VERSION ""

NS_ :

BS_:

BU_: Device Host

BO_ 2582846206 IoStatusFaultCountFD: 64 Device
 SG_ FaultCountStatus_01 : 0|16@1+ (1,0) [0|64255] ""  Host
 SG_ FaultCountStatus_02 : 16|16@1+ (1,0) [0|64255] ""  Host
 SG_ FaultCountStatus_03 : 32|16@1+ (1,0) [0|64255] ""  Host
 SG_ FaultCountStatus_04 : 48|16@1+ (1,0) [0|64255] ""  Host
 SG_ FaultCountStatus_05 : 64|16@1+ (1,0) [0|64255] ""  Host
 SG_ FaultCountStatus_06 : 80|16@1+ (1,0) [0|64255] ""  Host
 SG_ FaultCountStatus_07 : 96|16@1+ (1,0) [0|64255] ""  Host
 SG_ FaultCountStatus_08 : 112|16@1+ (1,0) [0|64255] ""  Host
 SG_ FaultCountStatus_09 : 128|16@1+ (1,0) [0|64255] ""  Host
 SG_ FaultCountStatus_10 : 144|16@1+ (1,0) [0|64255] ""  Host
 SG_ FaultCountStatus_11 : 160|16@1+ (1,0) [0|64255] ""  Host
 SG_ FaultCountStatus_12 : 176|16@1+ (1,0) [0|64255] ""  Host
 SG_ FaultCountStatus_13 : 192|16@1+ (1,0) [0|64255] ""  Host
 SG_ FaultCountStatus_14 : 208|16@1+ (1,0) [0|64255] ""  Host
 SG_ FaultCountStatus_15 : 224|16@1+ (1,0) [0|64255] ""  Host
 SG_ FaultCountStatus_16 : 240|16@1+ (1,0) [0|64255] ""  Host
 SG_ FaultCountStatus_17 : 256|16@1+ (1,0) [0|64255] ""  Host
 SG_ FaultCountStatus_18 : 272|16@1+ (1,0) [0|64255] ""  Host
 SG_ FaultCountStatus_19 : 288|16@1+ (1,0) [0|64255] ""  Host
 SG_ FaultCountStatus_20 : 304|16@1+ (1,0) [0|64255] ""  Host
 SG_ FaultCountStatus_21 : 320|16@1+ (1,0) [0|64255] ""  Host
 SG_ FaultCountStatus_22 : 336|16@1+ (1,0) [0|64255] ""  Host
 SG_ FaultCountStatus_23 : 352|16@1+ (1,0) [0|64255] ""  Host
 SG_ FaultCountStatus_24 : 368|16@1+ (1,0) [0|64255] ""  Host
 SG_ FaultCountStatus_25 : 384|16@1+ (1,0) [0|64255] ""  Host
 SG_ FaultCountStatus_26 : 400|16@1+ (1,0) [0|64255] ""  Host
 SG_ FaultCountStatus_27 : 416|16@1+ (1,0) [0|64255] ""  Host
 SG_ FaultCountStatus_28 : 432|16@1+ (1,0) [0|64255] ""  Host
 SG_ FaultCountStatus_29 : 448|16@1+ (1,0) [0|64255] ""  Host
 SG_ FaultCountStatus_30 : 464|16@1+ (1,0) [0|64255] ""  Host
 SG_ FaultCountStatus_31 : 480|16@1+ (1,0) [0|64255] ""  Host
 SG_ FaultCountStatus_32 : 496|16@1+ (1,0) [0|64255] ""  Host

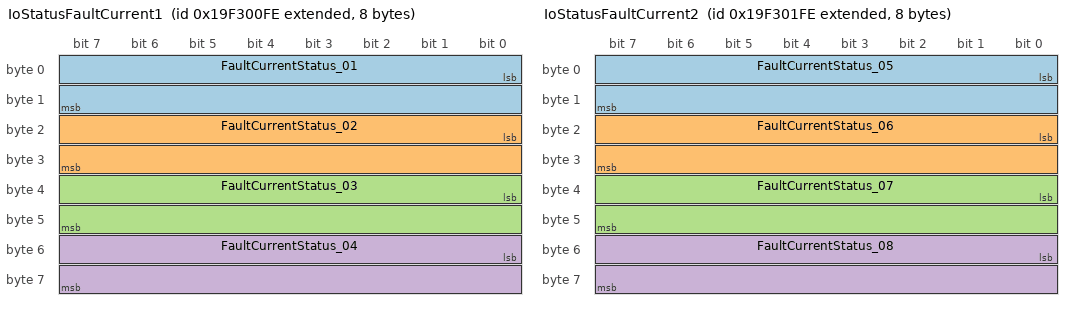
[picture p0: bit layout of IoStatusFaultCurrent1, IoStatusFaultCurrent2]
BO_ 2582839550 IoStatusFaultCurrent1: 8 Device
 SG_ FaultCurrentStatus_01 : 0|16@1+ (0.01,-320) [-320|320] "A"  Host
 SG_ FaultCurrentStatus_02 : 16|16@1+ (0.01,-320) [-320|320] "A"  Host
 SG_ FaultCurrentStatus_03 : 32|16@1+ (0.01,-320) [-320|320] "A"  Host
 SG_ FaultCurrentStatus_04 : 48|16@1+ (0.01,-320) [-320|320] "A"  Host

BO_ 2582839806 IoStatusFaultCurrent2: 8 Device
 SG_ FaultCurrentStatus_05 : 0|16@1+ (0.01,-320) [-320|320] "A"  Host
 SG_ FaultCurrentStatus_06 : 16|16@1+ (0.01,-320) [-320|320] "A"  Host
 SG_ FaultCurrentStatus_07 : 32|16@1+ (0.01,-320) [-320|320] "A"  Host
 SG_ FaultCurrentStatus_08 : 48|16@1+ (0.01,-320) [-320|320] "A"  Host

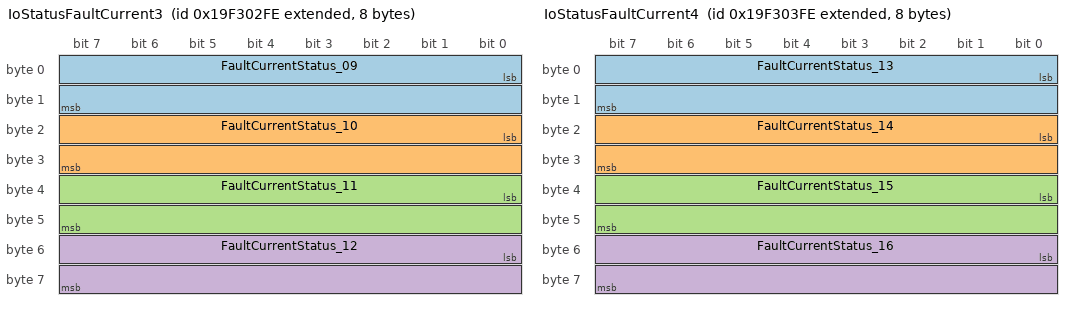
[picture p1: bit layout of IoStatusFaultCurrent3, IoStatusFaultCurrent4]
BO_ 2582840062 IoStatusFaultCurrent3: 8 Device
 SG_ FaultCurrentStatus_09 : 0|16@1+ (0.01,-320) [-320|320] "A"  Host
 SG_ FaultCurrentStatus_10 : 16|16@1+ (0.01,-320) [-320|320] "A"  Host
 SG_ FaultCurrentStatus_11 : 32|16@1+ (0.01,-320) [-320|320] "A"  Host
 SG_ FaultCurrentStatus_12 : 48|16@1+ (0.01,-320) [-320|320] "A"  Host

BO_ 2582840318 IoStatusFaultCurrent4: 8 Device
 SG_ FaultCurrentStatus_13 : 0|16@1+ (0.01,-320) [-320|320] "A"  Host
 SG_ FaultCurrentStatus_14 : 16|16@1+ (0.01,-320) [-320|320] "A"  Host
 SG_ FaultCurrentStatus_15 : 32|16@1+ (0.01,-320) [-320|320] "A"  Host
 SG_ FaultCurrentStatus_16 : 48|16@1+ (0.01,-320) [-320|320] "A"  Host

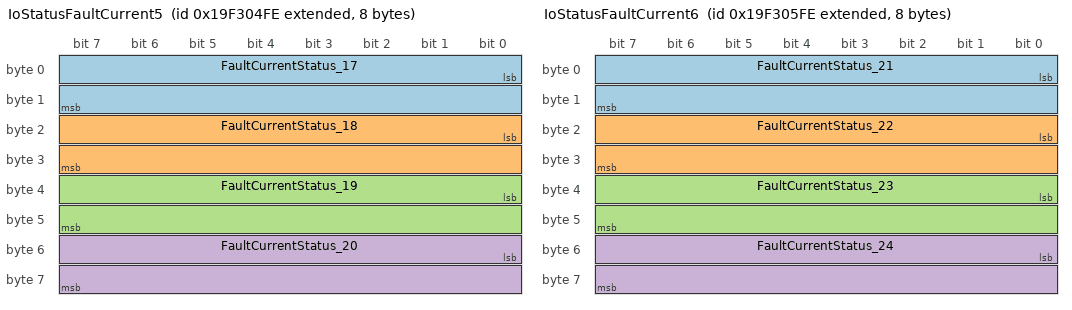
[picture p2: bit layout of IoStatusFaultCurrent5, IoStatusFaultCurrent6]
BO_ 2582840574 IoStatusFaultCurrent5: 8 Device
 SG_ FaultCurrentStatus_17 : 0|16@1+ (0.01,-320) [-320|320] "A"  Host
 SG_ FaultCurrentStatus_18 : 16|16@1+ (0.01,-320) [-320|320] "A"  Host
 SG_ FaultCurrentStatus_19 : 32|16@1+ (0.01,-320) [-320|320] "A"  Host
 SG_ FaultCurrentStatus_20 : 48|16@1+ (0.01,-320) [-320|320] "A"  Host

BO_ 2582840830 IoStatusFaultCurrent6: 8 Device
 SG_ FaultCurrentStatus_21 : 0|16@1+ (0.01,-320) [-320|320] "A"  Host
 SG_ FaultCurrentStatus_22 : 16|16@1+ (0.01,-320) [-320|320] "A"  Host
 SG_ FaultCurrentStatus_23 : 32|16@1+ (0.01,-320) [-320|320] "A"  Host
 SG_ FaultCurrentStatus_24 : 48|16@1+ (0.01,-320) [-320|320] "A"  Host

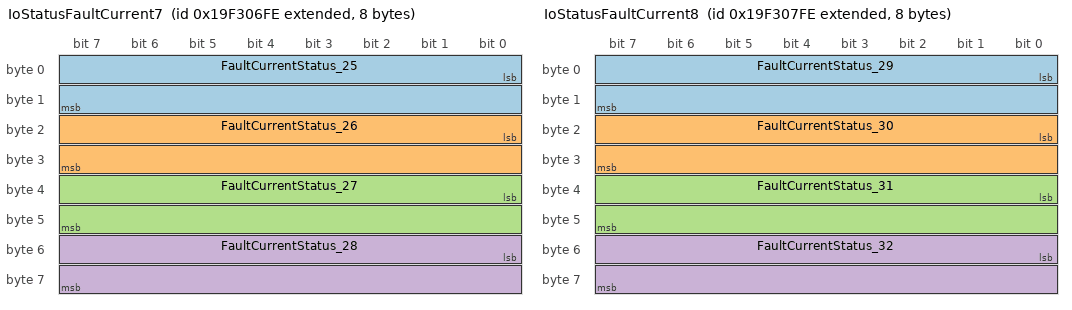
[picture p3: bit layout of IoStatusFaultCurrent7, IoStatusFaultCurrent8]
BO_ 2582841086 IoStatusFaultCurrent7: 8 Device
 SG_ FaultCurrentStatus_25 : 0|16@1+ (0.01,-320) [-320|320] "A"  Host
 SG_ FaultCurrentStatus_26 : 16|16@1+ (0.01,-320) [-320|320] "A"  Host
 SG_ FaultCurrentStatus_27 : 32|16@1+ (0.01,-320) [-320|320] "A"  Host
 SG_ FaultCurrentStatus_28 : 48|16@1+ (0.01,-320) [-320|320] "A"  Host

BO_ 2582841342 IoStatusFaultCurrent8: 8 Device
 SG_ FaultCurrentStatus_29 : 0|16@1+ (0.01,-320) [-320|320] "A"  Host
 SG_ FaultCurrentStatus_30 : 16|16@1+ (0.01,-320) [-320|320] "A"  Host
 SG_ FaultCurrentStatus_31 : 32|16@1+ (0.01,-320) [-320|320] "A"  Host
 SG_ FaultCurrentStatus_32 : 48|16@1+ (0.01,-320) [-320|320] "A"  Host

BO_ 2582846462 IoStatusFaultCurrentFD: 64 Device
 SG_ FaultCurrentStatus_01 : 0|16@1+ (0.01,-320) [-320|320] "A"  Host
 SG_ FaultCurrentStatus_02 : 16|16@1+ (0.01,-320) [-320|320] "A"  Host
 SG_ FaultCurrentStatus_03 : 32|16@1+ (0.01,-320) [-320|320] "A"  Host
 SG_ FaultCurrentStatus_04 : 48|16@1+ (0.01,-320) [-320|320] "A"  Host
 SG_ FaultCurrentStatus_05 : 64|16@1+ (0.01,-320) [-320|320] "A"  Host
 SG_ FaultCurrentStatus_06 : 80|16@1+ (0.01,-320) [-320|320] "A"  Host
 SG_ FaultCurrentStatus_07 : 96|16@1+ (0.01,-320) [-320|320] "A"  Host
 SG_ FaultCurrentStatus_08 : 112|16@1+ (0.01,-320) [-320|320] "A"  Host
 SG_ FaultCurrentStatus_09 : 128|16@1+ (0.01,-320) [-320|320] "A"  Host
 SG_ FaultCurrentStatus_10 : 144|16@1+ (0.01,-320) [-320|320] "A"  Host
 SG_ FaultCurrentStatus_11 : 160|16@1+ (0.01,-320) [-320|320] "A"  Host
 SG_ FaultCurrentStatus_12 : 176|16@1+ (0.01,-320) [-320|320] "A"  Host
 SG_ FaultCurrentStatus_13 : 192|16@1+ (0.01,-320) [-320|320] "A"  Host
 SG_ FaultCurrentStatus_14 : 208|16@1+ (0.01,-320) [-320|320] "A"  Host
 SG_ FaultCurrentStatus_15 : 224|16@1+ (0.01,-320) [-320|320] "A"  Host
 SG_ FaultCurrentStatus_16 : 240|16@1+ (0.01,-320) [-320|320] "A"  Host
 SG_ FaultCurrentStatus_17 : 256|16@1+ (0.01,-320) [-320|320] "A"  Host
 SG_ FaultCurrentStatus_18 : 272|16@1+ (0.01,-320) [-320|320] "A"  Host
 SG_ FaultCurrentStatus_19 : 288|16@1+ (0.01,-320) [-320|320] "A"  Host
 SG_ FaultCurrentStatus_20 : 304|16@1+ (0.01,-320) [-320|320] "A"  Host
 SG_ FaultCurrentStatus_21 : 320|16@1+ (0.01,-320) [-320|320] "A"  Host
 SG_ FaultCurrentStatus_22 : 336|16@1+ (0.01,-320) [-320|320] "A"  Host
 SG_ FaultCurrentStatus_23 : 352|16@1+ (0.01,-320) [-320|320] "A"  Host
 SG_ FaultCurrentStatus_24 : 368|16@1+ (0.01,-320) [-320|320] "A"  Host
 SG_ FaultCurrentStatus_25 : 384|16@1+ (0.01,-320) [-320|320] "A"  Host
 SG_ FaultCurrentStatus_26 : 400|16@1+ (0.01,-320) [-320|320] "A"  Host
 SG_ FaultCurrentStatus_27 : 416|16@1+ (0.01,-320) [-320|320] "A"  Host
 SG_ FaultCurrentStatus_28 : 432|16@1+ (0.01,-320) [-320|320] "A"  Host
 SG_ FaultCurrentStatus_29 : 448|16@1+ (0.01,-320) [-320|320] "A"  Host
 SG_ FaultCurrentStatus_30 : 464|16@1+ (0.01,-320) [-320|320] "A"  Host
 SG_ FaultCurrentStatus_31 : 480|16@1+ (0.01,-320) [-320|320] "A"  Host
 SG_ FaultCurrentStatus_32 : 496|16@1+ (0.01,-320) [-320|320] "A"  Host

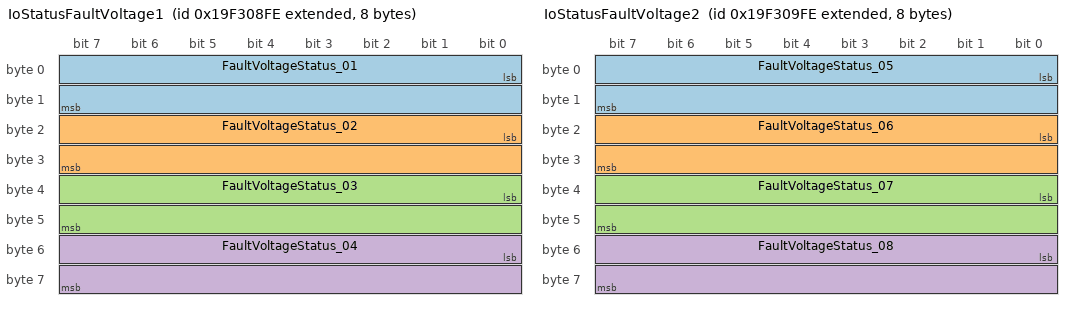
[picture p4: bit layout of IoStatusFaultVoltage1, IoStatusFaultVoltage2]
BO_ 2582841598 IoStatusFaultVoltage1: 8 Device
 SG_ FaultVoltageStatus_01 : 0|16@1+ (0.001,0) [0|64.255] "V"  Host
 SG_ FaultVoltageStatus_02 : 16|16@1+ (0.001,0) [0|64.255] "V"  Host
 SG_ FaultVoltageStatus_03 : 32|16@1+ (0.001,0) [0|64.255] "V"  Host
 SG_ FaultVoltageStatus_04 : 48|16@1+ (0.001,0) [0|64.255] "V"  Host

BO_ 2582841854 IoStatusFaultVoltage2: 8 Device
 SG_ FaultVoltageStatus_05 : 0|16@1+ (0.001,0) [0|64.255] "V"  Host
 SG_ FaultVoltageStatus_06 : 16|16@1+ (0.001,0) [0|64.255] "V"  Host
 SG_ FaultVoltageStatus_07 : 32|16@1+ (0.001,0) [0|64.255] "V"  Host
 SG_ FaultVoltageStatus_08 : 48|16@1+ (0.001,0) [0|64.255] "V"  Host

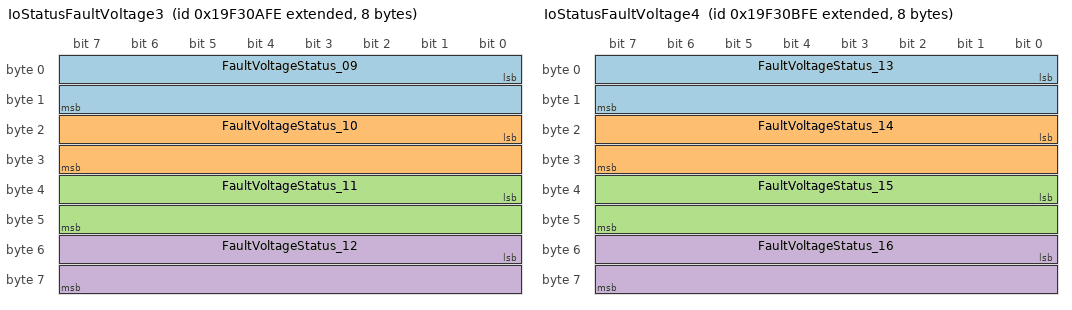
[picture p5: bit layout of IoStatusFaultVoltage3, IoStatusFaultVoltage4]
BO_ 2582842110 IoStatusFaultVoltage3: 8 Device
 SG_ FaultVoltageStatus_09 : 0|16@1+ (0.001,0) [0|64.255] "V"  Host
 SG_ FaultVoltageStatus_10 : 16|16@1+ (0.001,0) [0|64.255] "V"  Host
 SG_ FaultVoltageStatus_11 : 32|16@1+ (0.001,0) [0|64.255] "V"  Host
 SG_ FaultVoltageStatus_12 : 48|16@1+ (0.001,0) [0|64.255] "V"  Host

BO_ 2582842366 IoStatusFaultVoltage4: 8 Device
 SG_ FaultVoltageStatus_13 : 0|16@1+ (0.001,0) [0|64.255] "V"  Host
 SG_ FaultVoltageStatus_14 : 16|16@1+ (0.001,0) [0|64.255] "V"  Host
 SG_ FaultVoltageStatus_15 : 32|16@1+ (0.001,0) [0|64.255] "V"  Host
 SG_ FaultVoltageStatus_16 : 48|16@1+ (0.001,0) [0|64.255] "V"  Host

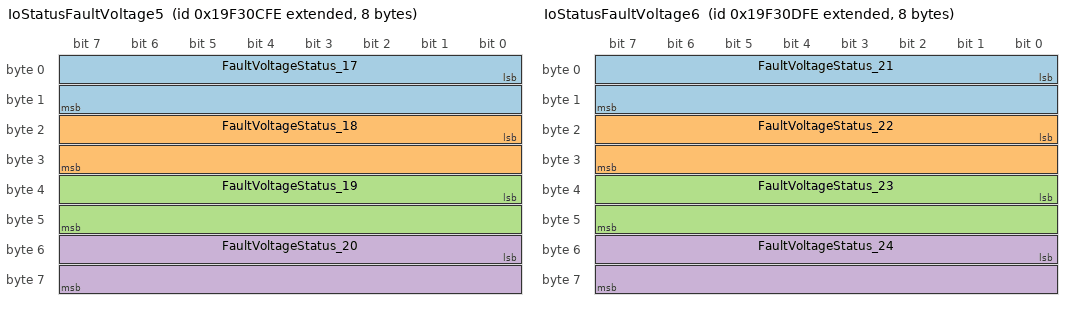
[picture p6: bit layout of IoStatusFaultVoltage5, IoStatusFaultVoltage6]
BO_ 2582842622 IoStatusFaultVoltage5: 8 Device
 SG_ FaultVoltageStatus_17 : 0|16@1+ (0.001,0) [0|64.255] "V"  Host
 SG_ FaultVoltageStatus_18 : 16|16@1+ (0.001,0) [0|64.255] "V"  Host
 SG_ FaultVoltageStatus_19 : 32|16@1+ (0.001,0) [0|64.255] "V"  Host
 SG_ FaultVoltageStatus_20 : 48|16@1+ (0.001,0) [0|64.255] "V"  Host

BO_ 2582842878 IoStatusFaultVoltage6: 8 Device
 SG_ FaultVoltageStatus_21 : 0|16@1+ (0.001,0) [0|64.255] "V"  Host
 SG_ FaultVoltageStatus_22 : 16|16@1+ (0.001,0) [0|64.255] "V"  Host
 SG_ FaultVoltageStatus_23 : 32|16@1+ (0.001,0) [0|64.255] "V"  Host
 SG_ FaultVoltageStatus_24 : 48|16@1+ (0.001,0) [0|64.255] "V"  Host

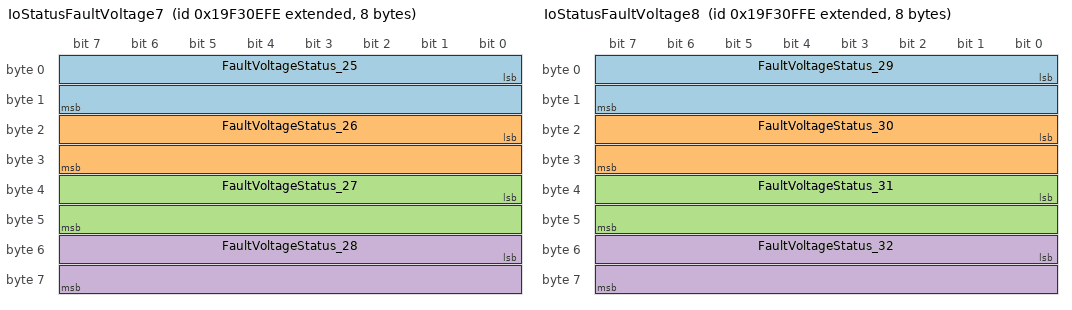
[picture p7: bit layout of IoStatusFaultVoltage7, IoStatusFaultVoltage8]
BO_ 2582843134 IoStatusFaultVoltage7: 8 Device
 SG_ FaultVoltageStatus_25 : 0|16@1+ (0.001,0) [0|64.255] "V"  Host
 SG_ FaultVoltageStatus_26 : 16|16@1+ (0.001,0) [0|64.255] "V"  Host
 SG_ FaultVoltageStatus_27 : 32|16@1+ (0.001,0) [0|64.255] "V"  Host
 SG_ FaultVoltageStatus_28 : 48|16@1+ (0.001,0) [0|64.255] "V"  Host

BO_ 2582843390 IoStatusFaultVoltage8: 8 Device
 SG_ FaultVoltageStatus_29 : 0|16@1+ (0.001,0) [0|64.255] "V"  Host
 SG_ FaultVoltageStatus_30 : 16|16@1+ (0.001,0) [0|64.255] "V"  Host
 SG_ FaultVoltageStatus_31 : 32|16@1+ (0.001,0) [0|64.255] "V"  Host
 SG_ FaultVoltageStatus_32 : 48|16@1+ (0.001,0) [0|64.255] "V"  Host

BO_ 2582846718 IoStatusFaultVoltageFD: 64 Device
 SG_ FaultVoltageStatus_01 : 0|16@1+ (0.001,0) [0|64.255] "V"  Host
 SG_ FaultVoltageStatus_02 : 16|16@1+ (0.001,0) [0|64.255] "V"  Host
 SG_ FaultVoltageStatus_03 : 32|16@1+ (0.001,0) [0|64.255] "V"  Host
 SG_ FaultVoltageStatus_04 : 48|16@1+ (0.001,0) [0|64.255] "V"  Host
 SG_ FaultVoltageStatus_05 : 64|16@1+ (0.001,0) [0|64.255] "V"  Host
 SG_ FaultVoltageStatus_06 : 80|16@1+ (0.001,0) [0|64.255] "V"  Host
 SG_ FaultVoltageStatus_07 : 96|16@1+ (0.001,0) [0|64.255] "V"  Host
 SG_ FaultVoltageStatus_08 : 112|16@1+ (0.001,0) [0|64.255] "V"  Host
 SG_ FaultVoltageStatus_09 : 128|16@1+ (0.001,0) [0|64.255] "V"  Host
 SG_ FaultVoltageStatus_10 : 144|16@1+ (0.001,0) [0|64.255] "V"  Host
 SG_ FaultVoltageStatus_11 : 160|16@1+ (0.001,0) [0|64.255] "V"  Host
 SG_ FaultVoltageStatus_12 : 176|16@1+ (0.001,0) [0|64.255] "V"  Host
 SG_ FaultVoltageStatus_13 : 192|16@1+ (0.001,0) [0|64.255] "V"  Host
 SG_ FaultVoltageStatus_14 : 208|16@1+ (0.001,0) [0|64.255] "V"  Host
 SG_ FaultVoltageStatus_15 : 224|16@1+ (0.001,0) [0|64.255] "V"  Host
 SG_ FaultVoltageStatus_16 : 240|16@1+ (0.001,0) [0|64.255] "V"  Host
 SG_ FaultVoltageStatus_17 : 256|16@1+ (0.001,0) [0|64.255] "V"  Host
 SG_ FaultVoltageStatus_18 : 272|16@1+ (0.001,0) [0|64.255] "V"  Host
 SG_ FaultVoltageStatus_19 : 288|16@1+ (0.001,0) [0|64.255] "V"  Host
 SG_ FaultVoltageStatus_20 : 304|16@1+ (0.001,0) [0|64.255] "V"  Host
 SG_ FaultVoltageStatus_21 : 320|16@1+ (0.001,0) [0|64.255] "V"  Host
 SG_ FaultVoltageStatus_22 : 336|16@1+ (0.001,0) [0|64.255] "V"  Host
 SG_ FaultVoltageStatus_23 : 352|16@1+ (0.001,0) [0|64.255] "V"  Host
 SG_ FaultVoltageStatus_24 : 368|16@1+ (0.001,0) [0|64.255] "V"  Host
 SG_ FaultVoltageStatus_25 : 384|16@1+ (0.001,0) [0|64.255] "V"  Host
 SG_ FaultVoltageStatus_26 : 400|16@1+ (0.001,0) [0|64.255] "V"  Host
 SG_ FaultVoltageStatus_27 : 416|16@1+ (0.001,0) [0|64.255] "V"  Host
 SG_ FaultVoltageStatus_28 : 432|16@1+ (0.001,0) [0|64.255] "V"  Host
 SG_ FaultVoltageStatus_29 : 448|16@1+ (0.001,0) [0|64.255] "V"  Host
 SG_ FaultVoltageStatus_30 : 464|16@1+ (0.001,0) [0|64.255] "V"  Host
 SG_ FaultVoltageStatus_31 : 480|16@1+ (0.001,0) [0|64.255] "V"  Host
 SG_ FaultVoltageStatus_32 : 496|16@1+ (0.001,0) [0|64.255] "V"  Host

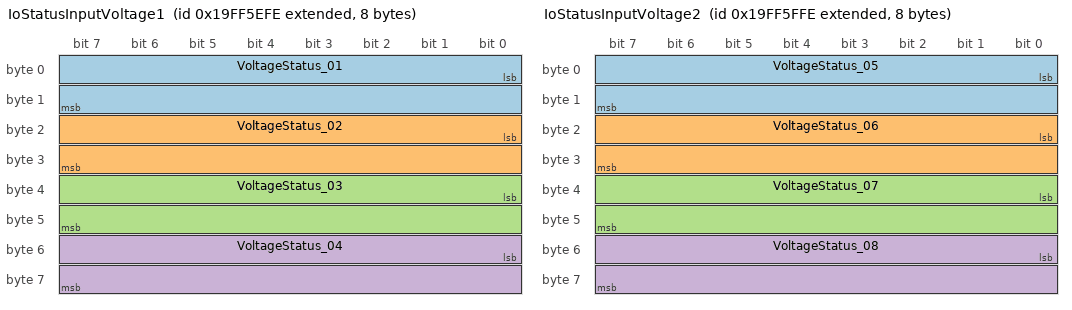
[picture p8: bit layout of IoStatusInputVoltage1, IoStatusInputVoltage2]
BO_ 2583650046 IoStatusInputVoltage1: 8 Device
 SG_ VoltageStatus_01 : 0|16@1+ (0.001,0) [0|64.255] "V"  Host
 SG_ VoltageStatus_02 : 16|16@1+ (0.001,0) [0|64.255] "V"  Host
 SG_ VoltageStatus_03 : 32|16@1+ (0.001,0) [0|64.255] "V"  Host
 SG_ VoltageStatus_04 : 48|16@1+ (0.001,0) [0|64.255] "V"  Host

BO_ 2583650302 IoStatusInputVoltage2: 8 Device
 SG_ VoltageStatus_05 : 0|16@1+ (0.001,0) [0|64.255] "V"  Host
 SG_ VoltageStatus_06 : 16|16@1+ (0.001,0) [0|64.255] "V"  Host
 SG_ VoltageStatus_07 : 32|16@1+ (0.001,0) [0|64.255] "V"  Host
 SG_ VoltageStatus_08 : 48|16@1+ (0.001,0) [0|64.255] "V"  Host

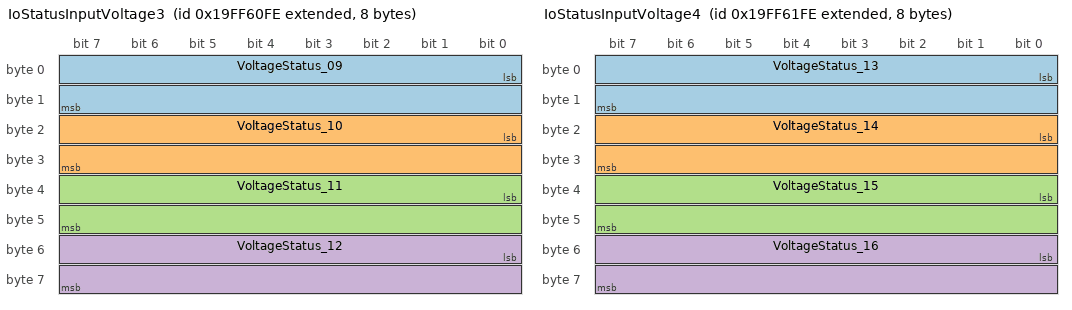
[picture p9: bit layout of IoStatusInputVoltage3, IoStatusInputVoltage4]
BO_ 2583650558 IoStatusInputVoltage3: 8 Device
 SG_ VoltageStatus_09 : 0|16@1+ (0.001,0) [0|64.255] "V"  Host
 SG_ VoltageStatus_10 : 16|16@1+ (0.001,0) [0|64.255] "V"  Host
 SG_ VoltageStatus_11 : 32|16@1+ (0.001,0) [0|64.255] "V"  Host
 SG_ VoltageStatus_12 : 48|16@1+ (0.001,0) [0|64.255] "V"  Host

BO_ 2583650814 IoStatusInputVoltage4: 8 Device
 SG_ VoltageStatus_13 : 0|16@1+ (0.001,0) [0|64.255] "V"  Host
 SG_ VoltageStatus_14 : 16|16@1+ (0.001,0) [0|64.255] "V"  Host
 SG_ VoltageStatus_15 : 32|16@1+ (0.001,0) [0|64.255] "V"  Host
 SG_ VoltageStatus_16 : 48|16@1+ (0.001,0) [0|64.255] "V"  Host

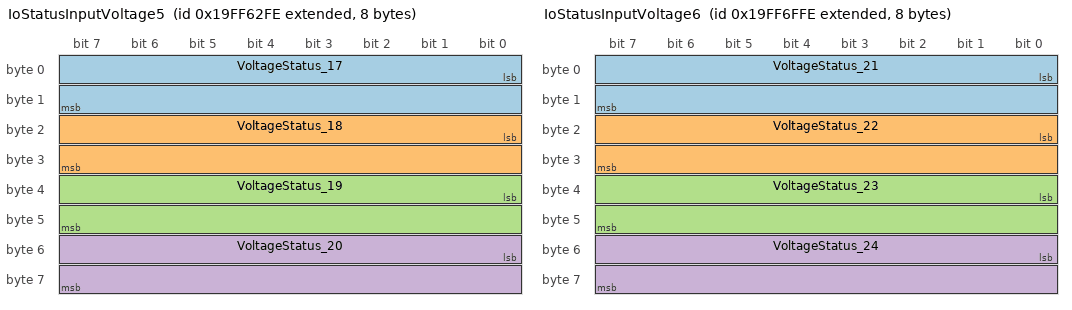
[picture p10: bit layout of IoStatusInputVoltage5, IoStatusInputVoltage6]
BO_ 2583651070 IoStatusInputVoltage5: 8 Device
 SG_ VoltageStatus_17 : 0|16@1+ (0.001,0) [0|64.255] "V"  Host
 SG_ VoltageStatus_18 : 16|16@1+ (0.001,0) [0|64.255] "V"  Host
 SG_ VoltageStatus_19 : 32|16@1+ (0.001,0) [0|64.255] "V"  Host
 SG_ VoltageStatus_20 : 48|16@1+ (0.001,0) [0|64.255] "V"  Host

BO_ 2583654398 IoStatusInputVoltage6: 8 Device
 SG_ VoltageStatus_21 : 0|16@1+ (0.001,0) [0|64.255] "V"  Host
 SG_ VoltageStatus_22 : 16|16@1+ (0.001,0) [0|64.255] "V"  Host
 SG_ VoltageStatus_23 : 32|16@1+ (0.001,0) [0|64.255] "V"  Host
 SG_ VoltageStatus_24 : 48|16@1+ (0.001,0) [0|64.255] "V"  Host

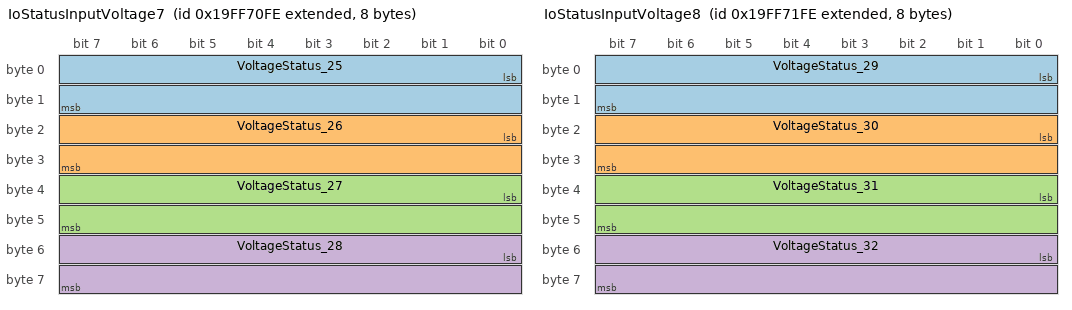
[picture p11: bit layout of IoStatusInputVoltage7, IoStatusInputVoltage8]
BO_ 2583654654 IoStatusInputVoltage7: 8 Device
 SG_ VoltageStatus_25 : 0|16@1+ (0.001,0) [0|64.255] "V"  Host
 SG_ VoltageStatus_26 : 16|16@1+ (0.001,0) [0|64.255] "V"  Host
 SG_ VoltageStatus_27 : 32|16@1+ (0.001,0) [0|64.255] "V"  Host
 SG_ VoltageStatus_28 : 48|16@1+ (0.001,0) [0|64.255] "V"  Host

BO_ 2583654910 IoStatusInputVoltage8: 8 Device
 SG_ VoltageStatus_29 : 0|16@1+ (0.001,0) [0|64.255] "V"  Host
 SG_ VoltageStatus_30 : 16|16@1+ (0.001,0) [0|64.255] "V"  Host
 SG_ VoltageStatus_31 : 32|16@1+ (0.001,0) [0|64.255] "V"  Host
 SG_ VoltageStatus_32 : 48|16@1+ (0.001,0) [0|64.255] "V"  Host

BO_ 2582845694 IoStatusInputVoltageFD: 64 Device
 SG_ VoltageStatus_01 : 0|16@1+ (0.001,0) [0|64.255] "V"  Host
 SG_ VoltageStatus_02 : 16|16@1+ (0.001,0) [0|64.255] "V"  Host
 SG_ VoltageStatus_03 : 32|16@1+ (0.001,0) [0|64.255] "V"  Host
 SG_ VoltageStatus_04 : 48|16@1+ (0.001,0) [0|64.255] "V"  Host
 SG_ VoltageStatus_05 : 64|16@1+ (0.001,0) [0|64.255] "V"  Host
 SG_ VoltageStatus_06 : 80|16@1+ (0.001,0) [0|64.255] "V"  Host
 SG_ VoltageStatus_07 : 96|16@1+ (0.001,0) [0|64.255] "V"  Host
 SG_ VoltageStatus_08 : 112|16@1+ (0.001,0) [0|64.255] "V"  Host
 SG_ VoltageStatus_09 : 128|16@1+ (0.001,0) [0|64.255] "V"  Host
 SG_ VoltageStatus_10 : 144|16@1+ (0.001,0) [0|64.255] "V"  Host
 SG_ VoltageStatus_11 : 160|16@1+ (0.001,0) [0|64.255] "V"  Host
 SG_ VoltageStatus_12 : 176|16@1+ (0.001,0) [0|64.255] "V"  Host
 SG_ VoltageStatus_13 : 192|16@1+ (0.001,0) [0|64.255] "V"  Host
 SG_ VoltageStatus_14 : 208|16@1+ (0.001,0) [0|64.255] "V"  Host
 SG_ VoltageStatus_15 : 224|16@1+ (0.001,0) [0|64.255] "V"  Host
 SG_ VoltageStatus_16 : 240|16@1+ (0.001,0) [0|64.255] "V"  Host
 SG_ VoltageStatus_17 : 256|16@1+ (0.001,0) [0|64.255] "V"  Host
 SG_ VoltageStatus_18 : 272|16@1+ (0.001,0) [0|64.255] "V"  Host
 SG_ VoltageStatus_19 : 288|16@1+ (0.001,0) [0|64.255] "V"  Host
 SG_ VoltageStatus_20 : 304|16@1+ (0.001,0) [0|64.255] "V"  Host
 SG_ VoltageStatus_21 : 320|16@1+ (0.001,0) [0|64.255] "V"  Host
 SG_ VoltageStatus_22 : 336|16@1+ (0.001,0) [0|64.255] "V"  Host
 SG_ VoltageStatus_23 : 352|16@1+ (0.001,0) [0|64.255] "V"  Host
 SG_ VoltageStatus_24 : 368|16@1+ (0.001,0) [0|64.255] "V"  Host
 SG_ VoltageStatus_25 : 384|16@1+ (0.001,0) [0|64.255] "V"  Host
 SG_ VoltageStatus_26 : 400|16@1+ (0.001,0) [0|64.255] "V"  Host
 SG_ VoltageStatus_27 : 416|16@1+ (0.001,0) [0|64.255] "V"  Host
 SG_ VoltageStatus_28 : 432|16@1+ (0.001,0) [0|64.255] "V"  Host
 SG_ VoltageStatus_29 : 448|16@1+ (0.001,0) [0|64.255] "V"  Host
 SG_ VoltageStatus_30 : 464|16@1+ (0.001,0) [0|64.255] "V"  Host
 SG_ VoltageStatus_31 : 480|16@1+ (0.001,0) [0|64.255] "V"  Host
 SG_ VoltageStatus_32 : 496|16@1+ (0.001,0) [0|64.255] "V"  Host

BO_ 2583646718 IoStatusPinMode1: 8 Device
 SG_ PinModeStatus_01 : 0|4@1+ (1,0) [0|0] ""  Host
 SG_ PinPullModeStatus_01 : 4|2@1+ (1,0) [0|0] ""  Host
 SG_ LoadDetectionStatus_01 : 6|2@1+ (1,0) [0|0] ""  Host
 SG_ PinModeStatus_02 : 8|4@1+ (1,0) [0|0] ""  Host
 SG_ PinPullModeStatus_02 : 12|2@1+ (1,0) [0|0] ""  Host
 SG_ LoadDetectionStatus_02 : 14|2@1+ (1,0) [0|0] ""  Host
 SG_ PinModeStatus_03 : 16|4@1+ (1,0) [0|0] ""  Host
 SG_ PinPullModeStatus_03 : 20|2@1+ (1,0) [0|0] ""  Host
 SG_ LoadDetectionStatus_03 : 22|2@1+ (1,0) [0|0] ""  Host
 SG_ PinModeStatus_04 : 24|4@1+ (1,0) [0|0] ""  Host
 SG_ PinPullModeStatus_04 : 28|2@1+ (1,0) [0|0] ""  Host
 SG_ LoadDetectionStatus_04 : 30|2@1+ (1,0) [0|0] ""  Host
 SG_ PinModeStatus_05 : 32|4@1+ (1,0) [0|0] ""  Host
 SG_ PinPullModeStatus_05 : 36|2@1+ (1,0) [0|0] ""  Host
 SG_ LoadDetectionStatus_05 : 38|2@1+ (1,0) [0|0] ""  Host
 SG_ PinModeStatus_06 : 40|4@1+ (1,0) [0|0] ""  Host
 SG_ PinPullModeStatus_06 : 44|2@1+ (1,0) [0|0] ""  Host
 SG_ LoadDetectionStatus_06 : 46|2@1+ (1,0) [0|0] ""  Host
 SG_ PinModeStatus_07 : 48|4@1+ (1,0) [0|0] ""  Host
 SG_ PinPullModeStatus_07 : 52|2@1+ (1,0) [0|0] ""  Host
 SG_ LoadDetectionStatus_07 : 54|2@1+ (1,0) [0|0] ""  Host
 SG_ PinModeStatus_08 : 56|4@1+ (1,0) [0|0] ""  Host
 SG_ PinPullModeStatus_08 : 60|2@1+ (1,0) [0|0] ""  Host
 SG_ LoadDetectionStatus_08 : 62|2@1+ (1,0) [0|0] ""  Host

BO_ 2583646974 IoStatusPinMode2: 8 Device
 SG_ PinModeStatus_09 : 0|4@1+ (1,0) [0|0] ""  Host
 SG_ PinPullModeStatus_09 : 4|2@1+ (1,0) [0|0] ""  Host
 SG_ LoadDetectionStatus_09 : 6|2@1+ (1,0) [0|0] ""  Host
 SG_ PinModeStatus_10 : 8|4@1+ (1,0) [0|0] ""  Host
 SG_ PinPullModeStatus_10 : 12|2@1+ (1,0) [0|0] ""  Host
 SG_ LoadDetectionStatus_10 : 14|2@1+ (1,0) [0|0] ""  Host
 SG_ PinModeStatus_11 : 16|4@1+ (1,0) [0|0] ""  Host
 SG_ PinPullModeStatus_11 : 20|2@1+ (1,0) [0|0] ""  Host
 SG_ LoadDetectionStatus_11 : 22|2@1+ (1,0) [0|0] ""  Host
 SG_ PinModeStatus_12 : 24|4@1+ (1,0) [0|0] ""  Host
 SG_ PinPullModeStatus_12 : 28|2@1+ (1,0) [0|0] ""  Host
 SG_ LoadDetectionStatus_12 : 30|2@1+ (1,0) [0|0] ""  Host
 SG_ PinModeStatus_13 : 32|4@1+ (1,0) [0|0] ""  Host
 SG_ PinPullModeStatus_13 : 36|2@1+ (1,0) [0|0] ""  Host
 SG_ LoadDetectionStatus_13 : 38|2@1+ (1,0) [0|0] ""  Host
 SG_ PinModeStatus_14 : 40|4@1+ (1,0) [0|0] ""  Host
 SG_ PinPullModeStatus_14 : 44|2@1+ (1,0) [0|0] ""  Host
 SG_ LoadDetectionStatus_14 : 46|2@1+ (1,0) [0|0] ""  Host
 SG_ PinModeStatus_15 : 48|4@1+ (1,0) [0|0] ""  Host
 SG_ PinPullModeStatus_15 : 52|2@1+ (1,0) [0|0] ""  Host
 SG_ LoadDetectionStatus_15 : 54|2@1+ (1,0) [0|0] ""  Host
 SG_ PinModeStatus_16 : 56|4@1+ (1,0) [0|0] ""  Host
 SG_ PinPullModeStatus_16 : 60|2@1+ (1,0) [0|0] ""  Host
 SG_ LoadDetectionStatus_16 : 62|2@1+ (1,0) [0|0] ""  Host

BO_ 2583647230 IoStatusPinMode3: 8 Device
 SG_ PinModeStatus_17 : 0|4@1+ (1,0) [0|0] ""  Host
 SG_ PinPullModeStatus_17 : 4|2@1+ (1,0) [0|0] ""  Host
 SG_ LoadDetectionStatus_17 : 6|2@1+ (1,0) [0|0] ""  Host
 SG_ PinModeStatus_18 : 8|4@1+ (1,0) [0|0] ""  Host
 SG_ PinPullModeStatus_18 : 12|2@1+ (1,0) [0|0] ""  Host
 SG_ LoadDetectionStatus_18 : 14|2@1+ (1,0) [0|0] ""  Host
 SG_ PinModeStatus_19 : 16|4@1+ (1,0) [0|0] ""  Host
 SG_ PinPullModeStatus_19 : 20|2@1+ (1,0) [0|0] ""  Host
 SG_ LoadDetectionStatus_19 : 22|2@1+ (1,0) [0|0] ""  Host
 SG_ PinModeStatus_20 : 24|4@1+ (1,0) [0|0] ""  Host
 SG_ PinPullModeStatus_20 : 28|2@1+ (1,0) [0|0] ""  Host
 SG_ LoadDetectionStatus_20 : 30|2@1+ (1,0) [0|0] ""  Host
 SG_ PinModeStatus_21 : 32|4@1+ (1,0) [0|0] ""  Host
 SG_ PinPullModeStatus_21 : 36|2@1+ (1,0) [0|0] ""  Host
 SG_ LoadDetectionStatus_21 : 38|2@1+ (1,0) [0|0] ""  Host
 SG_ PinModeStatus_22 : 40|4@1+ (1,0) [0|0] ""  Host
 SG_ PinPullModeStatus_22 : 44|2@1+ (1,0) [0|0] ""  Host
 SG_ LoadDetectionStatus_22 : 46|2@1+ (1,0) [0|0] ""  Host
 SG_ PinModeStatus_23 : 48|4@1+ (1,0) [0|0] ""  Host
 SG_ PinPullModeStatus_23 : 52|2@1+ (1,0) [0|0] ""  Host
 SG_ LoadDetectionStatus_23 : 54|2@1+ (1,0) [0|0] ""  Host
 SG_ PinModeStatus_24 : 56|4@1+ (1,0) [0|0] ""  Host
 SG_ PinPullModeStatus_24 : 60|2@1+ (1,0) [0|0] ""  Host
 SG_ LoadDetectionStatus_24 : 62|2@1+ (1,0) [0|0] ""  Host

BO_ 2583647486 IoStatusPinMode4: 8 Device
 SG_ PinModeStatus_25 : 0|4@1+ (1,0) [0|0] ""  Host
 SG_ PinPullModeStatus_25 : 4|2@1+ (1,0) [0|0] ""  Host
 SG_ LoadDetectionStatus_25 : 6|2@1+ (1,0) [0|0] ""  Host
 SG_ PinModeStatus_26 : 8|4@1+ (1,0) [0|0] ""  Host
 SG_ PinPullModeStatus_26 : 12|2@1+ (1,0) [0|0] ""  Host
 SG_ LoadDetectionStatus_26 : 14|2@1+ (1,0) [0|0] ""  Host
 SG_ PinModeStatus_27 : 16|4@1+ (1,0) [0|0] ""  Host
 SG_ PinPullModeStatus_27 : 20|2@1+ (1,0) [0|0] ""  Host
 SG_ LoadDetectionStatus_27 : 22|2@1+ (1,0) [0|0] ""  Host
 SG_ PinModeStatus_28 : 24|4@1+ (1,0) [0|0] ""  Host
 SG_ PinPullModeStatus_28 : 28|2@1+ (1,0) [0|0] ""  Host
 SG_ LoadDetectionStatus_28 : 30|2@1+ (1,0) [0|0] ""  Host
 SG_ PinModeStatus_29 : 32|4@1+ (1,0) [0|0] ""  Host
 SG_ PinPullModeStatus_29 : 36|2@1+ (1,0) [0|0] ""  Host
 SG_ LoadDetectionStatus_29 : 38|2@1+ (1,0) [0|0] ""  Host
 SG_ PinModeStatus_30 : 40|4@1+ (1,0) [0|0] ""  Host
 SG_ PinPullModeStatus_30 : 44|2@1+ (1,0) [0|0] ""  Host
 SG_ LoadDetectionStatus_30 : 46|2@1+ (1,0) [0|0] ""  Host
 SG_ PinModeStatus_31 : 48|4@1+ (1,0) [0|0] ""  Host
 SG_ PinPullModeStatus_31 : 52|2@1+ (1,0) [0|0] ""  Host
 SG_ LoadDetectionStatus_31 : 54|2@1+ (1,0) [0|0] ""  Host
 SG_ PinModeStatus_32 : 56|4@1+ (1,0) [0|0] ""  Host
 SG_ PinPullModeStatus_32 : 60|2@1+ (1,0) [0|0] ""  Host
 SG_ LoadDetectionStatus_32 : 62|2@1+ (1,0) [0|0] ""  Host

BO_ 2582846974 IoStatusPinModeFD: 32 Device
 SG_ PinModeStatus_01 : 0|4@1+ (1,0) [0|0] ""  Host
 SG_ PinPullModeStatus_01 : 4|2@1+ (1,0) [0|0] ""  Host
 SG_ LoadDetectionStatus_01 : 6|2@1+ (1,0) [0|0] ""  Host
 SG_ PinModeStatus_02 : 8|4@1+ (1,0) [0|0] ""  Host
 SG_ PinPullModeStatus_02 : 12|2@1+ (1,0) [0|0] ""  Host
 SG_ LoadDetectionStatus_02 : 14|2@1+ (1,0) [0|0] ""  Host
 SG_ PinModeStatus_03 : 16|4@1+ (1,0) [0|0] ""  Host
 SG_ PinPullModeStatus_03 : 20|2@1+ (1,0) [0|0] ""  Host
 SG_ LoadDetectionStatus_03 : 22|2@1+ (1,0) [0|0] ""  Host
 SG_ PinModeStatus_04 : 24|4@1+ (1,0) [0|0] ""  Host
 SG_ PinPullModeStatus_04 : 28|2@1+ (1,0) [0|0] ""  Host
 SG_ LoadDetectionStatus_04 : 30|2@1+ (1,0) [0|0] ""  Host
 SG_ PinModeStatus_05 : 32|4@1+ (1,0) [0|0] ""  Host
 SG_ PinPullModeStatus_05 : 36|2@1+ (1,0) [0|0] ""  Host
 SG_ LoadDetectionStatus_05 : 38|2@1+ (1,0) [0|0] ""  Host
 SG_ PinModeStatus_06 : 40|4@1+ (1,0) [0|0] ""  Host
 SG_ PinPullModeStatus_06 : 44|2@1+ (1,0) [0|0] ""  Host
 SG_ LoadDetectionStatus_06 : 46|2@1+ (1,0) [0|0] ""  Host
 SG_ PinModeStatus_07 : 48|4@1+ (1,0) [0|0] ""  Host
 SG_ PinPullModeStatus_07 : 52|2@1+ (1,0) [0|0] ""  Host
 SG_ LoadDetectionStatus_07 : 54|2@1+ (1,0) [0|0] ""  Host
 SG_ PinModeStatus_08 : 56|4@1+ (1,0) [0|0] ""  Host
 SG_ PinPullModeStatus_08 : 60|2@1+ (1,0) [0|0] ""  Host
 SG_ LoadDetectionStatus_08 : 62|2@1+ (1,0) [0|0] ""  Host
 SG_ PinModeStatus_09 : 64|4@1+ (1,0) [0|0] ""  Host
 SG_ PinPullModeStatus_09 : 68|2@1+ (1,0) [0|0] ""  Host
 SG_ LoadDetectionStatus_09 : 70|2@1+ (1,0) [0|0] ""  Host
 SG_ PinModeStatus_10 : 72|4@1+ (1,0) [0|0] ""  Host
 SG_ PinPullModeStatus_10 : 76|2@1+ (1,0) [0|0] ""  Host
 SG_ LoadDetectionStatus_10 : 78|2@1+ (1,0) [0|0] ""  Host
 SG_ PinModeStatus_11 : 80|4@1+ (1,0) [0|0] ""  Host
 SG_ PinPullModeStatus_11 : 84|2@1+ (1,0) [0|0] ""  Host
 SG_ LoadDetectionStatus_11 : 86|2@1+ (1,0) [0|0] ""  Host
 SG_ PinModeStatus_12 : 88|4@1+ (1,0) [0|0] ""  Host
 SG_ PinPullModeStatus_12 : 92|2@1+ (1,0) [0|0] ""  Host
 SG_ LoadDetectionStatus_12 : 94|2@1+ (1,0) [0|0] ""  Host
 SG_ PinModeStatus_13 : 96|4@1+ (1,0) [0|0] ""  Host
 SG_ PinPullModeStatus_13 : 100|2@1+ (1,0) [0|0] ""  Host
 SG_ LoadDetectionStatus_13 : 102|2@1+ (1,0) [0|0] ""  Host
 SG_ PinModeStatus_14 : 104|4@1+ (1,0) [0|0] ""  Host
 SG_ PinPullModeStatus_14 : 108|2@1+ (1,0) [0|0] ""  Host
 SG_ LoadDetectionStatus_14 : 110|2@1+ (1,0) [0|0] ""  Host
 SG_ PinModeStatus_15 : 112|4@1+ (1,0) [0|0] ""  Host
 SG_ PinPullModeStatus_15 : 116|2@1+ (1,0) [0|0] ""  Host
 SG_ LoadDetectionStatus_15 : 118|2@1+ (1,0) [0|0] ""  Host
 SG_ PinModeStatus_16 : 120|4@1+ (1,0) [0|0] ""  Host
 SG_ PinPullModeStatus_16 : 124|2@1+ (1,0) [0|0] ""  Host
 SG_ LoadDetectionStatus_16 : 126|2@1+ (1,0) [0|0] ""  Host
 SG_ PinModeStatus_17 : 128|4@1+ (1,0) [0|0] ""  Host
 SG_ PinPullModeStatus_17 : 132|2@1+ (1,0) [0|0] ""  Host
 SG_ LoadDetectionStatus_17 : 134|2@1+ (1,0) [0|0] ""  Host
 SG_ PinModeStatus_18 : 136|4@1+ (1,0) [0|0] ""  Host
 SG_ PinPullModeStatus_18 : 140|2@1+ (1,0) [0|0] ""  Host
 SG_ LoadDetectionStatus_18 : 142|2@1+ (1,0) [0|0] ""  Host
 SG_ PinModeStatus_19 : 144|4@1+ (1,0) [0|0] ""  Host
 SG_ PinPullModeStatus_19 : 148|2@1+ (1,0) [0|0] ""  Host
 SG_ LoadDetectionStatus_19 : 150|2@1+ (1,0) [0|0] ""  Host
 SG_ PinModeStatus_20 : 152|4@1+ (1,0) [0|0] ""  Host
 SG_ PinPullModeStatus_20 : 156|2@1+ (1,0) [0|0] ""  Host
 SG_ LoadDetectionStatus_20 : 158|2@1+ (1,0) [0|0] ""  Host
 SG_ PinModeStatus_21 : 160|4@1+ (1,0) [0|0] ""  Host
 SG_ PinPullModeStatus_21 : 164|2@1+ (1,0) [0|0] ""  Host
 SG_ LoadDetectionStatus_21 : 166|2@1+ (1,0) [0|0] ""  Host
 SG_ PinModeStatus_22 : 168|4@1+ (1,0) [0|0] ""  Host
 SG_ PinPullModeStatus_22 : 172|2@1+ (1,0) [0|0] ""  Host
 SG_ LoadDetectionStatus_22 : 174|2@1+ (1,0) [0|0] ""  Host
 SG_ PinModeStatus_23 : 176|4@1+ (1,0) [0|0] ""  Host
 SG_ PinPullModeStatus_23 : 180|2@1+ (1,0) [0|0] ""  Host
 SG_ LoadDetectionStatus_23 : 182|2@1+ (1,0) [0|0] ""  Host
 SG_ PinModeStatus_24 : 184|4@1+ (1,0) [0|0] ""  Host
 SG_ PinPullModeStatus_24 : 188|2@1+ (1,0) [0|0] ""  Host
 SG_ LoadDetectionStatus_24 : 190|2@1+ (1,0) [0|0] ""  Host
 SG_ PinModeStatus_25 : 192|4@1+ (1,0) [0|0] ""  Host
 SG_ PinPullModeStatus_25 : 196|2@1+ (1,0) [0|0] ""  Host
 SG_ LoadDetectionStatus_25 : 198|2@1+ (1,0) [0|0] ""  Host
 SG_ PinModeStatus_26 : 200|4@1+ (1,0) [0|0] ""  Host
 SG_ PinPullModeStatus_26 : 204|2@1+ (1,0) [0|0] ""  Host
 SG_ LoadDetectionStatus_26 : 206|2@1+ (1,0) [0|0] ""  Host
 SG_ PinModeStatus_27 : 208|4@1+ (1,0) [0|0] ""  Host
 SG_ PinPullModeStatus_27 : 212|2@1+ (1,0) [0|0] ""  Host
 SG_ LoadDetectionStatus_27 : 214|2@1+ (1,0) [0|0] ""  Host
 SG_ PinModeStatus_28 : 216|4@1+ (1,0) [0|0] ""  Host
 SG_ PinPullModeStatus_28 : 220|2@1+ (1,0) [0|0] ""  Host
 SG_ LoadDetectionStatus_28 : 222|2@1+ (1,0) [0|0] ""  Host
 SG_ PinModeStatus_29 : 224|4@1+ (1,0) [0|0] ""  Host
 SG_ PinPullModeStatus_29 : 228|2@1+ (1,0) [0|0] ""  Host
 SG_ LoadDetectionStatus_29 : 230|2@1+ (1,0) [0|0] ""  Host
 SG_ PinModeStatus_30 : 232|4@1+ (1,0) [0|0] ""  Host
 SG_ PinPullModeStatus_30 : 236|2@1+ (1,0) [0|0] ""  Host
 SG_ LoadDetectionStatus_30 : 238|2@1+ (1,0) [0|0] ""  Host
 SG_ PinModeStatus_31 : 240|4@1+ (1,0) [0|0] ""  Host
 SG_ PinPullModeStatus_31 : 244|2@1+ (1,0) [0|0] ""  Host
 SG_ LoadDetectionStatus_31 : 246|2@1+ (1,0) [0|0] ""  Host
 SG_ PinModeStatus_32 : 248|4@1+ (1,0) [0|0] ""  Host
 SG_ PinPullModeStatus_32 : 252|2@1+ (1,0) [0|0] ""  Host
 SG_ LoadDetectionStatus_32 : 254|2@1+ (1,0) [0|0] ""  Host

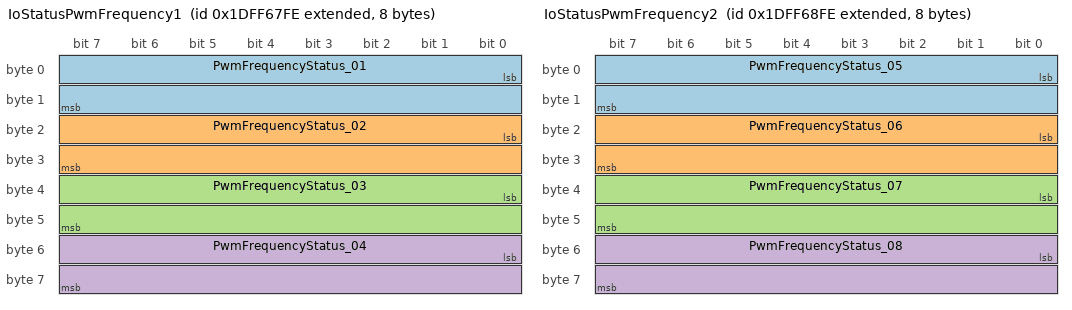
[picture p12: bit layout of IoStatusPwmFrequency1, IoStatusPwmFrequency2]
BO_ 2650761214 IoStatusPwmFrequency1: 8 Device
 SG_ PwmFrequencyStatus_01 : 0|16@1+ (0.1,0) [0|6425.5] "Hz"  Host
 SG_ PwmFrequencyStatus_02 : 16|16@1+ (0.1,0) [0|6425.5] "Hz"  Host
 SG_ PwmFrequencyStatus_03 : 32|16@1+ (0.1,0) [0|6425.5] "Hz"  Host
 SG_ PwmFrequencyStatus_04 : 48|16@1+ (0.1,0) [0|6425.5] "Hz"  Host

BO_ 2650761470 IoStatusPwmFrequency2: 8 Device
 SG_ PwmFrequencyStatus_05 : 0|16@1+ (0.1,0) [0|6425.5] "Hz"  Host
 SG_ PwmFrequencyStatus_06 : 16|16@1+ (0.1,0) [0|6425.5] "Hz"  Host
 SG_ PwmFrequencyStatus_07 : 32|16@1+ (0.1,0) [0|6425.5] "Hz"  Host
 SG_ PwmFrequencyStatus_08 : 48|16@1+ (0.1,0) [0|6425.5] "Hz"  Host

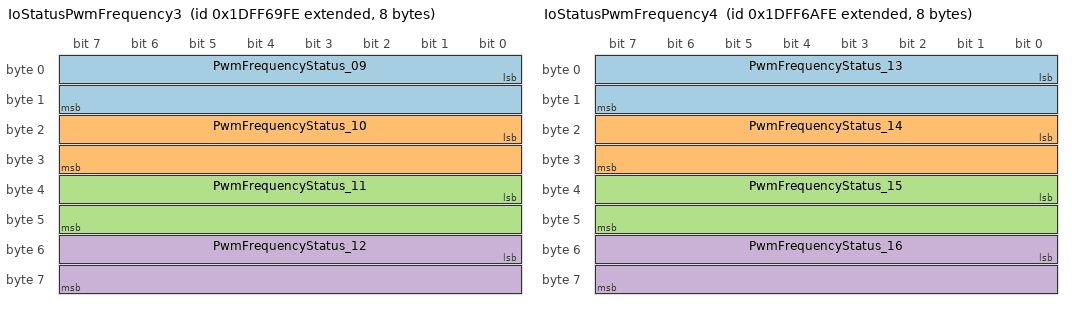
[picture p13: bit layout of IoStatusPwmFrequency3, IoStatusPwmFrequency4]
BO_ 2650761726 IoStatusPwmFrequency3: 8 Device
 SG_ PwmFrequencyStatus_09 : 0|16@1+ (0.1,0) [0|6425.5] "Hz"  Host
 SG_ PwmFrequencyStatus_10 : 16|16@1+ (0.1,0) [0|6425.5] "Hz"  Host
 SG_ PwmFrequencyStatus_11 : 32|16@1+ (0.1,0) [0|6425.5] "Hz"  Host
 SG_ PwmFrequencyStatus_12 : 48|16@1+ (0.1,0) [0|6425.5] "Hz"  Host

BO_ 2650761982 IoStatusPwmFrequency4: 8 Device
 SG_ PwmFrequencyStatus_13 : 0|16@1+ (0.1,0) [0|6425.5] "Hz"  Host
 SG_ PwmFrequencyStatus_14 : 16|16@1+ (0.1,0) [0|6425.5] "Hz"  Host
 SG_ PwmFrequencyStatus_15 : 32|16@1+ (0.1,0) [0|6425.5] "Hz"  Host
 SG_ PwmFrequencyStatus_16 : 48|16@1+ (0.1,0) [0|6425.5] "Hz"  Host

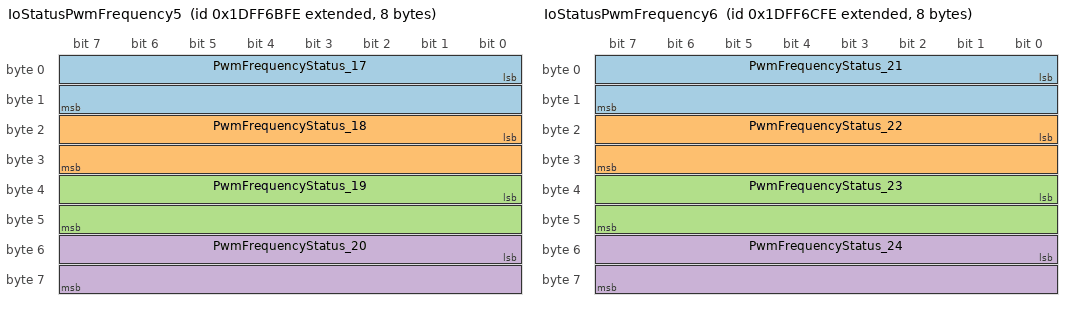
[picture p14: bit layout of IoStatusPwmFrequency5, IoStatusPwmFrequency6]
BO_ 2650762238 IoStatusPwmFrequency5: 8 Device
 SG_ PwmFrequencyStatus_17 : 0|16@1+ (0.1,0) [0|6425.5] "Hz"  Host
 SG_ PwmFrequencyStatus_18 : 16|16@1+ (0.1,0) [0|6425.5] "Hz"  Host
 SG_ PwmFrequencyStatus_19 : 32|16@1+ (0.1,0) [0|6425.5] "Hz"  Host
 SG_ PwmFrequencyStatus_20 : 48|16@1+ (0.1,0) [0|6425.5] "Hz"  Host

BO_ 2650762494 IoStatusPwmFrequency6: 8 Device
 SG_ PwmFrequencyStatus_21 : 0|16@1+ (0.1,0) [0|6425.5] "Hz"  Host
 SG_ PwmFrequencyStatus_22 : 16|16@1+ (0.1,0) [0|6425.5] "Hz"  Host
 SG_ PwmFrequencyStatus_23 : 32|16@1+ (0.1,0) [0|6425.5] "Hz"  Host
 SG_ PwmFrequencyStatus_24 : 48|16@1+ (0.1,0) [0|6425.5] "Hz"  Host

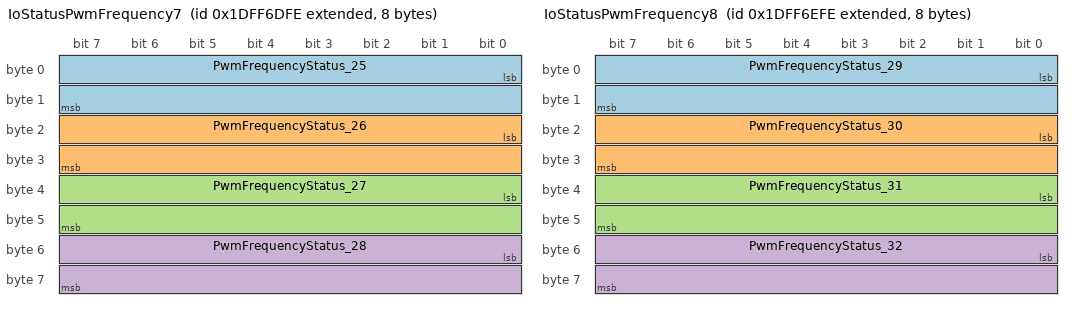
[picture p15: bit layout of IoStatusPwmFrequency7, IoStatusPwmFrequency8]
BO_ 2650762750 IoStatusPwmFrequency7: 8 Device
 SG_ PwmFrequencyStatus_25 : 0|16@1+ (0.1,0) [0|6425.5] "Hz"  Host
 SG_ PwmFrequencyStatus_26 : 16|16@1+ (0.1,0) [0|6425.5] "Hz"  Host
 SG_ PwmFrequencyStatus_27 : 32|16@1+ (0.1,0) [0|6425.5] "Hz"  Host
 SG_ PwmFrequencyStatus_28 : 48|16@1+ (0.1,0) [0|6425.5] "Hz"  Host

BO_ 2650763006 IoStatusPwmFrequency8: 8 Device
 SG_ PwmFrequencyStatus_29 : 0|16@1+ (0.1,0) [0|6425.5] "Hz"  Host
 SG_ PwmFrequencyStatus_30 : 16|16@1+ (0.1,0) [0|6425.5] "Hz"  Host
 SG_ PwmFrequencyStatus_31 : 32|16@1+ (0.1,0) [0|6425.5] "Hz"  Host
 SG_ PwmFrequencyStatus_32 : 48|16@1+ (0.1,0) [0|6425.5] "Hz"  Host

BO_ 2649956094 IoStatusPwmFrequencyFD: 64 Device
 SG_ PwmFrequencyStatus_01 : 0|16@1+ (0.1,0) [0|6425.5] "Hz"  Host
 SG_ PwmFrequencyStatus_02 : 16|16@1+ (0.1,0) [0|6425.5] "Hz"  Host
 SG_ PwmFrequencyStatus_03 : 32|16@1+ (0.1,0) [0|6425.5] "Hz"  Host
 SG_ PwmFrequencyStatus_04 : 48|16@1+ (0.1,0) [0|6425.5] "Hz"  Host
 SG_ PwmFrequencyStatus_05 : 64|16@1+ (0.1,0) [0|6425.5] "Hz"  Host
 SG_ PwmFrequencyStatus_06 : 80|16@1+ (0.1,0) [0|6425.5] "Hz"  Host
 SG_ PwmFrequencyStatus_07 : 96|16@1+ (0.1,0) [0|6425.5] "Hz"  Host
 SG_ PwmFrequencyStatus_08 : 112|16@1+ (0.1,0) [0|6425.5] "Hz"  Host
 SG_ PwmFrequencyStatus_09 : 128|16@1+ (0.1,0) [0|6425.5] "Hz"  Host
 SG_ PwmFrequencyStatus_10 : 144|16@1+ (0.1,0) [0|6425.5] "Hz"  Host
 SG_ PwmFrequencyStatus_11 : 160|16@1+ (0.1,0) [0|6425.5] "Hz"  Host
 SG_ PwmFrequencyStatus_12 : 176|16@1+ (0.1,0) [0|6425.5] "Hz"  Host
 SG_ PwmFrequencyStatus_13 : 192|16@1+ (0.1,0) [0|6425.5] "Hz"  Host
 SG_ PwmFrequencyStatus_14 : 208|16@1+ (0.1,0) [0|6425.5] "Hz"  Host
 SG_ PwmFrequencyStatus_15 : 224|16@1+ (0.1,0) [0|6425.5] "Hz"  Host
 SG_ PwmFrequencyStatus_16 : 240|16@1+ (0.1,0) [0|6425.5] "Hz"  Host
 SG_ PwmFrequencyStatus_17 : 256|16@1+ (0.1,0) [0|6425.5] "Hz"  Host
 SG_ PwmFrequencyStatus_18 : 272|16@1+ (0.1,0) [0|6425.5] "Hz"  Host
 SG_ PwmFrequencyStatus_19 : 288|16@1+ (0.1,0) [0|6425.5] "Hz"  Host
 SG_ PwmFrequencyStatus_20 : 304|16@1+ (0.1,0) [0|6425.5] "Hz"  Host
 SG_ PwmFrequencyStatus_21 : 320|16@1+ (0.1,0) [0|6425.5] "Hz"  Host
 SG_ PwmFrequencyStatus_22 : 336|16@1+ (0.1,0) [0|6425.5] "Hz"  Host
 SG_ PwmFrequencyStatus_23 : 352|16@1+ (0.1,0) [0|6425.5] "Hz"  Host
 SG_ PwmFrequencyStatus_24 : 368|16@1+ (0.1,0) [0|6425.5] "Hz"  Host
 SG_ PwmFrequencyStatus_25 : 384|16@1+ (0.1,0) [0|6425.5] "Hz"  Host
 SG_ PwmFrequencyStatus_26 : 400|16@1+ (0.1,0) [0|6425.5] "Hz"  Host
 SG_ PwmFrequencyStatus_27 : 416|16@1+ (0.1,0) [0|6425.5] "Hz"  Host
 SG_ PwmFrequencyStatus_28 : 432|16@1+ (0.1,0) [0|6425.5] "Hz"  Host
 SG_ PwmFrequencyStatus_29 : 448|16@1+ (0.1,0) [0|6425.5] "Hz"  Host
 SG_ PwmFrequencyStatus_30 : 464|16@1+ (0.1,0) [0|6425.5] "Hz"  Host
 SG_ PwmFrequencyStatus_31 : 480|16@1+ (0.1,0) [0|6425.5] "Hz"  Host
 SG_ PwmFrequencyStatus_32 : 496|16@1+ (0.1,0) [0|6425.5] "Hz"  Host

BO_ 2582847998 IoStatusQEncoder1: 8 Device
 SG_ QEncoderDirection_Q01 : 0|2@1+ (1,0) [0|0] ""  Host
 SG_ QEncoderCounter_Q01 : 8|24@1+ (1,-8000000) [-8000000|8000000] ""  Host

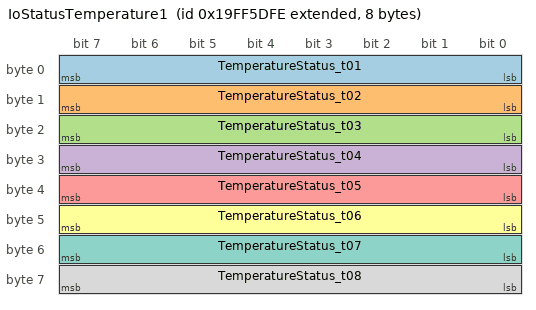
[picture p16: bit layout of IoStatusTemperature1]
BO_ 2583649790 IoStatusTemperature1: 8 Device
 SG_ TemperatureStatus_t01 : 0|8@1+ (1,-40) [-40|210] "C"  Host
 SG_ TemperatureStatus_t02 : 8|8@1+ (1,-40) [-40|210] "C"  Host
 SG_ TemperatureStatus_t03 : 16|8@1+ (1,-40) [-40|210] "C"  Host
 SG_ TemperatureStatus_t04 : 24|8@1+ (1,-40) [-40|210] "C"  Host
 SG_ TemperatureStatus_t05 : 32|8@1+ (1,-40) [-40|210] "C"  Host
 SG_ TemperatureStatus_t06 : 40|8@1+ (1,-40) [-40|210] "C"  Host
 SG_ TemperatureStatus_t07 : 48|8@1+ (1,-40) [-40|210] "C"  Host
 SG_ TemperatureStatus_t08 : 56|8@1+ (1,-40) [-40|210] "C"  Host

CM_ BO_ 2582846206 "Faults count";
CM_ SG_ 2582846206 FaultCountStatus_01 "Detected faults count";
CM_ SG_ 2582846206 FaultCountStatus_02 "Detected faults count";
CM_ SG_ 2582846206 FaultCountStatus_03 "Detected faults count";
CM_ SG_ 2582846206 FaultCountStatus_04 "Detected faults count";
CM_ SG_ 2582846206 FaultCountStatus_05 "Detected faults count";
CM_ SG_ 2582846206 FaultCountStatus_06 "Detected faults count";
CM_ SG_ 2582846206 FaultCountStatus_07 "Detected faults count";
CM_ SG_ 2582846206 FaultCountStatus_08 "Detected faults count";
CM_ SG_ 2582846206 FaultCountStatus_09 "Detected faults count";
CM_ SG_ 2582846206 FaultCountStatus_10 "Detected faults count";
CM_ SG_ 2582846206 FaultCountStatus_11 "Detected faults count";
CM_ SG_ 2582846206 FaultCountStatus_12 "Detected faults count";
CM_ SG_ 2582846206 FaultCountStatus_13 "Detected faults count";
CM_ SG_ 2582846206 FaultCountStatus_14 "Detected faults count";
CM_ SG_ 2582846206 FaultCountStatus_15 "Detected faults count";
CM_ SG_ 2582846206 FaultCountStatus_16 "Detected faults count";
CM_ SG_ 2582846206 FaultCountStatus_17 "Detected faults count";
CM_ SG_ 2582846206 FaultCountStatus_18 "Detected faults count";
CM_ SG_ 2582846206 FaultCountStatus_19 "Detected faults count";
CM_ SG_ 2582846206 FaultCountStatus_20 "Detected faults count";
CM_ SG_ 2582846206 FaultCountStatus_21 "Detected faults count";
CM_ SG_ 2582846206 FaultCountStatus_22 "Detected faults count";
CM_ SG_ 2582846206 FaultCountStatus_23 "Detected faults count";
CM_ SG_ 2582846206 FaultCountStatus_24 "Detected faults count";
CM_ SG_ 2582846206 FaultCountStatus_25 "Detected faults count";
CM_ SG_ 2582846206 FaultCountStatus_26 "Detected faults count";
CM_ SG_ 2582846206 FaultCountStatus_27 "Detected faults count";
CM_ SG_ 2582846206 FaultCountStatus_28 "Detected faults count";
CM_ SG_ 2582846206 FaultCountStatus_29 "Detected faults count";
CM_ SG_ 2582846206 FaultCountStatus_30 "Detected faults count";
CM_ SG_ 2582846206 FaultCountStatus_31 "Detected faults count";
CM_ SG_ 2582846206 FaultCountStatus_32 "Detected faults count";
CM_ BO_ 2582839550 "Measured output current when fault occured";
CM_ SG_ 2582839550 FaultCurrentStatus_01 "Measured current when fault detected";
CM_ SG_ 2582839550 FaultCurrentStatus_02 "Measured current when fault detected";
CM_ SG_ 2582839550 FaultCurrentStatus_03 "Measured current when fault detected";
CM_ SG_ 2582839550 FaultCurrentStatus_04 "Measured current when fault detected";
CM_ BO_ 2582839806 "Measured output current when fault occured";
CM_ SG_ 2582839806 FaultCurrentStatus_05 "Measured current when fault detected";
CM_ SG_ 2582839806 FaultCurrentStatus_06 "Measured current when fault detected";
CM_ SG_ 2582839806 FaultCurrentStatus_07 "Measured current when fault detected";
CM_ SG_ 2582839806 FaultCurrentStatus_08 "Measured current when fault detected";
CM_ BO_ 2582840062 "Measured output current when fault occured";
CM_ SG_ 2582840062 FaultCurrentStatus_09 "Measured current when fault detected";
CM_ SG_ 2582840062 FaultCurrentStatus_10 "Measured current when fault detected";
CM_ SG_ 2582840062 FaultCurrentStatus_11 "Measured current when fault detected";
CM_ SG_ 2582840062 FaultCurrentStatus_12 "Measured current when fault detected";
CM_ BO_ 2582840318 "Measured output current when fault occured";
CM_ SG_ 2582840318 FaultCurrentStatus_13 "Measured current when fault detected";
CM_ SG_ 2582840318 FaultCurrentStatus_14 "Measured current when fault detected";
CM_ SG_ 2582840318 FaultCurrentStatus_15 "Measured current when fault detected";
CM_ SG_ 2582840318 FaultCurrentStatus_16 "Measured current when fault detected";
CM_ BO_ 2582840574 "Measured output current when fault occured";
CM_ SG_ 2582840574 FaultCurrentStatus_17 "Measured current when fault detected";
CM_ SG_ 2582840574 FaultCurrentStatus_18 "Measured current when fault detected";
CM_ SG_ 2582840574 FaultCurrentStatus_19 "Measured current when fault detected";
CM_ SG_ 2582840574 FaultCurrentStatus_20 "Measured current when fault detected";
CM_ BO_ 2582840830 "Measured output current when fault occured";
CM_ SG_ 2582840830 FaultCurrentStatus_21 "Measured current when fault detected";
CM_ SG_ 2582840830 FaultCurrentStatus_22 "Measured current when fault detected";
CM_ SG_ 2582840830 FaultCurrentStatus_23 "Measured current when fault detected";
CM_ SG_ 2582840830 FaultCurrentStatus_24 "Measured current when fault detected";
CM_ BO_ 2582841086 "Measured output current when fault occured";
CM_ SG_ 2582841086 FaultCurrentStatus_25 "Measured current when fault detected";
CM_ SG_ 2582841086 FaultCurrentStatus_26 "Measured current when fault detected";
CM_ SG_ 2582841086 FaultCurrentStatus_27 "Measured current when fault detected";
CM_ SG_ 2582841086 FaultCurrentStatus_28 "Measured current when fault detected";
CM_ BO_ 2582841342 "Measured output current when fault occured";
CM_ SG_ 2582841342 FaultCurrentStatus_29 "Measured current when fault detected";
CM_ SG_ 2582841342 FaultCurrentStatus_30 "Measured current when fault detected";
CM_ SG_ 2582841342 FaultCurrentStatus_31 "Measured current when fault detected";
CM_ SG_ 2582841342 FaultCurrentStatus_32 "Measured current when fault detected";
CM_ BO_ 2582846462 "Measured output current when fault occured";
CM_ SG_ 2582846462 FaultCurrentStatus_01 "Measured current when fault detected";
CM_ SG_ 2582846462 FaultCurrentStatus_02 "Measured current when fault detected";
CM_ SG_ 2582846462 FaultCurrentStatus_03 "Measured current when fault detected";
CM_ SG_ 2582846462 FaultCurrentStatus_04 "Measured current when fault detected";
CM_ SG_ 2582846462 FaultCurrentStatus_05 "Measured current when fault detected";
CM_ SG_ 2582846462 FaultCurrentStatus_06 "Measured current when fault detected";
CM_ SG_ 2582846462 FaultCurrentStatus_07 "Measured current when fault detected";
CM_ SG_ 2582846462 FaultCurrentStatus_08 "Measured current when fault detected";
CM_ SG_ 2582846462 FaultCurrentStatus_09 "Measured current when fault detected";
CM_ SG_ 2582846462 FaultCurrentStatus_10 "Measured current when fault detected";
CM_ SG_ 2582846462 FaultCurrentStatus_11 "Measured current when fault detected";
CM_ SG_ 2582846462 FaultCurrentStatus_12 "Measured current when fault detected";
CM_ SG_ 2582846462 FaultCurrentStatus_13 "Measured current when fault detected";
CM_ SG_ 2582846462 FaultCurrentStatus_14 "Measured current when fault detected";
CM_ SG_ 2582846462 FaultCurrentStatus_15 "Measured current when fault detected";
CM_ SG_ 2582846462 FaultCurrentStatus_16 "Measured current when fault detected";
CM_ SG_ 2582846462 FaultCurrentStatus_17 "Measured current when fault detected";
CM_ SG_ 2582846462 FaultCurrentStatus_18 "Measured current when fault detected";
CM_ SG_ 2582846462 FaultCurrentStatus_19 "Measured current when fault detected";
CM_ SG_ 2582846462 FaultCurrentStatus_20 "Measured current when fault detected";
CM_ SG_ 2582846462 FaultCurrentStatus_21 "Measured current when fault detected";
CM_ SG_ 2582846462 FaultCurrentStatus_22 "Measured current when fault detected";
CM_ SG_ 2582846462 FaultCurrentStatus_23 "Measured current when fault detected";
CM_ SG_ 2582846462 FaultCurrentStatus_24 "Measured current when fault detected";
CM_ SG_ 2582846462 FaultCurrentStatus_25 "Measured current when fault detected";
CM_ SG_ 2582846462 FaultCurrentStatus_26 "Measured current when fault detected";
CM_ SG_ 2582846462 FaultCurrentStatus_27 "Measured current when fault detected";
CM_ SG_ 2582846462 FaultCurrentStatus_28 "Measured current when fault detected";
CM_ SG_ 2582846462 FaultCurrentStatus_29 "Measured current when fault detected";
CM_ SG_ 2582846462 FaultCurrentStatus_30 "Measured current when fault detected";
CM_ SG_ 2582846462 FaultCurrentStatus_31 "Measured current when fault detected";
CM_ SG_ 2582846462 FaultCurrentStatus_32 "Measured current when fault detected";
CM_ BO_ 2582841598 "Measured input voltage when fault occured";
CM_ SG_ 2582841598 FaultVoltageStatus_01 "Measured voltage when fault occured";
CM_ SG_ 2582841598 FaultVoltageStatus_02 "Measured voltage when fault occured";
CM_ SG_ 2582841598 FaultVoltageStatus_03 "Measured voltage when fault occured";
CM_ SG_ 2582841598 FaultVoltageStatus_04 "Measured voltage when fault occured";
CM_ BO_ 2582841854 "Measured input voltage when fault occured";
CM_ SG_ 2582841854 FaultVoltageStatus_05 "Measured voltage when fault occured";
CM_ SG_ 2582841854 FaultVoltageStatus_06 "Measured voltage when fault occured";
CM_ SG_ 2582841854 FaultVoltageStatus_07 "Measured voltage when fault occured";
CM_ SG_ 2582841854 FaultVoltageStatus_08 "Measured voltage when fault occured";
CM_ BO_ 2582842110 "Measured input voltage when fault occured";
CM_ SG_ 2582842110 FaultVoltageStatus_09 "Measured voltage when fault occured";
CM_ SG_ 2582842110 FaultVoltageStatus_10 "Measured voltage when fault occured";
CM_ SG_ 2582842110 FaultVoltageStatus_11 "Measured voltage when fault occured";
CM_ SG_ 2582842110 FaultVoltageStatus_12 "Measured voltage when fault occured";
CM_ BO_ 2582842366 "Measured input voltage when fault occured";
CM_ SG_ 2582842366 FaultVoltageStatus_13 "Measured voltage when fault occured";
CM_ SG_ 2582842366 FaultVoltageStatus_14 "Measured voltage when fault occured";
CM_ SG_ 2582842366 FaultVoltageStatus_15 "Measured voltage when fault occured";
CM_ SG_ 2582842366 FaultVoltageStatus_16 "Measured voltage when fault occured";
CM_ BO_ 2582842622 "Measured input voltage when fault occured";
CM_ SG_ 2582842622 FaultVoltageStatus_17 "Measured voltage when fault occured";
CM_ SG_ 2582842622 FaultVoltageStatus_18 "Measured voltage when fault occured";
CM_ SG_ 2582842622 FaultVoltageStatus_19 "Measured voltage when fault occured";
CM_ SG_ 2582842622 FaultVoltageStatus_20 "Measured voltage when fault occured";
CM_ BO_ 2582842878 "Measured input voltage when fault occured";
CM_ SG_ 2582842878 FaultVoltageStatus_21 "Measured voltage when fault occured";
CM_ SG_ 2582842878 FaultVoltageStatus_22 "Measured voltage when fault occured";
CM_ SG_ 2582842878 FaultVoltageStatus_23 "Measured voltage when fault occured";
CM_ SG_ 2582842878 FaultVoltageStatus_24 "Measured voltage when fault occured";
CM_ BO_ 2582843134 "Measured input voltage when fault occured";
CM_ SG_ 2582843134 FaultVoltageStatus_25 "Measured voltage when fault occured";
CM_ SG_ 2582843134 FaultVoltageStatus_26 "Measured voltage when fault occured";
CM_ SG_ 2582843134 FaultVoltageStatus_27 "Measured voltage when fault occured";
CM_ SG_ 2582843134 FaultVoltageStatus_28 "Measured voltage when fault occured";
CM_ BO_ 2582843390 "Measured input voltage when fault occured";
CM_ SG_ 2582843390 FaultVoltageStatus_29 "Measured voltage when fault occured";
CM_ SG_ 2582843390 FaultVoltageStatus_30 "Measured voltage when fault occured";
CM_ SG_ 2582843390 FaultVoltageStatus_31 "Measured voltage when fault occured";
CM_ SG_ 2582843390 FaultVoltageStatus_32 "Measured voltage when fault occured";
CM_ BO_ 2582846718 "Measured input voltage when fault occured";
CM_ SG_ 2582846718 FaultVoltageStatus_01 "Measured voltage when fault occured";
CM_ SG_ 2582846718 FaultVoltageStatus_02 "Measured voltage when fault occured";
CM_ SG_ 2582846718 FaultVoltageStatus_03 "Measured voltage when fault occured";
CM_ SG_ 2582846718 FaultVoltageStatus_04 "Measured voltage when fault occured";
CM_ SG_ 2582846718 FaultVoltageStatus_05 "Measured voltage when fault occured";
CM_ SG_ 2582846718 FaultVoltageStatus_06 "Measured voltage when fault occured";
CM_ SG_ 2582846718 FaultVoltageStatus_07 "Measured voltage when fault occured";
CM_ SG_ 2582846718 FaultVoltageStatus_08 "Measured voltage when fault occured";
CM_ SG_ 2582846718 FaultVoltageStatus_09 "Measured voltage when fault occured";
CM_ SG_ 2582846718 FaultVoltageStatus_10 "Measured voltage when fault occured";
CM_ SG_ 2582846718 FaultVoltageStatus_11 "Measured voltage when fault occured";
CM_ SG_ 2582846718 FaultVoltageStatus_12 "Measured voltage when fault occured";
CM_ SG_ 2582846718 FaultVoltageStatus_13 "Measured voltage when fault occured";
CM_ SG_ 2582846718 FaultVoltageStatus_14 "Measured voltage when fault occured";
CM_ SG_ 2582846718 FaultVoltageStatus_15 "Measured voltage when fault occured";
CM_ SG_ 2582846718 FaultVoltageStatus_16 "Measured voltage when fault occured";
CM_ SG_ 2582846718 FaultVoltageStatus_17 "Measured voltage when fault occured";
CM_ SG_ 2582846718 FaultVoltageStatus_18 "Measured voltage when fault occured";
CM_ SG_ 2582846718 FaultVoltageStatus_19 "Measured voltage when fault occured";
CM_ SG_ 2582846718 FaultVoltageStatus_20 "Measured voltage when fault occured";
CM_ SG_ 2582846718 FaultVoltageStatus_21 "Measured voltage when fault occured";
CM_ SG_ 2582846718 FaultVoltageStatus_22 "Measured voltage when fault occured";
CM_ SG_ 2582846718 FaultVoltageStatus_23 "Measured voltage when fault occured";
CM_ SG_ 2582846718 FaultVoltageStatus_24 "Measured voltage when fault occured";
CM_ SG_ 2582846718 FaultVoltageStatus_25 "Measured voltage when fault occured";
CM_ SG_ 2582846718 FaultVoltageStatus_26 "Measured voltage when fault occured";
CM_ SG_ 2582846718 FaultVoltageStatus_27 "Measured voltage when fault occured";
CM_ SG_ 2582846718 FaultVoltageStatus_28 "Measured voltage when fault occured";
CM_ SG_ 2582846718 FaultVoltageStatus_29 "Measured voltage when fault occured";
CM_ SG_ 2582846718 FaultVoltageStatus_30 "Measured voltage when fault occured";
CM_ SG_ 2582846718 FaultVoltageStatus_31 "Measured voltage when fault occured";
CM_ SG_ 2582846718 FaultVoltageStatus_32 "Measured voltage when fault occured";
CM_ BO_ 2583650046 "Measured inputs voltages";
CM_ BO_ 2583650302 "Measured inputs voltages";
CM_ BO_ 2583650558 "Measured inputs voltages";
CM_ BO_ 2583650814 "Measured inputs voltages";
CM_ BO_ 2583651070 "Measured inputs voltages";
CM_ BO_ 2583654398 "Measured inputs voltages";
CM_ BO_ 2583654654 "Measured inputs voltages";
CM_ BO_ 2583654910 "Measured inputs voltages";
CM_ BO_ 2582845694 "Measured inputs voltages";
CM_ BO_ 2583646718 "This mesage reports current pin mode";
CM_ SG_ 2583646718 PinModeStatus_01 "Pin mode status";
CM_ SG_ 2583646718 PinPullModeStatus_01 "Pin pullup/pulldown mode status";
CM_ SG_ 2583646718 LoadDetectionStatus_01 "Report status of enabled/disabled load detection mode";
CM_ SG_ 2583646718 PinModeStatus_02 "Pin mode status";
CM_ SG_ 2583646718 PinPullModeStatus_02 "Pin pullup/pulldown mode status";
CM_ SG_ 2583646718 LoadDetectionStatus_02 "Report status of enabled/disabled load detection mode";
CM_ SG_ 2583646718 PinModeStatus_03 "Pin mode status";
CM_ SG_ 2583646718 PinPullModeStatus_03 "Pin pullup/pulldown mode status";
CM_ SG_ 2583646718 LoadDetectionStatus_03 "Report status of enabled/disabled load detection mode";
CM_ SG_ 2583646718 PinModeStatus_04 "Pin mode status";
CM_ SG_ 2583646718 PinPullModeStatus_04 "Pin pullup/pulldown mode status";
CM_ SG_ 2583646718 LoadDetectionStatus_04 "Report status of enabled/disabled load detection mode";
CM_ SG_ 2583646718 PinModeStatus_05 "Pin mode status";
CM_ SG_ 2583646718 PinPullModeStatus_05 "Pin pullup/pulldown mode status";
CM_ SG_ 2583646718 LoadDetectionStatus_05 "Report status of enabled/disabled load detection mode";
CM_ SG_ 2583646718 PinModeStatus_06 "Pin mode status";
CM_ SG_ 2583646718 PinPullModeStatus_06 "Pin pullup/pulldown mode status";
CM_ SG_ 2583646718 LoadDetectionStatus_06 "Report status of enabled/disabled load detection mode";
CM_ SG_ 2583646718 PinModeStatus_07 "Pin mode status";
CM_ SG_ 2583646718 PinPullModeStatus_07 "Pin pullup/pulldown mode status";
CM_ SG_ 2583646718 LoadDetectionStatus_07 "Report status of enabled/disabled load detection mode";
CM_ SG_ 2583646718 PinModeStatus_08 "Pin mode status";
CM_ SG_ 2583646718 PinPullModeStatus_08 "Pin pullup/pulldown mode status";
CM_ SG_ 2583646718 LoadDetectionStatus_08 "Report status of enabled/disabled load detection mode";
CM_ BO_ 2583646974 "This mesage reports current pin mode";
CM_ SG_ 2583646974 PinModeStatus_09 "Pin mode status";
CM_ SG_ 2583646974 PinPullModeStatus_09 "Pin pullup/pulldown mode status";
CM_ SG_ 2583646974 LoadDetectionStatus_09 "Report status of enabled/disabled load detection mode";
CM_ SG_ 2583646974 PinModeStatus_10 "Pin mode status";
CM_ SG_ 2583646974 PinPullModeStatus_10 "Pin pullup/pulldown mode status";
CM_ SG_ 2583646974 LoadDetectionStatus_10 "Report status of enabled/disabled load detection mode";
CM_ SG_ 2583646974 PinModeStatus_11 "Pin mode status";
CM_ SG_ 2583646974 PinPullModeStatus_11 "Pin pullup/pulldown mode status";
CM_ SG_ 2583646974 LoadDetectionStatus_11 "Report status of enabled/disabled load detection mode";
CM_ SG_ 2583646974 PinModeStatus_12 "Pin mode status";
CM_ SG_ 2583646974 PinPullModeStatus_12 "Pin pullup/pulldown mode status";
CM_ SG_ 2583646974 LoadDetectionStatus_12 "Report status of enabled/disabled load detection mode";
CM_ SG_ 2583646974 PinModeStatus_13 "Pin mode status";
CM_ SG_ 2583646974 PinPullModeStatus_13 "Pin pullup/pulldown mode status";
CM_ SG_ 2583646974 LoadDetectionStatus_13 "Report status of enabled/disabled load detection mode";
CM_ SG_ 2583646974 PinModeStatus_14 "Pin mode status";
CM_ SG_ 2583646974 PinPullModeStatus_14 "Pin pullup/pulldown mode status";
CM_ SG_ 2583646974 LoadDetectionStatus_14 "Report status of enabled/disabled load detection mode";
CM_ SG_ 2583646974 PinModeStatus_15 "Pin mode status";
CM_ SG_ 2583646974 PinPullModeStatus_15 "Pin pullup/pulldown mode status";
CM_ SG_ 2583646974 LoadDetectionStatus_15 "Report status of enabled/disabled load detection mode";
CM_ SG_ 2583646974 PinModeStatus_16 "Pin mode status";
CM_ SG_ 2583646974 PinPullModeStatus_16 "Pin pullup/pulldown mode status";
CM_ SG_ 2583646974 LoadDetectionStatus_16 "Report status of enabled/disabled load detection mode";
CM_ BO_ 2583647230 "This mesage reports current pin mode";
CM_ SG_ 2583647230 PinModeStatus_17 "Pin mode status";
CM_ SG_ 2583647230 PinPullModeStatus_17 "Pin pullup/pulldown mode status";
CM_ SG_ 2583647230 LoadDetectionStatus_17 "Report status of enabled/disabled load detection mode";
CM_ SG_ 2583647230 PinModeStatus_18 "Pin mode status";
CM_ SG_ 2583647230 PinPullModeStatus_18 "Pin pullup/pulldown mode status";
CM_ SG_ 2583647230 LoadDetectionStatus_18 "Report status of enabled/disabled load detection mode";
CM_ SG_ 2583647230 PinModeStatus_19 "Pin mode status";
CM_ SG_ 2583647230 PinPullModeStatus_19 "Pin pullup/pulldown mode status";
CM_ SG_ 2583647230 LoadDetectionStatus_19 "Report status of enabled/disabled load detection mode";
CM_ SG_ 2583647230 PinModeStatus_20 "Pin mode status";
CM_ SG_ 2583647230 PinPullModeStatus_20 "Pin pullup/pulldown mode status";
CM_ SG_ 2583647230 LoadDetectionStatus_20 "Report status of enabled/disabled load detection mode";
CM_ SG_ 2583647230 PinModeStatus_21 "Pin mode status";
CM_ SG_ 2583647230 PinPullModeStatus_21 "Pin pullup/pulldown mode status";
CM_ SG_ 2583647230 LoadDetectionStatus_21 "Report status of enabled/disabled load detection mode";
CM_ SG_ 2583647230 PinModeStatus_22 "Pin mode status";
CM_ SG_ 2583647230 PinPullModeStatus_22 "Pin pullup/pulldown mode status";
CM_ SG_ 2583647230 LoadDetectionStatus_22 "Report status of enabled/disabled load detection mode";
CM_ SG_ 2583647230 PinModeStatus_23 "Pin mode status";
CM_ SG_ 2583647230 PinPullModeStatus_23 "Pin pullup/pulldown mode status";
CM_ SG_ 2583647230 LoadDetectionStatus_23 "Report status of enabled/disabled load detection mode";
CM_ SG_ 2583647230 PinModeStatus_24 "Pin mode status";
CM_ SG_ 2583647230 PinPullModeStatus_24 "Pin pullup/pulldown mode status";
CM_ SG_ 2583647230 LoadDetectionStatus_24 "Report status of enabled/disabled load detection mode";
CM_ BO_ 2583647486 "This mesage reports current pin mode";
CM_ SG_ 2583647486 PinModeStatus_25 "Pin mode status";
CM_ SG_ 2583647486 PinPullModeStatus_25 "Pin pullup/pulldown mode status";
CM_ SG_ 2583647486 LoadDetectionStatus_25 "Report status of enabled/disabled load detection mode";
CM_ SG_ 2583647486 PinModeStatus_26 "Pin mode status";
CM_ SG_ 2583647486 PinPullModeStatus_26 "Pin pullup/pulldown mode status";
CM_ SG_ 2583647486 LoadDetectionStatus_26 "Report status of enabled/disabled load detection mode";
CM_ SG_ 2583647486 PinModeStatus_27 "Pin mode status";
CM_ SG_ 2583647486 PinPullModeStatus_27 "Pin pullup/pulldown mode status";
CM_ SG_ 2583647486 LoadDetectionStatus_27 "Report status of enabled/disabled load detection mode";
CM_ SG_ 2583647486 PinModeStatus_28 "Pin mode status";
CM_ SG_ 2583647486 PinPullModeStatus_28 "Pin pullup/pulldown mode status";
CM_ SG_ 2583647486 LoadDetectionStatus_28 "Report status of enabled/disabled load detection mode";
CM_ SG_ 2583647486 PinModeStatus_29 "Pin mode status";
CM_ SG_ 2583647486 PinPullModeStatus_29 "Pin pullup/pulldown mode status";
CM_ SG_ 2583647486 LoadDetectionStatus_29 "Report status of enabled/disabled load detection mode";
CM_ SG_ 2583647486 PinModeStatus_30 "Pin mode status";
CM_ SG_ 2583647486 PinPullModeStatus_30 "Pin pullup/pulldown mode status";
CM_ SG_ 2583647486 LoadDetectionStatus_30 "Report status of enabled/disabled load detection mode";
CM_ SG_ 2583647486 PinModeStatus_31 "Pin mode status";
CM_ SG_ 2583647486 PinPullModeStatus_31 "Pin pullup/pulldown mode status";
CM_ SG_ 2583647486 LoadDetectionStatus_31 "Report status of enabled/disabled load detection mode";
CM_ SG_ 2583647486 PinModeStatus_32 "Pin mode status";
CM_ SG_ 2583647486 PinPullModeStatus_32 "Pin pullup/pulldown mode status";
CM_ SG_ 2583647486 LoadDetectionStatus_32 "Report status of enabled/disabled load detection mode";
CM_ BO_ 2582846974 "This mesage reports current pin mode";
CM_ SG_ 2582846974 PinModeStatus_01 "Pin mode status";
CM_ SG_ 2582846974 PinPullModeStatus_01 "Pin pullup/pulldown mode status";
CM_ SG_ 2582846974 LoadDetectionStatus_01 "Report status of enabled/disabled load detection mode";
CM_ SG_ 2582846974 PinModeStatus_02 "Pin mode status";
CM_ SG_ 2582846974 PinPullModeStatus_02 "Pin pullup/pulldown mode status";
CM_ SG_ 2582846974 LoadDetectionStatus_02 "Report status of enabled/disabled load detection mode";
CM_ SG_ 2582846974 PinModeStatus_03 "Pin mode status";
CM_ SG_ 2582846974 PinPullModeStatus_03 "Pin pullup/pulldown mode status";
CM_ SG_ 2582846974 LoadDetectionStatus_03 "Report status of enabled/disabled load detection mode";
CM_ SG_ 2582846974 PinModeStatus_04 "Pin mode status";
CM_ SG_ 2582846974 PinPullModeStatus_04 "Pin pullup/pulldown mode status";
CM_ SG_ 2582846974 LoadDetectionStatus_04 "Report status of enabled/disabled load detection mode";
CM_ SG_ 2582846974 PinModeStatus_05 "Pin mode status";
CM_ SG_ 2582846974 PinPullModeStatus_05 "Pin pullup/pulldown mode status";
CM_ SG_ 2582846974 LoadDetectionStatus_05 "Report status of enabled/disabled load detection mode";
CM_ SG_ 2582846974 PinModeStatus_06 "Pin mode status";
CM_ SG_ 2582846974 PinPullModeStatus_06 "Pin pullup/pulldown mode status";
CM_ SG_ 2582846974 LoadDetectionStatus_06 "Report status of enabled/disabled load detection mode";
CM_ SG_ 2582846974 PinModeStatus_07 "Pin mode status";
CM_ SG_ 2582846974 PinPullModeStatus_07 "Pin pullup/pulldown mode status";
CM_ SG_ 2582846974 LoadDetectionStatus_07 "Report status of enabled/disabled load detection mode";
CM_ SG_ 2582846974 PinModeStatus_08 "Pin mode status";
CM_ SG_ 2582846974 PinPullModeStatus_08 "Pin pullup/pulldown mode status";
CM_ SG_ 2582846974 LoadDetectionStatus_08 "Report status of enabled/disabled load detection mode";
CM_ SG_ 2582846974 PinModeStatus_09 "Pin mode status";
CM_ SG_ 2582846974 PinPullModeStatus_09 "Pin pullup/pulldown mode status";
CM_ SG_ 2582846974 LoadDetectionStatus_09 "Report status of enabled/disabled load detection mode";
CM_ SG_ 2582846974 PinModeStatus_10 "Pin mode status";
CM_ SG_ 2582846974 PinPullModeStatus_10 "Pin pullup/pulldown mode status";
CM_ SG_ 2582846974 LoadDetectionStatus_10 "Report status of enabled/disabled load detection mode";
CM_ SG_ 2582846974 PinModeStatus_11 "Pin mode status";
CM_ SG_ 2582846974 PinPullModeStatus_11 "Pin pullup/pulldown mode status";
CM_ SG_ 2582846974 LoadDetectionStatus_11 "Report status of enabled/disabled load detection mode";
CM_ SG_ 2582846974 PinModeStatus_12 "Pin mode status";
CM_ SG_ 2582846974 PinPullModeStatus_12 "Pin pullup/pulldown mode status";
CM_ SG_ 2582846974 LoadDetectionStatus_12 "Report status of enabled/disabled load detection mode";
CM_ SG_ 2582846974 PinModeStatus_13 "Pin mode status";
CM_ SG_ 2582846974 PinPullModeStatus_13 "Pin pullup/pulldown mode status";
CM_ SG_ 2582846974 LoadDetectionStatus_13 "Report status of enabled/disabled load detection mode";
CM_ SG_ 2582846974 PinModeStatus_14 "Pin mode status";
CM_ SG_ 2582846974 PinPullModeStatus_14 "Pin pullup/pulldown mode status";
CM_ SG_ 2582846974 LoadDetectionStatus_14 "Report status of enabled/disabled load detection mode";
CM_ SG_ 2582846974 PinModeStatus_15 "Pin mode status";
CM_ SG_ 2582846974 PinPullModeStatus_15 "Pin pullup/pulldown mode status";
CM_ SG_ 2582846974 LoadDetectionStatus_15 "Report status of enabled/disabled load detection mode";
CM_ SG_ 2582846974 PinModeStatus_16 "Pin mode status";
CM_ SG_ 2582846974 PinPullModeStatus_16 "Pin pullup/pulldown mode status";
CM_ SG_ 2582846974 LoadDetectionStatus_16 "Report status of enabled/disabled load detection mode";
CM_ SG_ 2582846974 PinModeStatus_17 "Pin mode status";
CM_ SG_ 2582846974 PinPullModeStatus_17 "Pin pullup/pulldown mode status";
CM_ SG_ 2582846974 LoadDetectionStatus_17 "Report status of enabled/disabled load detection mode";
CM_ SG_ 2582846974 PinModeStatus_18 "Pin mode status";
CM_ SG_ 2582846974 PinPullModeStatus_18 "Pin pullup/pulldown mode status";
CM_ SG_ 2582846974 LoadDetectionStatus_18 "Report status of enabled/disabled load detection mode";
CM_ SG_ 2582846974 PinModeStatus_19 "Pin mode status";
CM_ SG_ 2582846974 PinPullModeStatus_19 "Pin pullup/pulldown mode status";
CM_ SG_ 2582846974 LoadDetectionStatus_19 "Report status of enabled/disabled load detection mode";
CM_ SG_ 2582846974 PinModeStatus_20 "Pin mode status";
CM_ SG_ 2582846974 PinPullModeStatus_20 "Pin pullup/pulldown mode status";
CM_ SG_ 2582846974 LoadDetectionStatus_20 "Report status of enabled/disabled load detection mode";
CM_ SG_ 2582846974 PinModeStatus_21 "Pin mode status";
CM_ SG_ 2582846974 PinPullModeStatus_21 "Pin pullup/pulldown mode status";
CM_ SG_ 2582846974 LoadDetectionStatus_21 "Report status of enabled/disabled load detection mode";
CM_ SG_ 2582846974 PinModeStatus_22 "Pin mode status";
CM_ SG_ 2582846974 PinPullModeStatus_22 "Pin pullup/pulldown mode status";
CM_ SG_ 2582846974 LoadDetectionStatus_22 "Report status of enabled/disabled load detection mode";
CM_ SG_ 2582846974 PinModeStatus_23 "Pin mode status";
CM_ SG_ 2582846974 PinPullModeStatus_23 "Pin pullup/pulldown mode status";
CM_ SG_ 2582846974 LoadDetectionStatus_23 "Report status of enabled/disabled load detection mode";
CM_ SG_ 2582846974 PinModeStatus_24 "Pin mode status";
CM_ SG_ 2582846974 PinPullModeStatus_24 "Pin pullup/pulldown mode status";
CM_ SG_ 2582846974 LoadDetectionStatus_24 "Report status of enabled/disabled load detection mode";
CM_ SG_ 2582846974 PinModeStatus_25 "Pin mode status";
CM_ SG_ 2582846974 PinPullModeStatus_25 "Pin pullup/pulldown mode status";
CM_ SG_ 2582846974 LoadDetectionStatus_25 "Report status of enabled/disabled load detection mode";
CM_ SG_ 2582846974 PinModeStatus_26 "Pin mode status";
CM_ SG_ 2582846974 PinPullModeStatus_26 "Pin pullup/pulldown mode status";
CM_ SG_ 2582846974 LoadDetectionStatus_26 "Report status of enabled/disabled load detection mode";
CM_ SG_ 2582846974 PinModeStatus_27 "Pin mode status";
CM_ SG_ 2582846974 PinPullModeStatus_27 "Pin pullup/pulldown mode status";
CM_ SG_ 2582846974 LoadDetectionStatus_27 "Report status of enabled/disabled load detection mode";
CM_ SG_ 2582846974 PinModeStatus_28 "Pin mode status";
CM_ SG_ 2582846974 PinPullModeStatus_28 "Pin pullup/pulldown mode status";
CM_ SG_ 2582846974 LoadDetectionStatus_28 "Report status of enabled/disabled load detection mode";
CM_ SG_ 2582846974 PinModeStatus_29 "Pin mode status";
CM_ SG_ 2582846974 PinPullModeStatus_29 "Pin pullup/pulldown mode status";
CM_ SG_ 2582846974 LoadDetectionStatus_29 "Report status of enabled/disabled load detection mode";
CM_ SG_ 2582846974 PinModeStatus_30 "Pin mode status";
CM_ SG_ 2582846974 PinPullModeStatus_30 "Pin pullup/pulldown mode status";
CM_ SG_ 2582846974 LoadDetectionStatus_30 "Report status of enabled/disabled load detection mode";
CM_ SG_ 2582846974 PinModeStatus_31 "Pin mode status";
CM_ SG_ 2582846974 PinPullModeStatus_31 "Pin pullup/pulldown mode status";
CM_ SG_ 2582846974 LoadDetectionStatus_31 "Report status of enabled/disabled load detection mode";
CM_ SG_ 2582846974 PinModeStatus_32 "Pin mode status";
CM_ SG_ 2582846974 PinPullModeStatus_32 "Pin pullup/pulldown mode status";
CM_ SG_ 2582846974 LoadDetectionStatus_32 "Report status of enabled/disabled load detection mode";
CM_ BO_ 2650761214 "PWM Outputs Frequencies";
CM_ SG_ 2650761214 PwmFrequencyStatus_01 "PWM Frequency on output 01";
CM_ SG_ 2650761214 PwmFrequencyStatus_02 "PWM Frequency on output 02";
CM_ SG_ 2650761214 PwmFrequencyStatus_03 "PWM Frequency on output 03";
CM_ SG_ 2650761214 PwmFrequencyStatus_04 "PWM Frequency on output 04";
CM_ BO_ 2650761470 "PWM Outputs Frequencies";
CM_ SG_ 2650761470 PwmFrequencyStatus_05 "PWM Frequency on output 05";
CM_ SG_ 2650761470 PwmFrequencyStatus_06 "PWM Frequency on output 06";
CM_ SG_ 2650761470 PwmFrequencyStatus_07 "PWM Frequency on output 07";
CM_ SG_ 2650761470 PwmFrequencyStatus_08 "PWM Frequency on output 08";
CM_ BO_ 2650761726 "PWM Outputs Frequencies";
CM_ SG_ 2650761726 PwmFrequencyStatus_09 "PWM Frequency on output 09";
CM_ SG_ 2650761726 PwmFrequencyStatus_10 "PWM Frequency on output 10";
CM_ SG_ 2650761726 PwmFrequencyStatus_11 "PWM Frequency on output 11";
CM_ SG_ 2650761726 PwmFrequencyStatus_12 "PWM Frequency on output 12";
CM_ BO_ 2650761982 "PWM Outputs Frequencies";
CM_ SG_ 2650761982 PwmFrequencyStatus_13 "PWM Frequency on output 13";
CM_ SG_ 2650761982 PwmFrequencyStatus_14 "PWM Frequency on output 14";
CM_ SG_ 2650761982 PwmFrequencyStatus_15 "PWM Frequency on output 15";
CM_ SG_ 2650761982 PwmFrequencyStatus_16 "PWM Frequency on output 16";
CM_ BO_ 2650762238 "PWM Outputs Frequencies";
CM_ SG_ 2650762238 PwmFrequencyStatus_17 "PWM Frequency on output 17";
CM_ SG_ 2650762238 PwmFrequencyStatus_18 "PWM Frequency on output 18";
CM_ SG_ 2650762238 PwmFrequencyStatus_19 "PWM Frequency on output 19";
CM_ SG_ 2650762238 PwmFrequencyStatus_20 "PWM Frequency on output 20";
CM_ BO_ 2650762494 "PWM Outputs Frequencies";
CM_ SG_ 2650762494 PwmFrequencyStatus_21 "PWM Frequency on output 21";
CM_ SG_ 2650762494 PwmFrequencyStatus_22 "PWM Frequency on output 22";
CM_ SG_ 2650762494 PwmFrequencyStatus_23 "PWM Frequency on output 23";
CM_ SG_ 2650762494 PwmFrequencyStatus_24 "PWM Frequency on output 24";
CM_ BO_ 2650762750 "PWM Outputs Frequencies";
CM_ SG_ 2650762750 PwmFrequencyStatus_25 "PWM Frequency on output 25";
CM_ SG_ 2650762750 PwmFrequencyStatus_26 "PWM Frequency on output 26";
CM_ SG_ 2650762750 PwmFrequencyStatus_27 "PWM Frequency on output 27";
CM_ SG_ 2650762750 PwmFrequencyStatus_28 "PWM Frequency on output 28";
CM_ BO_ 2650763006 "PWM Outputs Frequencies";
CM_ SG_ 2650763006 PwmFrequencyStatus_29 "PWM Frequency on output 29";
CM_ SG_ 2650763006 PwmFrequencyStatus_30 "PWM Frequency on output 30";
CM_ SG_ 2650763006 PwmFrequencyStatus_31 "PWM Frequency on output 31";
CM_ SG_ 2650763006 PwmFrequencyStatus_32 "PWM Frequency on output 32";
CM_ BO_ 2649956094 "PWM Outputs Frequencies";
CM_ SG_ 2649956094 PwmFrequencyStatus_01 "PWM Frequency on output 01";
CM_ SG_ 2649956094 PwmFrequencyStatus_02 "PWM Frequency on output 02";
CM_ SG_ 2649956094 PwmFrequencyStatus_03 "PWM Frequency on output 03";
CM_ SG_ 2649956094 PwmFrequencyStatus_04 "PWM Frequency on output 04";
CM_ SG_ 2649956094 PwmFrequencyStatus_05 "PWM Frequency on output 05";
CM_ SG_ 2649956094 PwmFrequencyStatus_06 "PWM Frequency on output 06";
CM_ SG_ 2649956094 PwmFrequencyStatus_07 "PWM Frequency on output 07";
CM_ SG_ 2649956094 PwmFrequencyStatus_08 "PWM Frequency on output 08";
CM_ SG_ 2649956094 PwmFrequencyStatus_09 "PWM Frequency on output 09";
CM_ SG_ 2649956094 PwmFrequencyStatus_10 "PWM Frequency on output 10";
CM_ SG_ 2649956094 PwmFrequencyStatus_11 "PWM Frequency on output 11";
CM_ SG_ 2649956094 PwmFrequencyStatus_12 "PWM Frequency on output 12";
CM_ SG_ 2649956094 PwmFrequencyStatus_13 "PWM Frequency on output 13";
CM_ SG_ 2649956094 PwmFrequencyStatus_14 "PWM Frequency on output 14";
CM_ SG_ 2649956094 PwmFrequencyStatus_15 "PWM Frequency on output 15";
CM_ SG_ 2649956094 PwmFrequencyStatus_16 "PWM Frequency on output 16";
CM_ SG_ 2649956094 PwmFrequencyStatus_17 "PWM Frequency on output 17";
CM_ SG_ 2649956094 PwmFrequencyStatus_18 "PWM Frequency on output 18";
CM_ SG_ 2649956094 PwmFrequencyStatus_19 "PWM Frequency on output 19";
CM_ SG_ 2649956094 PwmFrequencyStatus_20 "PWM Frequency on output 20";
CM_ SG_ 2649956094 PwmFrequencyStatus_21 "PWM Frequency on output 21";
CM_ SG_ 2649956094 PwmFrequencyStatus_22 "PWM Frequency on output 22";
CM_ SG_ 2649956094 PwmFrequencyStatus_23 "PWM Frequency on output 23";
CM_ SG_ 2649956094 PwmFrequencyStatus_24 "PWM Frequency on output 24";
CM_ SG_ 2649956094 PwmFrequencyStatus_25 "PWM Frequency on output 25";
CM_ SG_ 2649956094 PwmFrequencyStatus_26 "PWM Frequency on output 26";
CM_ SG_ 2649956094 PwmFrequencyStatus_27 "PWM Frequency on output 27";
CM_ SG_ 2649956094 PwmFrequencyStatus_28 "PWM Frequency on output 28";
CM_ SG_ 2649956094 PwmFrequencyStatus_29 "PWM Frequency on output 29";
CM_ SG_ 2649956094 PwmFrequencyStatus_30 "PWM Frequency on output 30";
CM_ SG_ 2649956094 PwmFrequencyStatus_31 "PWM Frequency on output 31";
CM_ SG_ 2649956094 PwmFrequencyStatus_32 "PWM Frequency on output 32";
CM_ BO_ 2582847998 "Current configured output duty value";
CM_ SG_ 2582847998 QEncoderDirection_Q01 "Quadrature encoder direction";
CM_ SG_ 2582847998 QEncoderCounter_Q01 "Quadrature encoder impulse counter";
CM_ BO_ 2583649790 "Measured output temperature 1";
CM_ SG_ 2583649790 TemperatureStatus_t01 "Temperature sensor 1";
CM_ SG_ 2583649790 TemperatureStatus_t02 "Temperature sensor 2";
CM_ SG_ 2583649790 TemperatureStatus_t03 "Temperature sensor 3";
CM_ SG_ 2583649790 TemperatureStatus_t04 "Temperature sensor 4";
CM_ SG_ 2583649790 TemperatureStatus_t05 "Temperature sensor 5";
CM_ SG_ 2583649790 TemperatureStatus_t06 "Temperature sensor 6";
CM_ SG_ 2583649790 TemperatureStatus_t07 "Temperature sensor 7";
CM_ SG_ 2583649790 TemperatureStatus_t08 "Temperature sensor 8";
BA_DEF_ BO_ "GenMsgCycleTime" INT 0 3600000;
BA_DEF_ BO_ "GenMsgILSupport" ENUM "No","Yes";
BA_DEF_ BO_ "GenMsgRequestable" INT 0 1;
BA_DEF_ BO_ "GenMsgSendType" ENUM "cyclic","NotUsed","NotUsed","NotUsed","NotUsed","NotUsed","NotUsed","IfActive","noMsgSendType";
BA_DEF_ SG_ "GenSigEVName" STRING ;
BA_DEF_ SG_ "GenSigILSupport" ENUM "No","Yes";
BA_DEF_ SG_ "GenSigSendType" ENUM "Cyclic","OnWrite","OnWriteWithRepetition","OnChange","OnChangeWithRepetition","IfActive","IfActiveWithRepetition","NoSigSendType";
BA_DEF_ SG_ "GenSigStartValue" INT 0 2147483647;
BA_DEF_ SG_ "SPN" INT 0 524287;
BA_DEF_ BO_ "SendOnChange" ENUM "No","Yes";
BA_DEF_ SG_ "SigType" ENUM "Default","Range","RangeSigned","ASCII","Discrete","Control","ReferencePGN","DTC","StringDelimiter","StringLength","StringLengthControl","MessageCounter","MessageChecksum";
BA_DEF_ BO_ "VFrameFormat" ENUM "StandardCAN","ExtendedCAN","reserved","J1939PG","reserved","reserved","reserved","reserved","reserved","reserved","reserved","reserved","reserved","reserved","StandardCAN_FD","ExtendedCAN_FD";
BA_DEF_DEF_ "GenMsgCycleTime" 0;
BA_DEF_DEF_ "GenMsgILSupport" "Yes";
BA_DEF_DEF_ "GenMsgRequestable" 1;
BA_DEF_DEF_ "GenMsgSendType" "noMsgSendType";
BA_DEF_DEF_ "GenSigEVName" "Env@Nodename_@Signame";
BA_DEF_DEF_ "GenSigILSupport" "Yes";
BA_DEF_DEF_ "GenSigSendType" "NoSigSendType";
BA_DEF_DEF_ "GenSigStartValue" 0;
BA_DEF_DEF_ "SPN" 0;
BA_DEF_DEF_ "SendOnChange" "No";
BA_DEF_DEF_ "SigType" "Default";
BA_DEF_DEF_ "VFrameFormat" "J1939PG";
BA_ "GenMsgCycleTime" BO_ 2582846206 1000;
BA_ "GenMsgRequestable" BO_ 2582846206 0;
BA_ "GenMsgSendType" BO_ 2582846206 0;
BA_ "GenMsgCycleTime" BO_ 2582839550 1000;
BA_ "GenMsgRequestable" BO_ 2582839550 0;
BA_ "GenMsgSendType" BO_ 2582839550 0;
BA_ "GenMsgCycleTime" BO_ 2582839806 1000;
BA_ "GenMsgRequestable" BO_ 2582839806 0;
BA_ "GenMsgSendType" BO_ 2582839806 0;
BA_ "GenMsgCycleTime" BO_ 2582840062 1000;
BA_ "GenMsgRequestable" BO_ 2582840062 0;
BA_ "GenMsgSendType" BO_ 2582840062 0;
BA_ "GenMsgCycleTime" BO_ 2582840318 1000;
BA_ "GenMsgRequestable" BO_ 2582840318 0;
BA_ "GenMsgSendType" BO_ 2582840318 0;
BA_ "GenMsgCycleTime" BO_ 2582840574 1000;
BA_ "GenMsgRequestable" BO_ 2582840574 0;
BA_ "GenMsgSendType" BO_ 2582840574 0;
BA_ "GenMsgCycleTime" BO_ 2582840830 1000;
BA_ "GenMsgRequestable" BO_ 2582840830 0;
BA_ "GenMsgSendType" BO_ 2582840830 0;
BA_ "GenMsgCycleTime" BO_ 2582841086 1000;
BA_ "GenMsgRequestable" BO_ 2582841086 0;
BA_ "GenMsgSendType" BO_ 2582841086 0;
BA_ "GenMsgCycleTime" BO_ 2582841342 1000;
BA_ "GenMsgRequestable" BO_ 2582841342 0;
BA_ "GenMsgSendType" BO_ 2582841342 0;
BA_ "GenMsgCycleTime" BO_ 2582846462 1000;
BA_ "GenMsgRequestable" BO_ 2582846462 0;
BA_ "GenMsgSendType" BO_ 2582846462 0;
BA_ "GenMsgCycleTime" BO_ 2582841598 1000;
BA_ "GenMsgRequestable" BO_ 2582841598 0;
BA_ "GenMsgSendType" BO_ 2582841598 0;
BA_ "GenMsgCycleTime" BO_ 2582841854 1000;
BA_ "GenMsgRequestable" BO_ 2582841854 0;
BA_ "GenMsgSendType" BO_ 2582841854 0;
BA_ "GenMsgCycleTime" BO_ 2582842110 1000;
BA_ "GenMsgRequestable" BO_ 2582842110 0;
BA_ "GenMsgSendType" BO_ 2582842110 0;
BA_ "GenMsgCycleTime" BO_ 2582842366 1000;
BA_ "GenMsgRequestable" BO_ 2582842366 0;
BA_ "GenMsgSendType" BO_ 2582842366 0;
BA_ "GenMsgCycleTime" BO_ 2582842622 1000;
BA_ "GenMsgRequestable" BO_ 2582842622 0;
BA_ "GenMsgSendType" BO_ 2582842622 0;
BA_ "GenMsgCycleTime" BO_ 2582842878 1000;
BA_ "GenMsgRequestable" BO_ 2582842878 0;
BA_ "GenMsgSendType" BO_ 2582842878 0;
BA_ "GenMsgCycleTime" BO_ 2582843134 1000;
BA_ "GenMsgRequestable" BO_ 2582843134 0;
BA_ "GenMsgSendType" BO_ 2582843134 0;
BA_ "GenMsgCycleTime" BO_ 2582843390 1000;
BA_ "GenMsgRequestable" BO_ 2582843390 0;
BA_ "GenMsgSendType" BO_ 2582843390 0;
BA_ "GenMsgCycleTime" BO_ 2582846718 1000;
BA_ "GenMsgRequestable" BO_ 2582846718 0;
BA_ "GenMsgSendType" BO_ 2582846718 0;
BA_ "GenMsgCycleTime" BO_ 2583650046 100;
BA_ "GenMsgRequestable" BO_ 2583650046 0;
BA_ "GenMsgSendType" BO_ 2583650046 0;
BA_ "GenMsgCycleTime" BO_ 2583650302 100;
BA_ "GenMsgRequestable" BO_ 2583650302 0;
BA_ "GenMsgSendType" BO_ 2583650302 0;
BA_ "GenMsgCycleTime" BO_ 2583650558 100;
BA_ "GenMsgRequestable" BO_ 2583650558 0;
BA_ "GenMsgSendType" BO_ 2583650558 0;
BA_ "GenMsgCycleTime" BO_ 2583650814 100;
BA_ "GenMsgRequestable" BO_ 2583650814 0;
BA_ "GenMsgSendType" BO_ 2583650814 0;
BA_ "GenMsgCycleTime" BO_ 2583651070 100;
BA_ "GenMsgRequestable" BO_ 2583651070 0;
BA_ "GenMsgSendType" BO_ 2583651070 0;
BA_ "GenMsgCycleTime" BO_ 2583654398 100;
BA_ "GenMsgRequestable" BO_ 2583654398 0;
BA_ "GenMsgSendType" BO_ 2583654398 0;
BA_ "GenMsgCycleTime" BO_ 2583654654 100;
BA_ "GenMsgRequestable" BO_ 2583654654 0;
BA_ "GenMsgSendType" BO_ 2583654654 0;
BA_ "GenMsgCycleTime" BO_ 2583654910 100;
BA_ "GenMsgRequestable" BO_ 2583654910 0;
BA_ "GenMsgSendType" BO_ 2583654910 0;
BA_ "GenMsgCycleTime" BO_ 2582845694 100;
BA_ "GenMsgRequestable" BO_ 2582845694 0;
BA_ "GenMsgSendType" BO_ 2582845694 0;
BA_ "GenMsgCycleTime" BO_ 2583646718 1000;
BA_ "GenMsgRequestable" BO_ 2583646718 0;
BA_ "GenMsgSendType" BO_ 2583646718 0;
BA_ "GenMsgCycleTime" BO_ 2583646974 1000;
BA_ "GenMsgRequestable" BO_ 2583646974 0;
BA_ "GenMsgSendType" BO_ 2583646974 0;
BA_ "GenMsgCycleTime" BO_ 2583647230 1000;
BA_ "GenMsgRequestable" BO_ 2583647230 0;
BA_ "GenMsgSendType" BO_ 2583647230 0;
BA_ "GenMsgCycleTime" BO_ 2583647486 1000;
BA_ "GenMsgRequestable" BO_ 2583647486 0;
BA_ "GenMsgSendType" BO_ 2583647486 0;
BA_ "GenMsgCycleTime" BO_ 2582846974 1000;
BA_ "GenMsgRequestable" BO_ 2582846974 0;
BA_ "GenMsgSendType" BO_ 2582846974 0;
BA_ "GenMsgCycleTime" BO_ 2650761214 1000;
BA_ "GenMsgSendType" BO_ 2650761214 0;
BA_ "GenMsgCycleTime" BO_ 2650761470 1000;
BA_ "GenMsgSendType" BO_ 2650761470 0;
BA_ "GenMsgCycleTime" BO_ 2650761726 1000;
BA_ "GenMsgSendType" BO_ 2650761726 0;
BA_ "GenMsgCycleTime" BO_ 2650761982 1000;
BA_ "GenMsgSendType" BO_ 2650761982 0;
BA_ "GenMsgCycleTime" BO_ 2650762238 1000;
BA_ "GenMsgSendType" BO_ 2650762238 0;
BA_ "GenMsgCycleTime" BO_ 2650762494 1000;
BA_ "GenMsgSendType" BO_ 2650762494 0;
BA_ "GenMsgCycleTime" BO_ 2650762750 1000;
BA_ "GenMsgSendType" BO_ 2650762750 0;
BA_ "GenMsgCycleTime" BO_ 2650763006 1000;
BA_ "GenMsgSendType" BO_ 2650763006 0;
BA_ "GenMsgCycleTime" BO_ 2649956094 1000;
BA_ "GenMsgSendType" BO_ 2649956094 0;
BA_ "GenMsgCycleTime" BO_ 2582847998 100;
BA_ "GenMsgRequestable" BO_ 2582847998 0;
BA_ "GenMsgSendType" BO_ 2582847998 0;
BA_ "GenMsgCycleTime" BO_ 2583649790 100;
BA_ "GenMsgRequestable" BO_ 2583649790 0;
BA_ "GenMsgSendType" BO_ 2583649790 0;
BA_ "SPN" SG_ 2582846206 FaultCountStatus_01 516996;
BA_ "SigType" SG_ 2582846206 FaultCountStatus_01 1;
BA_ "SPN" SG_ 2582846206 FaultCountStatus_02 516997;
BA_ "SigType" SG_ 2582846206 FaultCountStatus_02 1;
BA_ "SPN" SG_ 2582846206 FaultCountStatus_03 516998;
BA_ "SigType" SG_ 2582846206 FaultCountStatus_03 1;
BA_ "SPN" SG_ 2582846206 FaultCountStatus_04 516999;
BA_ "SigType" SG_ 2582846206 FaultCountStatus_04 1;
BA_ "SPN" SG_ 2582846206 FaultCountStatus_05 519000;
BA_ "SigType" SG_ 2582846206 FaultCountStatus_05 1;
BA_ "SPN" SG_ 2582846206 FaultCountStatus_06 519001;
BA_ "SigType" SG_ 2582846206 FaultCountStatus_06 1;
BA_ "SPN" SG_ 2582846206 FaultCountStatus_07 519002;
BA_ "SigType" SG_ 2582846206 FaultCountStatus_07 1;
BA_ "SPN" SG_ 2582846206 FaultCountStatus_08 519003;
BA_ "SigType" SG_ 2582846206 FaultCountStatus_08 1;
BA_ "SPN" SG_ 2582846206 FaultCountStatus_09 519004;
BA_ "SigType" SG_ 2582846206 FaultCountStatus_09 1;
BA_ "SPN" SG_ 2582846206 FaultCountStatus_10 519005;
BA_ "SigType" SG_ 2582846206 FaultCountStatus_10 1;
BA_ "SPN" SG_ 2582846206 FaultCountStatus_11 519006;
BA_ "SigType" SG_ 2582846206 FaultCountStatus_11 1;
BA_ "SPN" SG_ 2582846206 FaultCountStatus_12 519007;
BA_ "SigType" SG_ 2582846206 FaultCountStatus_12 1;
BA_ "SPN" SG_ 2582846206 FaultCountStatus_13 519008;
BA_ "SigType" SG_ 2582846206 FaultCountStatus_13 1;
BA_ "SPN" SG_ 2582846206 FaultCountStatus_14 519009;
BA_ "SigType" SG_ 2582846206 FaultCountStatus_14 1;
BA_ "SPN" SG_ 2582846206 FaultCountStatus_15 519010;
BA_ "SigType" SG_ 2582846206 FaultCountStatus_15 1;
BA_ "SPN" SG_ 2582846206 FaultCountStatus_16 519011;
BA_ "SigType" SG_ 2582846206 FaultCountStatus_16 1;
BA_ "SPN" SG_ 2582846206 FaultCountStatus_17 519012;
BA_ "SigType" SG_ 2582846206 FaultCountStatus_17 1;
BA_ "SPN" SG_ 2582846206 FaultCountStatus_18 519013;
BA_ "SigType" SG_ 2582846206 FaultCountStatus_18 1;
BA_ "SPN" SG_ 2582846206 FaultCountStatus_19 519014;
BA_ "SigType" SG_ 2582846206 FaultCountStatus_19 1;
BA_ "SPN" SG_ 2582846206 FaultCountStatus_20 519015;
BA_ "SigType" SG_ 2582846206 FaultCountStatus_20 1;
BA_ "SPN" SG_ 2582846206 FaultCountStatus_21 519016;
BA_ "SigType" SG_ 2582846206 FaultCountStatus_21 1;
BA_ "SPN" SG_ 2582846206 FaultCountStatus_22 519017;
BA_ "SigType" SG_ 2582846206 FaultCountStatus_22 1;
BA_ "SPN" SG_ 2582846206 FaultCountStatus_23 519018;
BA_ "SigType" SG_ 2582846206 FaultCountStatus_23 1;
BA_ "SPN" SG_ 2582846206 FaultCountStatus_24 519019;
BA_ "SigType" SG_ 2582846206 FaultCountStatus_24 1;
BA_ "SPN" SG_ 2582846206 FaultCountStatus_25 519020;
BA_ "SigType" SG_ 2582846206 FaultCountStatus_25 1;
BA_ "SPN" SG_ 2582846206 FaultCountStatus_26 519021;
BA_ "SigType" SG_ 2582846206 FaultCountStatus_26 1;
BA_ "SPN" SG_ 2582846206 FaultCountStatus_27 519022;
BA_ "SigType" SG_ 2582846206 FaultCountStatus_27 1;
BA_ "SPN" SG_ 2582846206 FaultCountStatus_28 519023;
BA_ "SigType" SG_ 2582846206 FaultCountStatus_28 1;
BA_ "SPN" SG_ 2582846206 FaultCountStatus_29 519024;
BA_ "SigType" SG_ 2582846206 FaultCountStatus_29 1;
BA_ "SPN" SG_ 2582846206 FaultCountStatus_30 519025;
BA_ "SigType" SG_ 2582846206 FaultCountStatus_30 1;
BA_ "SPN" SG_ 2582846206 FaultCountStatus_31 519026;
BA_ "SigType" SG_ 2582846206 FaultCountStatus_31 1;
BA_ "SPN" SG_ 2582846206 FaultCountStatus_32 519027;
BA_ "SigType" SG_ 2582846206 FaultCountStatus_32 1;
BA_ "GenSigStartValue" SG_ 2582839550 FaultCurrentStatus_01 32000;
BA_ "SPN" SG_ 2582839550 FaultCurrentStatus_01 519028;
BA_ "SigType" SG_ 2582839550 FaultCurrentStatus_01 1;
BA_ "GenSigStartValue" SG_ 2582839550 FaultCurrentStatus_02 32000;
BA_ "SPN" SG_ 2582839550 FaultCurrentStatus_02 519029;
BA_ "SigType" SG_ 2582839550 FaultCurrentStatus_02 1;
BA_ "GenSigStartValue" SG_ 2582839550 FaultCurrentStatus_03 32000;
BA_ "SPN" SG_ 2582839550 FaultCurrentStatus_03 519030;
BA_ "SigType" SG_ 2582839550 FaultCurrentStatus_03 1;
BA_ "GenSigStartValue" SG_ 2582839550 FaultCurrentStatus_04 32000;
BA_ "SPN" SG_ 2582839550 FaultCurrentStatus_04 519031;
BA_ "SigType" SG_ 2582839550 FaultCurrentStatus_04 1;
BA_ "GenSigStartValue" SG_ 2582839806 FaultCurrentStatus_05 32000;
BA_ "SPN" SG_ 2582839806 FaultCurrentStatus_05 519032;
BA_ "SigType" SG_ 2582839806 FaultCurrentStatus_05 1;
BA_ "GenSigStartValue" SG_ 2582839806 FaultCurrentStatus_06 32000;
BA_ "SPN" SG_ 2582839806 FaultCurrentStatus_06 519033;
BA_ "SigType" SG_ 2582839806 FaultCurrentStatus_06 1;
BA_ "GenSigStartValue" SG_ 2582839806 FaultCurrentStatus_07 32000;
BA_ "SPN" SG_ 2582839806 FaultCurrentStatus_07 519034;
BA_ "SigType" SG_ 2582839806 FaultCurrentStatus_07 1;
BA_ "GenSigStartValue" SG_ 2582839806 FaultCurrentStatus_08 32000;
BA_ "SPN" SG_ 2582839806 FaultCurrentStatus_08 519035;
BA_ "SigType" SG_ 2582839806 FaultCurrentStatus_08 1;
BA_ "GenSigStartValue" SG_ 2582840062 FaultCurrentStatus_09 32000;
BA_ "SPN" SG_ 2582840062 FaultCurrentStatus_09 519036;
BA_ "SigType" SG_ 2582840062 FaultCurrentStatus_09 1;
BA_ "GenSigStartValue" SG_ 2582840062 FaultCurrentStatus_10 32000;
BA_ "SPN" SG_ 2582840062 FaultCurrentStatus_10 519037;
BA_ "SigType" SG_ 2582840062 FaultCurrentStatus_10 1;
BA_ "GenSigStartValue" SG_ 2582840062 FaultCurrentStatus_11 32000;
BA_ "SPN" SG_ 2582840062 FaultCurrentStatus_11 519038;
BA_ "SigType" SG_ 2582840062 FaultCurrentStatus_11 1;
BA_ "GenSigStartValue" SG_ 2582840062 FaultCurrentStatus_12 32000;
BA_ "SPN" SG_ 2582840062 FaultCurrentStatus_12 519039;
BA_ "SigType" SG_ 2582840062 FaultCurrentStatus_12 1;
BA_ "GenSigStartValue" SG_ 2582840318 FaultCurrentStatus_13 32000;
BA_ "SPN" SG_ 2582840318 FaultCurrentStatus_13 519040;
BA_ "SigType" SG_ 2582840318 FaultCurrentStatus_13 1;
BA_ "GenSigStartValue" SG_ 2582840318 FaultCurrentStatus_14 32000;
BA_ "SPN" SG_ 2582840318 FaultCurrentStatus_14 519041;
BA_ "SigType" SG_ 2582840318 FaultCurrentStatus_14 1;
BA_ "GenSigStartValue" SG_ 2582840318 FaultCurrentStatus_15 32000;
BA_ "SPN" SG_ 2582840318 FaultCurrentStatus_15 519042;
BA_ "SigType" SG_ 2582840318 FaultCurrentStatus_15 1;
BA_ "GenSigStartValue" SG_ 2582840318 FaultCurrentStatus_16 32000;
BA_ "SPN" SG_ 2582840318 FaultCurrentStatus_16 519043;
BA_ "SigType" SG_ 2582840318 FaultCurrentStatus_16 1;
BA_ "GenSigStartValue" SG_ 2582840574 FaultCurrentStatus_17 32000;
BA_ "SPN" SG_ 2582840574 FaultCurrentStatus_17 519044;
BA_ "SigType" SG_ 2582840574 FaultCurrentStatus_17 1;
BA_ "GenSigStartValue" SG_ 2582840574 FaultCurrentStatus_18 32000;
BA_ "SPN" SG_ 2582840574 FaultCurrentStatus_18 519045;
BA_ "SigType" SG_ 2582840574 FaultCurrentStatus_18 1;
BA_ "GenSigStartValue" SG_ 2582840574 FaultCurrentStatus_19 32000;
BA_ "SPN" SG_ 2582840574 FaultCurrentStatus_19 519046;
BA_ "SigType" SG_ 2582840574 FaultCurrentStatus_19 1;
BA_ "GenSigStartValue" SG_ 2582840574 FaultCurrentStatus_20 32000;
BA_ "SPN" SG_ 2582840574 FaultCurrentStatus_20 519047;
BA_ "SigType" SG_ 2582840574 FaultCurrentStatus_20 1;
BA_ "GenSigStartValue" SG_ 2582840830 FaultCurrentStatus_21 32000;
BA_ "SPN" SG_ 2582840830 FaultCurrentStatus_21 519048;
BA_ "SigType" SG_ 2582840830 FaultCurrentStatus_21 1;
BA_ "GenSigStartValue" SG_ 2582840830 FaultCurrentStatus_22 32000;
BA_ "SPN" SG_ 2582840830 FaultCurrentStatus_22 519049;
BA_ "SigType" SG_ 2582840830 FaultCurrentStatus_22 1;
BA_ "GenSigStartValue" SG_ 2582840830 FaultCurrentStatus_23 32000;
BA_ "SPN" SG_ 2582840830 FaultCurrentStatus_23 519050;
BA_ "SigType" SG_ 2582840830 FaultCurrentStatus_23 1;
BA_ "GenSigStartValue" SG_ 2582840830 FaultCurrentStatus_24 32000;
BA_ "SPN" SG_ 2582840830 FaultCurrentStatus_24 519051;
BA_ "SigType" SG_ 2582840830 FaultCurrentStatus_24 1;
BA_ "GenSigStartValue" SG_ 2582841086 FaultCurrentStatus_25 32000;
BA_ "SPN" SG_ 2582841086 FaultCurrentStatus_25 519052;
BA_ "SigType" SG_ 2582841086 FaultCurrentStatus_25 1;
BA_ "GenSigStartValue" SG_ 2582841086 FaultCurrentStatus_26 32000;
BA_ "SPN" SG_ 2582841086 FaultCurrentStatus_26 519053;
BA_ "SigType" SG_ 2582841086 FaultCurrentStatus_26 1;
BA_ "GenSigStartValue" SG_ 2582841086 FaultCurrentStatus_27 32000;
BA_ "SPN" SG_ 2582841086 FaultCurrentStatus_27 519054;
BA_ "SigType" SG_ 2582841086 FaultCurrentStatus_27 1;
BA_ "GenSigStartValue" SG_ 2582841086 FaultCurrentStatus_28 32000;
BA_ "SPN" SG_ 2582841086 FaultCurrentStatus_28 519055;
BA_ "SigType" SG_ 2582841086 FaultCurrentStatus_28 1;
BA_ "GenSigStartValue" SG_ 2582841342 FaultCurrentStatus_29 32000;
BA_ "SPN" SG_ 2582841342 FaultCurrentStatus_29 519056;
BA_ "SigType" SG_ 2582841342 FaultCurrentStatus_29 1;
BA_ "GenSigStartValue" SG_ 2582841342 FaultCurrentStatus_30 32000;
BA_ "SPN" SG_ 2582841342 FaultCurrentStatus_30 519057;
BA_ "SigType" SG_ 2582841342 FaultCurrentStatus_30 1;
BA_ "GenSigStartValue" SG_ 2582841342 FaultCurrentStatus_31 32000;
BA_ "SPN" SG_ 2582841342 FaultCurrentStatus_31 519058;
BA_ "SigType" SG_ 2582841342 FaultCurrentStatus_31 1;
BA_ "GenSigStartValue" SG_ 2582841342 FaultCurrentStatus_32 32000;
BA_ "SPN" SG_ 2582841342 FaultCurrentStatus_32 519059;
BA_ "SigType" SG_ 2582841342 FaultCurrentStatus_32 1;
BA_ "GenSigStartValue" SG_ 2582846462 FaultCurrentStatus_01 32000;
BA_ "SPN" SG_ 2582846462 FaultCurrentStatus_01 519028;
BA_ "SigType" SG_ 2582846462 FaultCurrentStatus_01 1;
BA_ "GenSigStartValue" SG_ 2582846462 FaultCurrentStatus_02 32000;
BA_ "SPN" SG_ 2582846462 FaultCurrentStatus_02 519029;
BA_ "SigType" SG_ 2582846462 FaultCurrentStatus_02 1;
BA_ "GenSigStartValue" SG_ 2582846462 FaultCurrentStatus_03 32000;
BA_ "SPN" SG_ 2582846462 FaultCurrentStatus_03 519030;
BA_ "SigType" SG_ 2582846462 FaultCurrentStatus_03 1;
BA_ "GenSigStartValue" SG_ 2582846462 FaultCurrentStatus_04 32000;
BA_ "SPN" SG_ 2582846462 FaultCurrentStatus_04 519031;
BA_ "SigType" SG_ 2582846462 FaultCurrentStatus_04 1;
BA_ "GenSigStartValue" SG_ 2582846462 FaultCurrentStatus_05 32000;
BA_ "SPN" SG_ 2582846462 FaultCurrentStatus_05 519032;
BA_ "SigType" SG_ 2582846462 FaultCurrentStatus_05 1;
BA_ "GenSigStartValue" SG_ 2582846462 FaultCurrentStatus_06 32000;
BA_ "SPN" SG_ 2582846462 FaultCurrentStatus_06 519033;
BA_ "SigType" SG_ 2582846462 FaultCurrentStatus_06 1;
BA_ "GenSigStartValue" SG_ 2582846462 FaultCurrentStatus_07 32000;
BA_ "SPN" SG_ 2582846462 FaultCurrentStatus_07 519034;
BA_ "SigType" SG_ 2582846462 FaultCurrentStatus_07 1;
BA_ "GenSigStartValue" SG_ 2582846462 FaultCurrentStatus_08 32000;
BA_ "SPN" SG_ 2582846462 FaultCurrentStatus_08 519035;
BA_ "SigType" SG_ 2582846462 FaultCurrentStatus_08 1;
BA_ "GenSigStartValue" SG_ 2582846462 FaultCurrentStatus_09 32000;
BA_ "SPN" SG_ 2582846462 FaultCurrentStatus_09 519036;
BA_ "SigType" SG_ 2582846462 FaultCurrentStatus_09 1;
BA_ "GenSigStartValue" SG_ 2582846462 FaultCurrentStatus_10 32000;
BA_ "SPN" SG_ 2582846462 FaultCurrentStatus_10 519037;
BA_ "SigType" SG_ 2582846462 FaultCurrentStatus_10 1;
BA_ "GenSigStartValue" SG_ 2582846462 FaultCurrentStatus_11 32000;
BA_ "SPN" SG_ 2582846462 FaultCurrentStatus_11 519038;
BA_ "SigType" SG_ 2582846462 FaultCurrentStatus_11 1;
BA_ "GenSigStartValue" SG_ 2582846462 FaultCurrentStatus_12 32000;
BA_ "SPN" SG_ 2582846462 FaultCurrentStatus_12 519039;
BA_ "SigType" SG_ 2582846462 FaultCurrentStatus_12 1;
BA_ "GenSigStartValue" SG_ 2582846462 FaultCurrentStatus_13 32000;
BA_ "SPN" SG_ 2582846462 FaultCurrentStatus_13 519040;
BA_ "SigType" SG_ 2582846462 FaultCurrentStatus_13 1;
BA_ "GenSigStartValue" SG_ 2582846462 FaultCurrentStatus_14 32000;
BA_ "SPN" SG_ 2582846462 FaultCurrentStatus_14 519041;
BA_ "SigType" SG_ 2582846462 FaultCurrentStatus_14 1;
BA_ "GenSigStartValue" SG_ 2582846462 FaultCurrentStatus_15 32000;
BA_ "SPN" SG_ 2582846462 FaultCurrentStatus_15 519042;
BA_ "SigType" SG_ 2582846462 FaultCurrentStatus_15 1;
BA_ "GenSigStartValue" SG_ 2582846462 FaultCurrentStatus_16 32000;
BA_ "SPN" SG_ 2582846462 FaultCurrentStatus_16 519043;
BA_ "SigType" SG_ 2582846462 FaultCurrentStatus_16 1;
BA_ "GenSigStartValue" SG_ 2582846462 FaultCurrentStatus_17 32000;
BA_ "SPN" SG_ 2582846462 FaultCurrentStatus_17 519044;
BA_ "SigType" SG_ 2582846462 FaultCurrentStatus_17 1;
BA_ "GenSigStartValue" SG_ 2582846462 FaultCurrentStatus_18 32000;
BA_ "SPN" SG_ 2582846462 FaultCurrentStatus_18 519045;
BA_ "SigType" SG_ 2582846462 FaultCurrentStatus_18 1;
BA_ "GenSigStartValue" SG_ 2582846462 FaultCurrentStatus_19 32000;
BA_ "SPN" SG_ 2582846462 FaultCurrentStatus_19 519046;
BA_ "SigType" SG_ 2582846462 FaultCurrentStatus_19 1;
BA_ "GenSigStartValue" SG_ 2582846462 FaultCurrentStatus_20 32000;
BA_ "SPN" SG_ 2582846462 FaultCurrentStatus_20 519047;
BA_ "SigType" SG_ 2582846462 FaultCurrentStatus_20 1;
BA_ "GenSigStartValue" SG_ 2582846462 FaultCurrentStatus_21 32000;
BA_ "SPN" SG_ 2582846462 FaultCurrentStatus_21 519048;
BA_ "SigType" SG_ 2582846462 FaultCurrentStatus_21 1;
BA_ "GenSigStartValue" SG_ 2582846462 FaultCurrentStatus_22 32000;
BA_ "SPN" SG_ 2582846462 FaultCurrentStatus_22 519049;
BA_ "SigType" SG_ 2582846462 FaultCurrentStatus_22 1;
BA_ "GenSigStartValue" SG_ 2582846462 FaultCurrentStatus_23 32000;
BA_ "SPN" SG_ 2582846462 FaultCurrentStatus_23 519050;
BA_ "SigType" SG_ 2582846462 FaultCurrentStatus_23 1;
BA_ "GenSigStartValue" SG_ 2582846462 FaultCurrentStatus_24 32000;
BA_ "SPN" SG_ 2582846462 FaultCurrentStatus_24 519051;
BA_ "SigType" SG_ 2582846462 FaultCurrentStatus_24 1;
BA_ "GenSigStartValue" SG_ 2582846462 FaultCurrentStatus_25 32000;
BA_ "SPN" SG_ 2582846462 FaultCurrentStatus_25 519052;
BA_ "SigType" SG_ 2582846462 FaultCurrentStatus_25 1;
BA_ "GenSigStartValue" SG_ 2582846462 FaultCurrentStatus_26 32000;
BA_ "SPN" SG_ 2582846462 FaultCurrentStatus_26 519053;
BA_ "SigType" SG_ 2582846462 FaultCurrentStatus_26 1;
BA_ "GenSigStartValue" SG_ 2582846462 FaultCurrentStatus_27 32000;
BA_ "SPN" SG_ 2582846462 FaultCurrentStatus_27 519054;
BA_ "SigType" SG_ 2582846462 FaultCurrentStatus_27 1;
BA_ "GenSigStartValue" SG_ 2582846462 FaultCurrentStatus_28 32000;
BA_ "SPN" SG_ 2582846462 FaultCurrentStatus_28 519055;
BA_ "SigType" SG_ 2582846462 FaultCurrentStatus_28 1;
BA_ "GenSigStartValue" SG_ 2582846462 FaultCurrentStatus_29 32000;
BA_ "SPN" SG_ 2582846462 FaultCurrentStatus_29 519056;
BA_ "SigType" SG_ 2582846462 FaultCurrentStatus_29 1;
BA_ "GenSigStartValue" SG_ 2582846462 FaultCurrentStatus_30 32000;
BA_ "SPN" SG_ 2582846462 FaultCurrentStatus_30 519057;
BA_ "SigType" SG_ 2582846462 FaultCurrentStatus_30 1;
BA_ "GenSigStartValue" SG_ 2582846462 FaultCurrentStatus_31 32000;
BA_ "SPN" SG_ 2582846462 FaultCurrentStatus_31 519058;
BA_ "SigType" SG_ 2582846462 FaultCurrentStatus_31 1;
BA_ "GenSigStartValue" SG_ 2582846462 FaultCurrentStatus_32 32000;
BA_ "SPN" SG_ 2582846462 FaultCurrentStatus_32 519059;
BA_ "SigType" SG_ 2582846462 FaultCurrentStatus_32 1;
BA_ "SPN" SG_ 2582841598 FaultVoltageStatus_01 519060;
BA_ "SigType" SG_ 2582841598 FaultVoltageStatus_01 1;
BA_ "SPN" SG_ 2582841598 FaultVoltageStatus_02 519061;
BA_ "SigType" SG_ 2582841598 FaultVoltageStatus_02 1;
BA_ "SPN" SG_ 2582841598 FaultVoltageStatus_03 519062;
BA_ "SigType" SG_ 2582841598 FaultVoltageStatus_03 1;
BA_ "SPN" SG_ 2582841598 FaultVoltageStatus_04 519063;
BA_ "SigType" SG_ 2582841598 FaultVoltageStatus_04 1;
BA_ "SPN" SG_ 2582841854 FaultVoltageStatus_05 519064;
BA_ "SigType" SG_ 2582841854 FaultVoltageStatus_05 1;
BA_ "SPN" SG_ 2582841854 FaultVoltageStatus_06 519065;
BA_ "SigType" SG_ 2582841854 FaultVoltageStatus_06 1;
BA_ "SPN" SG_ 2582841854 FaultVoltageStatus_07 519066;
BA_ "SigType" SG_ 2582841854 FaultVoltageStatus_07 1;
BA_ "SPN" SG_ 2582841854 FaultVoltageStatus_08 519067;
BA_ "SigType" SG_ 2582841854 FaultVoltageStatus_08 1;
BA_ "SPN" SG_ 2582842110 FaultVoltageStatus_09 519068;
BA_ "SigType" SG_ 2582842110 FaultVoltageStatus_09 1;
BA_ "SPN" SG_ 2582842110 FaultVoltageStatus_10 519069;
BA_ "SigType" SG_ 2582842110 FaultVoltageStatus_10 1;
BA_ "SPN" SG_ 2582842110 FaultVoltageStatus_11 519070;
BA_ "SigType" SG_ 2582842110 FaultVoltageStatus_11 1;
BA_ "SPN" SG_ 2582842110 FaultVoltageStatus_12 519071;
BA_ "SigType" SG_ 2582842110 FaultVoltageStatus_12 1;
BA_ "SPN" SG_ 2582842366 FaultVoltageStatus_13 519072;
BA_ "SigType" SG_ 2582842366 FaultVoltageStatus_13 1;
BA_ "SPN" SG_ 2582842366 FaultVoltageStatus_14 519073;
BA_ "SigType" SG_ 2582842366 FaultVoltageStatus_14 1;
BA_ "SPN" SG_ 2582842366 FaultVoltageStatus_15 519074;
BA_ "SigType" SG_ 2582842366 FaultVoltageStatus_15 1;
BA_ "SPN" SG_ 2582842366 FaultVoltageStatus_16 519075;
BA_ "SigType" SG_ 2582842366 FaultVoltageStatus_16 1;
BA_ "SPN" SG_ 2582842622 FaultVoltageStatus_17 519076;
BA_ "SigType" SG_ 2582842622 FaultVoltageStatus_17 1;
BA_ "SPN" SG_ 2582842622 FaultVoltageStatus_18 519077;
BA_ "SigType" SG_ 2582842622 FaultVoltageStatus_18 1;
BA_ "SPN" SG_ 2582842622 FaultVoltageStatus_19 519078;
BA_ "SigType" SG_ 2582842622 FaultVoltageStatus_19 1;
BA_ "SPN" SG_ 2582842622 FaultVoltageStatus_20 519079;
BA_ "SigType" SG_ 2582842622 FaultVoltageStatus_20 1;
BA_ "SPN" SG_ 2582842878 FaultVoltageStatus_21 519080;
BA_ "SigType" SG_ 2582842878 FaultVoltageStatus_21 1;
BA_ "SPN" SG_ 2582842878 FaultVoltageStatus_22 519081;
BA_ "SigType" SG_ 2582842878 FaultVoltageStatus_22 1;
BA_ "SPN" SG_ 2582842878 FaultVoltageStatus_23 519082;
BA_ "SigType" SG_ 2582842878 FaultVoltageStatus_23 1;
BA_ "SPN" SG_ 2582842878 FaultVoltageStatus_24 519083;
BA_ "SigType" SG_ 2582842878 FaultVoltageStatus_24 1;
BA_ "SPN" SG_ 2582843134 FaultVoltageStatus_25 519084;
BA_ "SigType" SG_ 2582843134 FaultVoltageStatus_25 1;
BA_ "SPN" SG_ 2582843134 FaultVoltageStatus_26 519085;
BA_ "SigType" SG_ 2582843134 FaultVoltageStatus_26 1;
BA_ "SPN" SG_ 2582843134 FaultVoltageStatus_27 519086;
BA_ "SigType" SG_ 2582843134 FaultVoltageStatus_27 1;
BA_ "SPN" SG_ 2582843134 FaultVoltageStatus_28 519087;
BA_ "SigType" SG_ 2582843134 FaultVoltageStatus_28 1;
BA_ "SPN" SG_ 2582843390 FaultVoltageStatus_29 519088;
BA_ "SigType" SG_ 2582843390 FaultVoltageStatus_29 1;
BA_ "SPN" SG_ 2582843390 FaultVoltageStatus_30 519089;
BA_ "SigType" SG_ 2582843390 FaultVoltageStatus_30 1;
BA_ "SPN" SG_ 2582843390 FaultVoltageStatus_31 519090;
BA_ "SigType" SG_ 2582843390 FaultVoltageStatus_31 1;
BA_ "SPN" SG_ 2582843390 FaultVoltageStatus_32 519091;
BA_ "SigType" SG_ 2582843390 FaultVoltageStatus_32 1;
BA_ "SPN" SG_ 2582846718 FaultVoltageStatus_01 519060;
BA_ "SigType" SG_ 2582846718 FaultVoltageStatus_01 1;
BA_ "SPN" SG_ 2582846718 FaultVoltageStatus_02 519061;
BA_ "SigType" SG_ 2582846718 FaultVoltageStatus_02 1;
BA_ "SPN" SG_ 2582846718 FaultVoltageStatus_03 519062;
BA_ "SigType" SG_ 2582846718 FaultVoltageStatus_03 1;
BA_ "SPN" SG_ 2582846718 FaultVoltageStatus_04 519063;
BA_ "SigType" SG_ 2582846718 FaultVoltageStatus_04 1;
BA_ "SPN" SG_ 2582846718 FaultVoltageStatus_05 519064;
BA_ "SigType" SG_ 2582846718 FaultVoltageStatus_05 1;
BA_ "SPN" SG_ 2582846718 FaultVoltageStatus_06 519065;
BA_ "SigType" SG_ 2582846718 FaultVoltageStatus_06 1;
BA_ "SPN" SG_ 2582846718 FaultVoltageStatus_07 519066;
BA_ "SigType" SG_ 2582846718 FaultVoltageStatus_07 1;
BA_ "SPN" SG_ 2582846718 FaultVoltageStatus_08 519067;
BA_ "SigType" SG_ 2582846718 FaultVoltageStatus_08 1;
BA_ "SPN" SG_ 2582846718 FaultVoltageStatus_09 519068;
BA_ "SigType" SG_ 2582846718 FaultVoltageStatus_09 1;
BA_ "SPN" SG_ 2582846718 FaultVoltageStatus_10 519069;
BA_ "SigType" SG_ 2582846718 FaultVoltageStatus_10 1;
BA_ "SPN" SG_ 2582846718 FaultVoltageStatus_11 519070;
BA_ "SigType" SG_ 2582846718 FaultVoltageStatus_11 1;
BA_ "SPN" SG_ 2582846718 FaultVoltageStatus_12 519071;
BA_ "SigType" SG_ 2582846718 FaultVoltageStatus_12 1;
BA_ "SPN" SG_ 2582846718 FaultVoltageStatus_13 519072;
BA_ "SigType" SG_ 2582846718 FaultVoltageStatus_13 1;
BA_ "SPN" SG_ 2582846718 FaultVoltageStatus_14 519073;
BA_ "SigType" SG_ 2582846718 FaultVoltageStatus_14 1;
BA_ "SPN" SG_ 2582846718 FaultVoltageStatus_15 519074;
BA_ "SigType" SG_ 2582846718 FaultVoltageStatus_15 1;
BA_ "SPN" SG_ 2582846718 FaultVoltageStatus_16 519075;
BA_ "SigType" SG_ 2582846718 FaultVoltageStatus_16 1;
BA_ "SPN" SG_ 2582846718 FaultVoltageStatus_17 519076;
BA_ "SigType" SG_ 2582846718 FaultVoltageStatus_17 1;
BA_ "SPN" SG_ 2582846718 FaultVoltageStatus_18 519077;
BA_ "SigType" SG_ 2582846718 FaultVoltageStatus_18 1;
BA_ "SPN" SG_ 2582846718 FaultVoltageStatus_19 519078;
BA_ "SigType" SG_ 2582846718 FaultVoltageStatus_19 1;
BA_ "SPN" SG_ 2582846718 FaultVoltageStatus_20 519079;
BA_ "SigType" SG_ 2582846718 FaultVoltageStatus_20 1;
BA_ "SPN" SG_ 2582846718 FaultVoltageStatus_21 519080;
BA_ "SigType" SG_ 2582846718 FaultVoltageStatus_21 1;
BA_ "SPN" SG_ 2582846718 FaultVoltageStatus_22 519081;
BA_ "SigType" SG_ 2582846718 FaultVoltageStatus_22 1;
BA_ "SPN" SG_ 2582846718 FaultVoltageStatus_23 519082;
BA_ "SigType" SG_ 2582846718 FaultVoltageStatus_23 1;
BA_ "SPN" SG_ 2582846718 FaultVoltageStatus_24 519083;
BA_ "SigType" SG_ 2582846718 FaultVoltageStatus_24 1;
BA_ "SPN" SG_ 2582846718 FaultVoltageStatus_25 519084;
BA_ "SigType" SG_ 2582846718 FaultVoltageStatus_25 1;
BA_ "SPN" SG_ 2582846718 FaultVoltageStatus_26 519085;
BA_ "SigType" SG_ 2582846718 FaultVoltageStatus_26 1;
BA_ "SPN" SG_ 2582846718 FaultVoltageStatus_27 519086;
BA_ "SigType" SG_ 2582846718 FaultVoltageStatus_27 1;
BA_ "SPN" SG_ 2582846718 FaultVoltageStatus_28 519087;
BA_ "SigType" SG_ 2582846718 FaultVoltageStatus_28 1;
BA_ "SPN" SG_ 2582846718 FaultVoltageStatus_29 519088;
BA_ "SigType" SG_ 2582846718 FaultVoltageStatus_29 1;
BA_ "SPN" SG_ 2582846718 FaultVoltageStatus_30 519089;
BA_ "SigType" SG_ 2582846718 FaultVoltageStatus_30 1;
BA_ "SPN" SG_ 2582846718 FaultVoltageStatus_31 519090;
BA_ "SigType" SG_ 2582846718 FaultVoltageStatus_31 1;
BA_ "SPN" SG_ 2582846718 FaultVoltageStatus_32 519091;
BA_ "SigType" SG_ 2582846718 FaultVoltageStatus_32 1;
BA_ "SPN" SG_ 2583650046 VoltageStatus_01 519092;
BA_ "SigType" SG_ 2583650046 VoltageStatus_01 1;
BA_ "SPN" SG_ 2583650046 VoltageStatus_02 519093;
BA_ "SigType" SG_ 2583650046 VoltageStatus_02 1;
BA_ "SPN" SG_ 2583650046 VoltageStatus_03 519094;
BA_ "SigType" SG_ 2583650046 VoltageStatus_03 1;
BA_ "SPN" SG_ 2583650046 VoltageStatus_04 519095;
BA_ "SigType" SG_ 2583650046 VoltageStatus_04 1;
BA_ "SPN" SG_ 2583650302 VoltageStatus_05 519096;
BA_ "SigType" SG_ 2583650302 VoltageStatus_05 1;
BA_ "SPN" SG_ 2583650302 VoltageStatus_06 519097;
BA_ "SigType" SG_ 2583650302 VoltageStatus_06 1;
BA_ "SPN" SG_ 2583650302 VoltageStatus_07 519098;
BA_ "SigType" SG_ 2583650302 VoltageStatus_07 1;
BA_ "SPN" SG_ 2583650302 VoltageStatus_08 519099;
BA_ "SigType" SG_ 2583650302 VoltageStatus_08 1;
BA_ "SPN" SG_ 2583650558 VoltageStatus_09 519100;
BA_ "SigType" SG_ 2583650558 VoltageStatus_09 1;
BA_ "SPN" SG_ 2583650558 VoltageStatus_10 519101;
BA_ "SigType" SG_ 2583650558 VoltageStatus_10 1;
BA_ "SPN" SG_ 2583650558 VoltageStatus_11 519102;
BA_ "SigType" SG_ 2583650558 VoltageStatus_11 1;
BA_ "SPN" SG_ 2583650558 VoltageStatus_12 519103;
BA_ "SigType" SG_ 2583650558 VoltageStatus_12 1;
BA_ "SPN" SG_ 2583650814 VoltageStatus_13 519104;
BA_ "SigType" SG_ 2583650814 VoltageStatus_13 1;
BA_ "SPN" SG_ 2583650814 VoltageStatus_14 519105;
BA_ "SigType" SG_ 2583650814 VoltageStatus_14 1;
BA_ "SPN" SG_ 2583650814 VoltageStatus_15 519106;
BA_ "SigType" SG_ 2583650814 VoltageStatus_15 1;
BA_ "SPN" SG_ 2583650814 VoltageStatus_16 519107;
BA_ "SigType" SG_ 2583650814 VoltageStatus_16 1;
BA_ "SPN" SG_ 2583651070 VoltageStatus_17 519108;
BA_ "SigType" SG_ 2583651070 VoltageStatus_17 1;
BA_ "SPN" SG_ 2583651070 VoltageStatus_18 519109;
BA_ "SigType" SG_ 2583651070 VoltageStatus_18 1;
BA_ "SPN" SG_ 2583651070 VoltageStatus_19 519110;
BA_ "SigType" SG_ 2583651070 VoltageStatus_19 1;
BA_ "SPN" SG_ 2583651070 VoltageStatus_20 519111;
BA_ "SigType" SG_ 2583651070 VoltageStatus_20 1;
BA_ "SPN" SG_ 2583654398 VoltageStatus_21 519112;
BA_ "SigType" SG_ 2583654398 VoltageStatus_21 1;
BA_ "SPN" SG_ 2583654398 VoltageStatus_22 519113;
BA_ "SigType" SG_ 2583654398 VoltageStatus_22 1;
BA_ "SPN" SG_ 2583654398 VoltageStatus_23 519114;
BA_ "SigType" SG_ 2583654398 VoltageStatus_23 1;
BA_ "SPN" SG_ 2583654398 VoltageStatus_24 519115;
BA_ "SigType" SG_ 2583654398 VoltageStatus_24 1;
BA_ "SPN" SG_ 2583654654 VoltageStatus_25 519116;
BA_ "SigType" SG_ 2583654654 VoltageStatus_25 1;
BA_ "SPN" SG_ 2583654654 VoltageStatus_26 519117;
BA_ "SigType" SG_ 2583654654 VoltageStatus_26 1;
BA_ "SPN" SG_ 2583654654 VoltageStatus_27 519118;
BA_ "SigType" SG_ 2583654654 VoltageStatus_27 1;
BA_ "SPN" SG_ 2583654654 VoltageStatus_28 519119;
BA_ "SigType" SG_ 2583654654 VoltageStatus_28 1;
BA_ "SPN" SG_ 2583654910 VoltageStatus_29 519120;
BA_ "SigType" SG_ 2583654910 VoltageStatus_29 1;
BA_ "SPN" SG_ 2583654910 VoltageStatus_30 519121;
BA_ "SigType" SG_ 2583654910 VoltageStatus_30 1;
BA_ "SPN" SG_ 2583654910 VoltageStatus_31 519122;
BA_ "SigType" SG_ 2583654910 VoltageStatus_31 1;
BA_ "SPN" SG_ 2583654910 VoltageStatus_32 519123;
BA_ "SigType" SG_ 2583654910 VoltageStatus_32 1;
BA_ "SPN" SG_ 2582845694 VoltageStatus_01 519092;
BA_ "SigType" SG_ 2582845694 VoltageStatus_01 1;
BA_ "SPN" SG_ 2582845694 VoltageStatus_02 519093;
BA_ "SigType" SG_ 2582845694 VoltageStatus_02 1;
BA_ "SPN" SG_ 2582845694 VoltageStatus_03 519094;
BA_ "SigType" SG_ 2582845694 VoltageStatus_03 1;
BA_ "SPN" SG_ 2582845694 VoltageStatus_04 519095;
BA_ "SigType" SG_ 2582845694 VoltageStatus_04 1;
BA_ "SPN" SG_ 2582845694 VoltageStatus_05 519096;
BA_ "SigType" SG_ 2582845694 VoltageStatus_05 1;
BA_ "SPN" SG_ 2582845694 VoltageStatus_06 519097;
BA_ "SigType" SG_ 2582845694 VoltageStatus_06 1;
BA_ "SPN" SG_ 2582845694 VoltageStatus_07 519098;
BA_ "SigType" SG_ 2582845694 VoltageStatus_07 1;
BA_ "SPN" SG_ 2582845694 VoltageStatus_08 519099;
BA_ "SigType" SG_ 2582845694 VoltageStatus_08 1;
BA_ "SPN" SG_ 2582845694 VoltageStatus_09 519100;
BA_ "SigType" SG_ 2582845694 VoltageStatus_09 1;
BA_ "SPN" SG_ 2582845694 VoltageStatus_10 519101;
BA_ "SigType" SG_ 2582845694 VoltageStatus_10 1;
BA_ "SPN" SG_ 2582845694 VoltageStatus_11 519102;
BA_ "SigType" SG_ 2582845694 VoltageStatus_11 1;
BA_ "SPN" SG_ 2582845694 VoltageStatus_12 519103;
BA_ "SigType" SG_ 2582845694 VoltageStatus_12 1;
BA_ "SPN" SG_ 2582845694 VoltageStatus_13 519104;
BA_ "SigType" SG_ 2582845694 VoltageStatus_13 1;
BA_ "SPN" SG_ 2582845694 VoltageStatus_14 519105;
BA_ "SigType" SG_ 2582845694 VoltageStatus_14 1;
BA_ "SPN" SG_ 2582845694 VoltageStatus_15 519106;
BA_ "SigType" SG_ 2582845694 VoltageStatus_15 1;
BA_ "SPN" SG_ 2582845694 VoltageStatus_16 519107;
BA_ "SigType" SG_ 2582845694 VoltageStatus_16 1;
BA_ "SPN" SG_ 2582845694 VoltageStatus_17 519108;
BA_ "SigType" SG_ 2582845694 VoltageStatus_17 1;
BA_ "SPN" SG_ 2582845694 VoltageStatus_18 519109;
BA_ "SigType" SG_ 2582845694 VoltageStatus_18 1;
BA_ "SPN" SG_ 2582845694 VoltageStatus_19 519110;
BA_ "SigType" SG_ 2582845694 VoltageStatus_19 1;
BA_ "SPN" SG_ 2582845694 VoltageStatus_20 519111;
BA_ "SigType" SG_ 2582845694 VoltageStatus_20 1;
BA_ "SPN" SG_ 2582845694 VoltageStatus_21 519112;
BA_ "SigType" SG_ 2582845694 VoltageStatus_21 1;
BA_ "SPN" SG_ 2582845694 VoltageStatus_22 519113;
BA_ "SigType" SG_ 2582845694 VoltageStatus_22 1;
BA_ "SPN" SG_ 2582845694 VoltageStatus_23 519114;
BA_ "SigType" SG_ 2582845694 VoltageStatus_23 1;
BA_ "SPN" SG_ 2582845694 VoltageStatus_24 519115;
BA_ "SigType" SG_ 2582845694 VoltageStatus_24 1;
BA_ "SPN" SG_ 2582845694 VoltageStatus_25 519116;
BA_ "SigType" SG_ 2582845694 VoltageStatus_25 1;
BA_ "SPN" SG_ 2582845694 VoltageStatus_26 519117;
BA_ "SigType" SG_ 2582845694 VoltageStatus_26 1;
BA_ "SPN" SG_ 2582845694 VoltageStatus_27 519118;
BA_ "SigType" SG_ 2582845694 VoltageStatus_27 1;
BA_ "SPN" SG_ 2582845694 VoltageStatus_28 519119;
BA_ "SigType" SG_ 2582845694 VoltageStatus_28 1;
BA_ "SPN" SG_ 2582845694 VoltageStatus_29 519120;
BA_ "SigType" SG_ 2582845694 VoltageStatus_29 1;
BA_ "SPN" SG_ 2582845694 VoltageStatus_30 519121;
BA_ "SigType" SG_ 2582845694 VoltageStatus_30 1;
BA_ "SPN" SG_ 2582845694 VoltageStatus_31 519122;
BA_ "SigType" SG_ 2582845694 VoltageStatus_31 1;
BA_ "SPN" SG_ 2582845694 VoltageStatus_32 519123;
BA_ "SigType" SG_ 2582845694 VoltageStatus_32 1;
BA_ "SPN" SG_ 2583646718 PinModeStatus_01 519124;
BA_ "SPN" SG_ 2583646718 PinPullModeStatus_01 519125;
BA_ "SPN" SG_ 2583646718 LoadDetectionStatus_01 519126;
BA_ "SPN" SG_ 2583646718 PinModeStatus_02 519127;
BA_ "SPN" SG_ 2583646718 PinPullModeStatus_02 519128;
BA_ "SPN" SG_ 2583646718 LoadDetectionStatus_02 519129;
BA_ "SPN" SG_ 2583646718 PinModeStatus_03 519130;
BA_ "SPN" SG_ 2583646718 PinPullModeStatus_03 519131;
BA_ "SPN" SG_ 2583646718 LoadDetectionStatus_03 519132;
BA_ "SPN" SG_ 2583646718 PinModeStatus_04 519133;
BA_ "SPN" SG_ 2583646718 PinPullModeStatus_04 519134;
BA_ "SPN" SG_ 2583646718 LoadDetectionStatus_04 519135;
BA_ "SPN" SG_ 2583646718 PinModeStatus_05 519136;
BA_ "SPN" SG_ 2583646718 PinPullModeStatus_05 519137;
BA_ "SPN" SG_ 2583646718 LoadDetectionStatus_05 519138;
BA_ "SPN" SG_ 2583646718 PinModeStatus_06 519139;
BA_ "SPN" SG_ 2583646718 PinPullModeStatus_06 519140;
BA_ "SPN" SG_ 2583646718 LoadDetectionStatus_06 519141;
BA_ "SPN" SG_ 2583646718 PinModeStatus_07 519142;
BA_ "SPN" SG_ 2583646718 PinPullModeStatus_07 519143;
BA_ "SPN" SG_ 2583646718 LoadDetectionStatus_07 519144;
BA_ "SPN" SG_ 2583646718 PinModeStatus_08 519145;
BA_ "SPN" SG_ 2583646718 PinPullModeStatus_08 519146;
BA_ "SPN" SG_ 2583646718 LoadDetectionStatus_08 519147;
BA_ "SPN" SG_ 2583646974 PinModeStatus_09 519148;
BA_ "SPN" SG_ 2583646974 PinPullModeStatus_09 519149;
BA_ "SPN" SG_ 2583646974 LoadDetectionStatus_09 519150;
BA_ "SPN" SG_ 2583646974 PinModeStatus_10 519151;
BA_ "SPN" SG_ 2583646974 PinPullModeStatus_10 519152;
BA_ "SPN" SG_ 2583646974 LoadDetectionStatus_10 519153;
BA_ "SPN" SG_ 2583646974 PinModeStatus_11 519154;
BA_ "SPN" SG_ 2583646974 PinPullModeStatus_11 519155;
BA_ "SPN" SG_ 2583646974 LoadDetectionStatus_11 519156;
BA_ "SPN" SG_ 2583646974 PinModeStatus_12 519157;
BA_ "SPN" SG_ 2583646974 PinPullModeStatus_12 519158;
BA_ "SPN" SG_ 2583646974 LoadDetectionStatus_12 519159;
BA_ "SPN" SG_ 2583646974 PinModeStatus_13 519160;
BA_ "SPN" SG_ 2583646974 PinPullModeStatus_13 519161;
BA_ "SPN" SG_ 2583646974 LoadDetectionStatus_13 519162;
BA_ "SPN" SG_ 2583646974 PinModeStatus_14 519163;
BA_ "SPN" SG_ 2583646974 PinPullModeStatus_14 519164;
BA_ "SPN" SG_ 2583646974 LoadDetectionStatus_14 519165;
BA_ "SPN" SG_ 2583646974 PinModeStatus_15 519166;
BA_ "SPN" SG_ 2583646974 PinPullModeStatus_15 519167;
BA_ "SPN" SG_ 2583646974 LoadDetectionStatus_15 519168;
BA_ "SPN" SG_ 2583646974 PinModeStatus_16 519169;
BA_ "SPN" SG_ 2583646974 PinPullModeStatus_16 519170;
BA_ "SPN" SG_ 2583646974 LoadDetectionStatus_16 519171;
BA_ "SPN" SG_ 2583647230 PinModeStatus_17 519172;
BA_ "SPN" SG_ 2583647230 PinPullModeStatus_17 519173;
BA_ "SPN" SG_ 2583647230 LoadDetectionStatus_17 519174;
BA_ "SPN" SG_ 2583647230 PinModeStatus_18 519175;
BA_ "SPN" SG_ 2583647230 PinPullModeStatus_18 519176;
BA_ "SPN" SG_ 2583647230 LoadDetectionStatus_18 519177;
BA_ "SPN" SG_ 2583647230 PinModeStatus_19 519178;
BA_ "SPN" SG_ 2583647230 PinPullModeStatus_19 519179;
BA_ "SPN" SG_ 2583647230 LoadDetectionStatus_19 519180;
BA_ "SPN" SG_ 2583647230 PinModeStatus_20 519181;
BA_ "SPN" SG_ 2583647230 PinPullModeStatus_20 519182;
BA_ "SPN" SG_ 2583647230 LoadDetectionStatus_20 519183;
BA_ "SPN" SG_ 2583647230 PinModeStatus_21 519184;
BA_ "SPN" SG_ 2583647230 PinPullModeStatus_21 519185;
BA_ "SPN" SG_ 2583647230 LoadDetectionStatus_21 519186;
BA_ "SPN" SG_ 2583647230 PinModeStatus_22 519187;
BA_ "SPN" SG_ 2583647230 PinPullModeStatus_22 519188;
BA_ "SPN" SG_ 2583647230 LoadDetectionStatus_22 519189;
BA_ "SPN" SG_ 2583647230 PinModeStatus_23 519190;
BA_ "SPN" SG_ 2583647230 PinPullModeStatus_23 519191;
BA_ "SPN" SG_ 2583647230 LoadDetectionStatus_23 519192;
BA_ "SPN" SG_ 2583647230 PinModeStatus_24 519193;
BA_ "SPN" SG_ 2583647230 PinPullModeStatus_24 519194;
BA_ "SPN" SG_ 2583647230 LoadDetectionStatus_24 519195;
BA_ "SPN" SG_ 2583647486 PinModeStatus_25 519196;
BA_ "SPN" SG_ 2583647486 PinPullModeStatus_25 519197;
BA_ "SPN" SG_ 2583647486 LoadDetectionStatus_25 519198;
BA_ "SPN" SG_ 2583647486 PinModeStatus_26 519199;
BA_ "SPN" SG_ 2583647486 PinPullModeStatus_26 519200;
BA_ "SPN" SG_ 2583647486 LoadDetectionStatus_26 519201;
BA_ "SPN" SG_ 2583647486 PinModeStatus_27 519202;
BA_ "SPN" SG_ 2583647486 PinPullModeStatus_27 519203;
BA_ "SPN" SG_ 2583647486 LoadDetectionStatus_27 519204;
BA_ "SPN" SG_ 2583647486 PinModeStatus_28 519205;
BA_ "SPN" SG_ 2583647486 PinPullModeStatus_28 519206;
BA_ "SPN" SG_ 2583647486 LoadDetectionStatus_28 519207;
BA_ "SPN" SG_ 2583647486 PinModeStatus_29 519208;
BA_ "SPN" SG_ 2583647486 PinPullModeStatus_29 519209;
BA_ "SPN" SG_ 2583647486 LoadDetectionStatus_29 519210;
BA_ "SPN" SG_ 2583647486 PinModeStatus_30 519211;
BA_ "SPN" SG_ 2583647486 PinPullModeStatus_30 519212;
BA_ "SPN" SG_ 2583647486 LoadDetectionStatus_30 519213;
BA_ "SPN" SG_ 2583647486 PinModeStatus_31 519214;
BA_ "SPN" SG_ 2583647486 PinPullModeStatus_31 519215;
BA_ "SPN" SG_ 2583647486 LoadDetectionStatus_31 519216;
BA_ "SPN" SG_ 2583647486 PinModeStatus_32 519217;
BA_ "SPN" SG_ 2583647486 PinPullModeStatus_32 519218;
BA_ "SPN" SG_ 2583647486 LoadDetectionStatus_32 519219;
BA_ "SPN" SG_ 2582846974 PinModeStatus_01 519124;
BA_ "SPN" SG_ 2582846974 PinPullModeStatus_01 519125;
BA_ "SPN" SG_ 2582846974 LoadDetectionStatus_01 519126;
BA_ "SPN" SG_ 2582846974 PinModeStatus_02 519127;
BA_ "SPN" SG_ 2582846974 PinPullModeStatus_02 519128;
BA_ "SPN" SG_ 2582846974 LoadDetectionStatus_02 519129;
BA_ "SPN" SG_ 2582846974 PinModeStatus_03 519130;
BA_ "SPN" SG_ 2582846974 PinPullModeStatus_03 519131;
BA_ "SPN" SG_ 2582846974 LoadDetectionStatus_03 519132;
BA_ "SPN" SG_ 2582846974 PinModeStatus_04 519133;
BA_ "SPN" SG_ 2582846974 PinPullModeStatus_04 519134;
BA_ "SPN" SG_ 2582846974 LoadDetectionStatus_04 519135;
BA_ "SPN" SG_ 2582846974 PinModeStatus_05 519136;
BA_ "SPN" SG_ 2582846974 PinPullModeStatus_05 519137;
BA_ "SPN" SG_ 2582846974 LoadDetectionStatus_05 519138;
BA_ "SPN" SG_ 2582846974 PinModeStatus_06 519139;
BA_ "SPN" SG_ 2582846974 PinPullModeStatus_06 519140;
BA_ "SPN" SG_ 2582846974 LoadDetectionStatus_06 519141;
BA_ "SPN" SG_ 2582846974 PinModeStatus_07 519142;
BA_ "SPN" SG_ 2582846974 PinPullModeStatus_07 519143;
BA_ "SPN" SG_ 2582846974 LoadDetectionStatus_07 519144;
BA_ "SPN" SG_ 2582846974 PinModeStatus_08 519145;
BA_ "SPN" SG_ 2582846974 PinPullModeStatus_08 519146;
BA_ "SPN" SG_ 2582846974 LoadDetectionStatus_08 519147;
BA_ "SPN" SG_ 2582846974 PinModeStatus_09 519148;
BA_ "SPN" SG_ 2582846974 PinPullModeStatus_09 519149;
BA_ "SPN" SG_ 2582846974 LoadDetectionStatus_09 519150;
BA_ "SPN" SG_ 2582846974 PinModeStatus_10 519151;
BA_ "SPN" SG_ 2582846974 PinPullModeStatus_10 519152;
BA_ "SPN" SG_ 2582846974 LoadDetectionStatus_10 519153;
BA_ "SPN" SG_ 2582846974 PinModeStatus_11 519154;
BA_ "SPN" SG_ 2582846974 PinPullModeStatus_11 519155;
BA_ "SPN" SG_ 2582846974 LoadDetectionStatus_11 519156;
BA_ "SPN" SG_ 2582846974 PinModeStatus_12 519157;
BA_ "SPN" SG_ 2582846974 PinPullModeStatus_12 519158;
BA_ "SPN" SG_ 2582846974 LoadDetectionStatus_12 519159;
BA_ "SPN" SG_ 2582846974 PinModeStatus_13 519160;
BA_ "SPN" SG_ 2582846974 PinPullModeStatus_13 519161;
BA_ "SPN" SG_ 2582846974 LoadDetectionStatus_13 519162;
BA_ "SPN" SG_ 2582846974 PinModeStatus_14 519163;
BA_ "SPN" SG_ 2582846974 PinPullModeStatus_14 519164;
BA_ "SPN" SG_ 2582846974 LoadDetectionStatus_14 519165;
BA_ "SPN" SG_ 2582846974 PinModeStatus_15 519166;
BA_ "SPN" SG_ 2582846974 PinPullModeStatus_15 519167;
BA_ "SPN" SG_ 2582846974 LoadDetectionStatus_15 519168;
BA_ "SPN" SG_ 2582846974 PinModeStatus_16 519169;
BA_ "SPN" SG_ 2582846974 PinPullModeStatus_16 519170;
BA_ "SPN" SG_ 2582846974 LoadDetectionStatus_16 519171;
BA_ "SPN" SG_ 2582846974 PinModeStatus_17 519172;
BA_ "SPN" SG_ 2582846974 PinPullModeStatus_17 519173;
BA_ "SPN" SG_ 2582846974 LoadDetectionStatus_17 519174;
BA_ "SPN" SG_ 2582846974 PinModeStatus_18 519175;
BA_ "SPN" SG_ 2582846974 PinPullModeStatus_18 519176;
BA_ "SPN" SG_ 2582846974 LoadDetectionStatus_18 519177;
BA_ "SPN" SG_ 2582846974 PinModeStatus_19 519178;
BA_ "SPN" SG_ 2582846974 PinPullModeStatus_19 519179;
BA_ "SPN" SG_ 2582846974 LoadDetectionStatus_19 519180;
BA_ "SPN" SG_ 2582846974 PinModeStatus_20 519181;
BA_ "SPN" SG_ 2582846974 PinPullModeStatus_20 519182;
BA_ "SPN" SG_ 2582846974 LoadDetectionStatus_20 519183;
BA_ "SPN" SG_ 2582846974 PinModeStatus_21 519184;
BA_ "SPN" SG_ 2582846974 PinPullModeStatus_21 519185;
BA_ "SPN" SG_ 2582846974 LoadDetectionStatus_21 519186;
BA_ "SPN" SG_ 2582846974 PinModeStatus_22 519187;
BA_ "SPN" SG_ 2582846974 PinPullModeStatus_22 519188;
BA_ "SPN" SG_ 2582846974 LoadDetectionStatus_22 519189;
BA_ "SPN" SG_ 2582846974 PinModeStatus_23 519190;
BA_ "SPN" SG_ 2582846974 PinPullModeStatus_23 519191;
BA_ "SPN" SG_ 2582846974 LoadDetectionStatus_23 519192;
BA_ "SPN" SG_ 2582846974 PinModeStatus_24 519193;
BA_ "SPN" SG_ 2582846974 PinPullModeStatus_24 519194;
BA_ "SPN" SG_ 2582846974 LoadDetectionStatus_24 519195;
BA_ "SPN" SG_ 2582846974 PinModeStatus_25 519196;
BA_ "SPN" SG_ 2582846974 PinPullModeStatus_25 519197;
BA_ "SPN" SG_ 2582846974 LoadDetectionStatus_25 519198;
BA_ "SPN" SG_ 2582846974 PinModeStatus_26 519199;
BA_ "SPN" SG_ 2582846974 PinPullModeStatus_26 519200;
BA_ "SPN" SG_ 2582846974 LoadDetectionStatus_26 519201;
BA_ "SPN" SG_ 2582846974 PinModeStatus_27 519202;
BA_ "SPN" SG_ 2582846974 PinPullModeStatus_27 519203;
BA_ "SPN" SG_ 2582846974 LoadDetectionStatus_27 519204;
BA_ "SPN" SG_ 2582846974 PinModeStatus_28 519205;
BA_ "SPN" SG_ 2582846974 PinPullModeStatus_28 519206;
BA_ "SPN" SG_ 2582846974 LoadDetectionStatus_28 519207;
BA_ "SPN" SG_ 2582846974 PinModeStatus_29 519208;
BA_ "SPN" SG_ 2582846974 PinPullModeStatus_29 519209;
BA_ "SPN" SG_ 2582846974 LoadDetectionStatus_29 519210;
BA_ "SPN" SG_ 2582846974 PinModeStatus_30 519211;
BA_ "SPN" SG_ 2582846974 PinPullModeStatus_30 519212;
BA_ "SPN" SG_ 2582846974 LoadDetectionStatus_30 519213;
BA_ "SPN" SG_ 2582846974 PinModeStatus_31 519214;
BA_ "SPN" SG_ 2582846974 PinPullModeStatus_31 519215;
BA_ "SPN" SG_ 2582846974 LoadDetectionStatus_31 519216;
BA_ "SPN" SG_ 2582846974 PinModeStatus_32 519217;
BA_ "SPN" SG_ 2582846974 PinPullModeStatus_32 519218;
BA_ "SPN" SG_ 2582846974 LoadDetectionStatus_32 519219;
BA_ "SPN" SG_ 2650761214 PwmFrequencyStatus_01 519220;
BA_ "SigType" SG_ 2650761214 PwmFrequencyStatus_01 1;
BA_ "SPN" SG_ 2650761214 PwmFrequencyStatus_02 519221;
BA_ "SigType" SG_ 2650761214 PwmFrequencyStatus_02 1;
BA_ "SPN" SG_ 2650761214 PwmFrequencyStatus_03 519222;
BA_ "SigType" SG_ 2650761214 PwmFrequencyStatus_03 1;
BA_ "SPN" SG_ 2650761214 PwmFrequencyStatus_04 519223;
BA_ "SigType" SG_ 2650761214 PwmFrequencyStatus_04 1;
BA_ "SPN" SG_ 2650761470 PwmFrequencyStatus_05 519224;
BA_ "SigType" SG_ 2650761470 PwmFrequencyStatus_05 1;
BA_ "SPN" SG_ 2650761470 PwmFrequencyStatus_06 519225;
BA_ "SigType" SG_ 2650761470 PwmFrequencyStatus_06 1;
BA_ "SPN" SG_ 2650761470 PwmFrequencyStatus_07 519226;
BA_ "SigType" SG_ 2650761470 PwmFrequencyStatus_07 1;
BA_ "SPN" SG_ 2650761470 PwmFrequencyStatus_08 519227;
BA_ "SigType" SG_ 2650761470 PwmFrequencyStatus_08 1;
BA_ "SPN" SG_ 2650761726 PwmFrequencyStatus_09 519228;
BA_ "SigType" SG_ 2650761726 PwmFrequencyStatus_09 1;
BA_ "SPN" SG_ 2650761726 PwmFrequencyStatus_10 519229;
BA_ "SigType" SG_ 2650761726 PwmFrequencyStatus_10 1;
BA_ "SPN" SG_ 2650761726 PwmFrequencyStatus_11 519230;
BA_ "SigType" SG_ 2650761726 PwmFrequencyStatus_11 1;
BA_ "SPN" SG_ 2650761726 PwmFrequencyStatus_12 519231;
BA_ "SigType" SG_ 2650761726 PwmFrequencyStatus_12 1;
BA_ "SPN" SG_ 2650761982 PwmFrequencyStatus_13 519232;
BA_ "SigType" SG_ 2650761982 PwmFrequencyStatus_13 1;
BA_ "SPN" SG_ 2650761982 PwmFrequencyStatus_14 519233;
BA_ "SigType" SG_ 2650761982 PwmFrequencyStatus_14 1;
BA_ "SPN" SG_ 2650761982 PwmFrequencyStatus_15 519234;
BA_ "SigType" SG_ 2650761982 PwmFrequencyStatus_15 1;
BA_ "SPN" SG_ 2650761982 PwmFrequencyStatus_16 519235;
BA_ "SigType" SG_ 2650761982 PwmFrequencyStatus_16 1;
BA_ "SPN" SG_ 2650762238 PwmFrequencyStatus_17 519236;
BA_ "SigType" SG_ 2650762238 PwmFrequencyStatus_17 1;
BA_ "SPN" SG_ 2650762238 PwmFrequencyStatus_18 519237;
BA_ "SigType" SG_ 2650762238 PwmFrequencyStatus_18 1;
BA_ "SPN" SG_ 2650762238 PwmFrequencyStatus_19 519238;
BA_ "SigType" SG_ 2650762238 PwmFrequencyStatus_19 1;
BA_ "SPN" SG_ 2650762238 PwmFrequencyStatus_20 519239;
BA_ "SigType" SG_ 2650762238 PwmFrequencyStatus_20 1;
BA_ "SPN" SG_ 2650762494 PwmFrequencyStatus_21 519240;
BA_ "SigType" SG_ 2650762494 PwmFrequencyStatus_21 1;
BA_ "SPN" SG_ 2650762494 PwmFrequencyStatus_22 519241;
BA_ "SigType" SG_ 2650762494 PwmFrequencyStatus_22 1;
BA_ "SPN" SG_ 2650762494 PwmFrequencyStatus_23 519242;
BA_ "SigType" SG_ 2650762494 PwmFrequencyStatus_23 1;
BA_ "SPN" SG_ 2650762494 PwmFrequencyStatus_24 519243;
BA_ "SigType" SG_ 2650762494 PwmFrequencyStatus_24 1;
BA_ "SPN" SG_ 2650762750 PwmFrequencyStatus_25 519244;
BA_ "SigType" SG_ 2650762750 PwmFrequencyStatus_25 1;
BA_ "SPN" SG_ 2650762750 PwmFrequencyStatus_26 519245;
BA_ "SigType" SG_ 2650762750 PwmFrequencyStatus_26 1;
BA_ "SPN" SG_ 2650762750 PwmFrequencyStatus_27 519246;
BA_ "SigType" SG_ 2650762750 PwmFrequencyStatus_27 1;
BA_ "SPN" SG_ 2650762750 PwmFrequencyStatus_28 519247;
BA_ "SigType" SG_ 2650762750 PwmFrequencyStatus_28 1;
BA_ "SPN" SG_ 2650763006 PwmFrequencyStatus_29 519248;
BA_ "SigType" SG_ 2650763006 PwmFrequencyStatus_29 1;
BA_ "SPN" SG_ 2650763006 PwmFrequencyStatus_30 519249;
BA_ "SigType" SG_ 2650763006 PwmFrequencyStatus_30 1;
BA_ "SPN" SG_ 2650763006 PwmFrequencyStatus_31 519250;
BA_ "SigType" SG_ 2650763006 PwmFrequencyStatus_31 1;
BA_ "SPN" SG_ 2650763006 PwmFrequencyStatus_32 519251;
BA_ "SigType" SG_ 2650763006 PwmFrequencyStatus_32 1;
BA_ "SPN" SG_ 2649956094 PwmFrequencyStatus_01 519220;
BA_ "SigType" SG_ 2649956094 PwmFrequencyStatus_01 1;
BA_ "SPN" SG_ 2649956094 PwmFrequencyStatus_02 519221;
BA_ "SigType" SG_ 2649956094 PwmFrequencyStatus_02 1;
BA_ "SPN" SG_ 2649956094 PwmFrequencyStatus_03 519222;
BA_ "SigType" SG_ 2649956094 PwmFrequencyStatus_03 1;
BA_ "SPN" SG_ 2649956094 PwmFrequencyStatus_04 519223;
BA_ "SigType" SG_ 2649956094 PwmFrequencyStatus_04 1;
BA_ "SPN" SG_ 2649956094 PwmFrequencyStatus_05 519224;
BA_ "SigType" SG_ 2649956094 PwmFrequencyStatus_05 1;
BA_ "SPN" SG_ 2649956094 PwmFrequencyStatus_06 519225;
BA_ "SigType" SG_ 2649956094 PwmFrequencyStatus_06 1;
BA_ "SPN" SG_ 2649956094 PwmFrequencyStatus_07 519226;
BA_ "SigType" SG_ 2649956094 PwmFrequencyStatus_07 1;
BA_ "SPN" SG_ 2649956094 PwmFrequencyStatus_08 519227;
BA_ "SigType" SG_ 2649956094 PwmFrequencyStatus_08 1;
BA_ "SPN" SG_ 2649956094 PwmFrequencyStatus_09 519228;
BA_ "SigType" SG_ 2649956094 PwmFrequencyStatus_09 1;
BA_ "SPN" SG_ 2649956094 PwmFrequencyStatus_10 519229;
BA_ "SigType" SG_ 2649956094 PwmFrequencyStatus_10 1;
BA_ "SPN" SG_ 2649956094 PwmFrequencyStatus_11 519230;
BA_ "SigType" SG_ 2649956094 PwmFrequencyStatus_11 1;
BA_ "SPN" SG_ 2649956094 PwmFrequencyStatus_12 519231;
BA_ "SigType" SG_ 2649956094 PwmFrequencyStatus_12 1;
BA_ "SPN" SG_ 2649956094 PwmFrequencyStatus_13 519232;
BA_ "SigType" SG_ 2649956094 PwmFrequencyStatus_13 1;
BA_ "SPN" SG_ 2649956094 PwmFrequencyStatus_14 519233;
BA_ "SigType" SG_ 2649956094 PwmFrequencyStatus_14 1;
BA_ "SPN" SG_ 2649956094 PwmFrequencyStatus_15 519234;
BA_ "SigType" SG_ 2649956094 PwmFrequencyStatus_15 1;
BA_ "SPN" SG_ 2649956094 PwmFrequencyStatus_16 519235;
BA_ "SigType" SG_ 2649956094 PwmFrequencyStatus_16 1;
BA_ "SPN" SG_ 2649956094 PwmFrequencyStatus_17 519236;
BA_ "SigType" SG_ 2649956094 PwmFrequencyStatus_17 1;
BA_ "SPN" SG_ 2649956094 PwmFrequencyStatus_18 519237;
BA_ "SigType" SG_ 2649956094 PwmFrequencyStatus_18 1;
BA_ "SPN" SG_ 2649956094 PwmFrequencyStatus_19 519238;
BA_ "SigType" SG_ 2649956094 PwmFrequencyStatus_19 1;
BA_ "SPN" SG_ 2649956094 PwmFrequencyStatus_20 519239;
BA_ "SigType" SG_ 2649956094 PwmFrequencyStatus_20 1;
BA_ "SPN" SG_ 2649956094 PwmFrequencyStatus_21 519240;
BA_ "SigType" SG_ 2649956094 PwmFrequencyStatus_21 1;
BA_ "SPN" SG_ 2649956094 PwmFrequencyStatus_22 519241;
BA_ "SigType" SG_ 2649956094 PwmFrequencyStatus_22 1;
BA_ "SPN" SG_ 2649956094 PwmFrequencyStatus_23 519242;
BA_ "SigType" SG_ 2649956094 PwmFrequencyStatus_23 1;
BA_ "SPN" SG_ 2649956094 PwmFrequencyStatus_24 519243;
BA_ "SigType" SG_ 2649956094 PwmFrequencyStatus_24 1;
BA_ "SPN" SG_ 2649956094 PwmFrequencyStatus_25 519244;
BA_ "SigType" SG_ 2649956094 PwmFrequencyStatus_25 1;
BA_ "SPN" SG_ 2649956094 PwmFrequencyStatus_26 519245;
BA_ "SigType" SG_ 2649956094 PwmFrequencyStatus_26 1;
BA_ "SPN" SG_ 2649956094 PwmFrequencyStatus_27 519246;
BA_ "SigType" SG_ 2649956094 PwmFrequencyStatus_27 1;
BA_ "SPN" SG_ 2649956094 PwmFrequencyStatus_28 519247;
BA_ "SigType" SG_ 2649956094 PwmFrequencyStatus_28 1;
BA_ "SPN" SG_ 2649956094 PwmFrequencyStatus_29 519248;
BA_ "SigType" SG_ 2649956094 PwmFrequencyStatus_29 1;
BA_ "SPN" SG_ 2649956094 PwmFrequencyStatus_30 519249;
BA_ "SigType" SG_ 2649956094 PwmFrequencyStatus_30 1;
BA_ "SPN" SG_ 2649956094 PwmFrequencyStatus_31 519250;
BA_ "SigType" SG_ 2649956094 PwmFrequencyStatus_31 1;
BA_ "SPN" SG_ 2649956094 PwmFrequencyStatus_32 519251;
BA_ "SigType" SG_ 2649956094 PwmFrequencyStatus_32 1;
BA_ "SPN" SG_ 2582847998 QEncoderDirection_Q01 519260;
BA_ "GenSigStartValue" SG_ 2582847998 QEncoderCounter_Q01 8000000;
BA_ "SPN" SG_ 2582847998 QEncoderCounter_Q01 519261;
BA_ "SigType" SG_ 2582847998 QEncoderCounter_Q01 1;
BA_ "GenSigStartValue" SG_ 2583649790 TemperatureStatus_t01 40;
BA_ "SPN" SG_ 2583649790 TemperatureStatus_t01 519252;
BA_ "SigType" SG_ 2583649790 TemperatureStatus_t01 1;
BA_ "GenSigStartValue" SG_ 2583649790 TemperatureStatus_t02 40;
BA_ "SPN" SG_ 2583649790 TemperatureStatus_t02 519253;
BA_ "SigType" SG_ 2583649790 TemperatureStatus_t02 1;
BA_ "GenSigStartValue" SG_ 2583649790 TemperatureStatus_t03 40;
BA_ "SPN" SG_ 2583649790 TemperatureStatus_t03 519254;
BA_ "SigType" SG_ 2583649790 TemperatureStatus_t03 1;
BA_ "GenSigStartValue" SG_ 2583649790 TemperatureStatus_t04 40;
BA_ "SPN" SG_ 2583649790 TemperatureStatus_t04 519255;
BA_ "SigType" SG_ 2583649790 TemperatureStatus_t04 1;
BA_ "GenSigStartValue" SG_ 2583649790 TemperatureStatus_t05 40;
BA_ "SPN" SG_ 2583649790 TemperatureStatus_t05 519256;
BA_ "SigType" SG_ 2583649790 TemperatureStatus_t05 1;
BA_ "GenSigStartValue" SG_ 2583649790 TemperatureStatus_t06 40;
BA_ "SPN" SG_ 2583649790 TemperatureStatus_t06 519257;
BA_ "SigType" SG_ 2583649790 TemperatureStatus_t06 1;
BA_ "GenSigStartValue" SG_ 2583649790 TemperatureStatus_t07 40;
BA_ "SPN" SG_ 2583649790 TemperatureStatus_t07 519258;
BA_ "SigType" SG_ 2583649790 TemperatureStatus_t07 1;
BA_ "GenSigStartValue" SG_ 2583649790 TemperatureStatus_t08 40;
BA_ "SPN" SG_ 2583649790 TemperatureStatus_t08 519259;
BA_ "SigType" SG_ 2583649790 TemperatureStatus_t08 1;
VAL_ 2583646718 PinModeStatus_01 0 "Disabled" 1 "VREF" 2 "HighSide" 3 "LowSide" 4 "InputOnly" 5 "Bridge" 14 "Error" 15 "Not Available" ;
VAL_ 2583646718 PinPullModeStatus_01 0 "None" 1 "PullDown" 2 "PullUp" 3 "Not Available" ;
VAL_ 2583646718 LoadDetectionStatus_01 0 "Off" 1 "On" 2 "Error" 3 "Not Available" ;
VAL_ 2583646718 PinModeStatus_02 0 "Disabled" 1 "VREF" 2 "HighSide" 3 "LowSide" 4 "InputOnly" 5 "Bridge" 14 "Error" 15 "Not Available" ;
VAL_ 2583646718 PinPullModeStatus_02 0 "None" 1 "PullDown" 2 "PullUp" 3 "Not Available" ;
VAL_ 2583646718 LoadDetectionStatus_02 0 "Off" 1 "On" 2 "Error" 3 "Not Available" ;
VAL_ 2583646718 PinModeStatus_03 0 "Disabled" 1 "VREF" 2 "HighSide" 3 "LowSide" 4 "InputOnly" 5 "Bridge" 14 "Error" 15 "Not Available" ;
VAL_ 2583646718 PinPullModeStatus_03 0 "None" 1 "PullDown" 2 "PullUp" 3 "Not Available" ;
VAL_ 2583646718 LoadDetectionStatus_03 0 "Off" 1 "On" 2 "Error" 3 "Not Available" ;
VAL_ 2583646718 PinModeStatus_04 0 "Disabled" 1 "VREF" 2 "HighSide" 3 "LowSide" 4 "InputOnly" 5 "Bridge" 14 "Error" 15 "Not Available" ;
VAL_ 2583646718 PinPullModeStatus_04 0 "None" 1 "PullDown" 2 "PullUp" 3 "Not Available" ;
VAL_ 2583646718 LoadDetectionStatus_04 0 "Off" 1 "On" 2 "Error" 3 "Not Available" ;
VAL_ 2583646718 PinModeStatus_05 0 "Disabled" 1 "VREF" 2 "HighSide" 3 "LowSide" 4 "InputOnly" 5 "Bridge" 14 "Error" 15 "Not Available" ;
VAL_ 2583646718 PinPullModeStatus_05 0 "None" 1 "PullDown" 2 "PullUp" 3 "Not Available" ;
VAL_ 2583646718 LoadDetectionStatus_05 0 "Off" 1 "On" 2 "Error" 3 "Not Available" ;
VAL_ 2583646718 PinModeStatus_06 0 "Disabled" 1 "VREF" 2 "HighSide" 3 "LowSide" 4 "InputOnly" 5 "Bridge" 14 "Error" 15 "Not Available" ;
VAL_ 2583646718 PinPullModeStatus_06 0 "None" 1 "PullDown" 2 "PullUp" 3 "Not Available" ;
VAL_ 2583646718 LoadDetectionStatus_06 0 "Off" 1 "On" 2 "Error" 3 "Not Available" ;
VAL_ 2583646718 PinModeStatus_07 0 "Disabled" 1 "VREF" 2 "HighSide" 3 "LowSide" 4 "InputOnly" 5 "Bridge" 14 "Error" 15 "Not Available" ;
VAL_ 2583646718 PinPullModeStatus_07 0 "None" 1 "PullDown" 2 "PullUp" 3 "Not Available" ;
VAL_ 2583646718 LoadDetectionStatus_07 0 "Off" 1 "On" 2 "Error" 3 "Not Available" ;
VAL_ 2583646718 PinModeStatus_08 0 "Disabled" 1 "VREF" 2 "HighSide" 3 "LowSide" 4 "InputOnly" 5 "Bridge" 14 "Error" 15 "Not Available" ;
VAL_ 2583646718 PinPullModeStatus_08 0 "None" 1 "PullDown" 2 "PullUp" 3 "Not Available" ;
VAL_ 2583646718 LoadDetectionStatus_08 0 "Off" 1 "On" 2 "Error" 3 "Not Available" ;
VAL_ 2583646974 PinModeStatus_09 0 "Disabled" 1 "VREF" 2 "HighSide" 3 "LowSide" 4 "InputOnly" 5 "Bridge" 14 "Error" 15 "Not Available" ;
VAL_ 2583646974 PinPullModeStatus_09 0 "None" 1 "PullDown" 2 "PullUp" 3 "Not Available" ;
VAL_ 2583646974 LoadDetectionStatus_09 0 "Off" 1 "On" 2 "Error" 3 "Not Available" ;
VAL_ 2583646974 PinModeStatus_10 0 "Disabled" 1 "VREF" 2 "HighSide" 3 "LowSide" 4 "InputOnly" 5 "Bridge" 14 "Error" 15 "Not Available" ;
VAL_ 2583646974 PinPullModeStatus_10 0 "None" 1 "PullDown" 2 "PullUp" 3 "Not Available" ;
VAL_ 2583646974 LoadDetectionStatus_10 0 "Off" 1 "On" 2 "Error" 3 "Not Available" ;
VAL_ 2583646974 PinModeStatus_11 0 "Disabled" 1 "VREF" 2 "HighSide" 3 "LowSide" 4 "InputOnly" 5 "Bridge" 14 "Error" 15 "Not Available" ;
VAL_ 2583646974 PinPullModeStatus_11 0 "None" 1 "PullDown" 2 "PullUp" 3 "Not Available" ;
VAL_ 2583646974 LoadDetectionStatus_11 0 "Off" 1 "On" 2 "Error" 3 "Not Available" ;
VAL_ 2583646974 PinModeStatus_12 0 "Disabled" 1 "VREF" 2 "HighSide" 3 "LowSide" 4 "InputOnly" 5 "Bridge" 14 "Error" 15 "Not Available" ;
VAL_ 2583646974 PinPullModeStatus_12 0 "None" 1 "PullDown" 2 "PullUp" 3 "Not Available" ;
VAL_ 2583646974 LoadDetectionStatus_12 0 "Off" 1 "On" 2 "Error" 3 "Not Available" ;
VAL_ 2583646974 PinModeStatus_13 0 "Disabled" 1 "VREF" 2 "HighSide" 3 "LowSide" 4 "InputOnly" 5 "Bridge" 14 "Error" 15 "Not Available" ;
VAL_ 2583646974 PinPullModeStatus_13 0 "None" 1 "PullDown" 2 "PullUp" 3 "Not Available" ;
VAL_ 2583646974 LoadDetectionStatus_13 0 "Off" 1 "On" 2 "Error" 3 "Not Available" ;
VAL_ 2583646974 PinModeStatus_14 0 "Disabled" 1 "VREF" 2 "HighSide" 3 "LowSide" 4 "InputOnly" 5 "Bridge" 14 "Error" 15 "Not Available" ;
VAL_ 2583646974 PinPullModeStatus_14 0 "None" 1 "PullDown" 2 "PullUp" 3 "Not Available" ;
VAL_ 2583646974 LoadDetectionStatus_14 0 "Off" 1 "On" 2 "Error" 3 "Not Available" ;
VAL_ 2583646974 PinModeStatus_15 0 "Disabled" 1 "VREF" 2 "HighSide" 3 "LowSide" 4 "InputOnly" 5 "Bridge" 14 "Error" 15 "Not Available" ;
VAL_ 2583646974 PinPullModeStatus_15 0 "None" 1 "PullDown" 2 "PullUp" 3 "Not Available" ;
VAL_ 2583646974 LoadDetectionStatus_15 0 "Off" 1 "On" 2 "Error" 3 "Not Available" ;
VAL_ 2583646974 PinModeStatus_16 0 "Disabled" 1 "VREF" 2 "HighSide" 3 "LowSide" 4 "InputOnly" 5 "Bridge" 14 "Error" 15 "Not Available" ;
VAL_ 2583646974 PinPullModeStatus_16 0 "None" 1 "PullDown" 2 "PullUp" 3 "Not Available" ;
VAL_ 2583646974 LoadDetectionStatus_16 0 "Off" 1 "On" 2 "Error" 3 "Not Available" ;
VAL_ 2583647230 PinModeStatus_17 0 "Disabled" 1 "VREF" 2 "HighSide" 3 "LowSide" 4 "InputOnly" 5 "Bridge" 14 "Error" 15 "Not Available" ;
VAL_ 2583647230 PinPullModeStatus_17 0 "None" 1 "PullDown" 2 "PullUp" 3 "Not Available" ;
VAL_ 2583647230 LoadDetectionStatus_17 0 "Off" 1 "On" 2 "Error" 3 "Not Available" ;
VAL_ 2583647230 PinModeStatus_18 0 "Disabled" 1 "VREF" 2 "HighSide" 3 "LowSide" 4 "InputOnly" 5 "Bridge" 14 "Error" 15 "Not Available" ;
VAL_ 2583647230 PinPullModeStatus_18 0 "None" 1 "PullDown" 2 "PullUp" 3 "Not Available" ;
VAL_ 2583647230 LoadDetectionStatus_18 0 "Off" 1 "On" 2 "Error" 3 "Not Available" ;
VAL_ 2583647230 PinModeStatus_19 0 "Disabled" 1 "VREF" 2 "HighSide" 3 "LowSide" 4 "InputOnly" 5 "Bridge" 14 "Error" 15 "Not Available" ;
VAL_ 2583647230 PinPullModeStatus_19 0 "None" 1 "PullDown" 2 "PullUp" 3 "Not Available" ;
VAL_ 2583647230 LoadDetectionStatus_19 0 "Off" 1 "On" 2 "Error" 3 "Not Available" ;
VAL_ 2583647230 PinModeStatus_20 0 "Disabled" 1 "VREF" 2 "HighSide" 3 "LowSide" 4 "InputOnly" 5 "Bridge" 14 "Error" 15 "Not Available" ;
VAL_ 2583647230 PinPullModeStatus_20 0 "None" 1 "PullDown" 2 "PullUp" 3 "Not Available" ;
VAL_ 2583647230 LoadDetectionStatus_20 0 "Off" 1 "On" 2 "Error" 3 "Not Available" ;
VAL_ 2583647230 PinModeStatus_21 0 "Disabled" 1 "VREF" 2 "HighSide" 3 "LowSide" 4 "InputOnly" 5 "Bridge" 14 "Error" 15 "Not Available" ;
VAL_ 2583647230 PinPullModeStatus_21 0 "None" 1 "PullDown" 2 "PullUp" 3 "Not Available" ;
VAL_ 2583647230 LoadDetectionStatus_21 0 "Off" 1 "On" 2 "Error" 3 "Not Available" ;
VAL_ 2583647230 PinModeStatus_22 0 "Disabled" 1 "VREF" 2 "HighSide" 3 "LowSide" 4 "InputOnly" 5 "Bridge" 14 "Error" 15 "Not Available" ;
VAL_ 2583647230 PinPullModeStatus_22 0 "None" 1 "PullDown" 2 "PullUp" 3 "Not Available" ;
VAL_ 2583647230 LoadDetectionStatus_22 0 "Off" 1 "On" 2 "Error" 3 "Not Available" ;
VAL_ 2583647230 PinModeStatus_23 0 "Disabled" 1 "VREF" 2 "HighSide" 3 "LowSide" 4 "InputOnly" 5 "Bridge" 14 "Error" 15 "Not Available" ;
VAL_ 2583647230 PinPullModeStatus_23 0 "None" 1 "PullDown" 2 "PullUp" 3 "Not Available" ;
VAL_ 2583647230 LoadDetectionStatus_23 0 "Off" 1 "On" 2 "Error" 3 "Not Available" ;
VAL_ 2583647230 PinModeStatus_24 0 "Disabled" 1 "VREF" 2 "HighSide" 3 "LowSide" 4 "InputOnly" 5 "Bridge" 14 "Error" 15 "Not Available" ;
VAL_ 2583647230 PinPullModeStatus_24 0 "None" 1 "PullDown" 2 "PullUp" 3 "Not Available" ;
VAL_ 2583647230 LoadDetectionStatus_24 0 "Off" 1 "On" 2 "Error" 3 "Not Available" ;
VAL_ 2583647486 PinModeStatus_25 0 "Disabled" 1 "VREF" 2 "HighSide" 3 "LowSide" 4 "InputOnly" 5 "Bridge" 14 "Error" 15 "Not Available" ;
VAL_ 2583647486 PinPullModeStatus_25 0 "None" 1 "PullDown" 2 "PullUp" 3 "Not Available" ;
VAL_ 2583647486 LoadDetectionStatus_25 0 "Off" 1 "On" 2 "Error" 3 "Not Available" ;
VAL_ 2583647486 PinModeStatus_26 0 "Disabled" 1 "VREF" 2 "HighSide" 3 "LowSide" 4 "InputOnly" 5 "Bridge" 14 "Error" 15 "Not Available" ;
VAL_ 2583647486 PinPullModeStatus_26 0 "None" 1 "PullDown" 2 "PullUp" 3 "Not Available" ;
VAL_ 2583647486 LoadDetectionStatus_26 0 "Off" 1 "On" 2 "Error" 3 "Not Available" ;
VAL_ 2583647486 PinModeStatus_27 0 "Disabled" 1 "VREF" 2 "HighSide" 3 "LowSide" 4 "InputOnly" 5 "Bridge" 14 "Error" 15 "Not Available" ;
VAL_ 2583647486 PinPullModeStatus_27 0 "None" 1 "PullDown" 2 "PullUp" 3 "Not Available" ;
VAL_ 2583647486 LoadDetectionStatus_27 0 "Off" 1 "On" 2 "Error" 3 "Not Available" ;
VAL_ 2583647486 PinModeStatus_28 0 "Disabled" 1 "VREF" 2 "HighSide" 3 "LowSide" 4 "InputOnly" 5 "Bridge" 14 "Error" 15 "Not Available" ;
VAL_ 2583647486 PinPullModeStatus_28 0 "None" 1 "PullDown" 2 "PullUp" 3 "Not Available" ;
VAL_ 2583647486 LoadDetectionStatus_28 0 "Off" 1 "On" 2 "Error" 3 "Not Available" ;
VAL_ 2583647486 PinModeStatus_29 0 "Disabled" 1 "VREF" 2 "HighSide" 3 "LowSide" 4 "InputOnly" 5 "Bridge" 14 "Error" 15 "Not Available" ;
VAL_ 2583647486 PinPullModeStatus_29 0 "None" 1 "PullDown" 2 "PullUp" 3 "Not Available" ;
VAL_ 2583647486 LoadDetectionStatus_29 0 "Off" 1 "On" 2 "Error" 3 "Not Available" ;
VAL_ 2583647486 PinModeStatus_30 0 "Disabled" 1 "VREF" 2 "HighSide" 3 "LowSide" 4 "InputOnly" 5 "Bridge" 14 "Error" 15 "Not Available" ;
VAL_ 2583647486 PinPullModeStatus_30 0 "None" 1 "PullDown" 2 "PullUp" 3 "Not Available" ;
VAL_ 2583647486 LoadDetectionStatus_30 0 "Off" 1 "On" 2 "Error" 3 "Not Available" ;
VAL_ 2583647486 PinModeStatus_31 0 "Disabled" 1 "VREF" 2 "HighSide" 3 "LowSide" 4 "InputOnly" 5 "Bridge" 14 "Error" 15 "Not Available" ;
VAL_ 2583647486 PinPullModeStatus_31 0 "None" 1 "PullDown" 2 "PullUp" 3 "Not Available" ;
VAL_ 2583647486 LoadDetectionStatus_31 0 "Off" 1 "On" 2 "Error" 3 "Not Available" ;
VAL_ 2583647486 PinModeStatus_32 0 "Disabled" 1 "VREF" 2 "HighSide" 3 "LowSide" 4 "InputOnly" 5 "Bridge" 14 "Error" 15 "Not Available" ;
VAL_ 2583647486 PinPullModeStatus_32 0 "None" 1 "PullDown" 2 "PullUp" 3 "Not Available" ;
VAL_ 2583647486 LoadDetectionStatus_32 0 "Off" 1 "On" 2 "Error" 3 "Not Available" ;
VAL_ 2582846974 PinModeStatus_01 0 "Disabled" 1 "VREF" 2 "HighSide" 3 "LowSide" 4 "InputOnly" 5 "Bridge" 14 "Error" 15 "Not Available" ;
VAL_ 2582846974 PinPullModeStatus_01 0 "None" 1 "PullDown" 2 "PullUp" 3 "Not Available" ;
VAL_ 2582846974 LoadDetectionStatus_01 0 "Off" 1 "On" 2 "Error" 3 "Not Available" ;
VAL_ 2582846974 PinModeStatus_02 0 "Disabled" 1 "VREF" 2 "HighSide" 3 "LowSide" 4 "InputOnly" 5 "Bridge" 14 "Error" 15 "Not Available" ;
VAL_ 2582846974 PinPullModeStatus_02 0 "None" 1 "PullDown" 2 "PullUp" 3 "Not Available" ;
VAL_ 2582846974 LoadDetectionStatus_02 0 "Off" 1 "On" 2 "Error" 3 "Not Available" ;
VAL_ 2582846974 PinModeStatus_03 0 "Disabled" 1 "VREF" 2 "HighSide" 3 "LowSide" 4 "InputOnly" 5 "Bridge" 14 "Error" 15 "Not Available" ;
VAL_ 2582846974 PinPullModeStatus_03 0 "None" 1 "PullDown" 2 "PullUp" 3 "Not Available" ;
VAL_ 2582846974 LoadDetectionStatus_03 0 "Off" 1 "On" 2 "Error" 3 "Not Available" ;
VAL_ 2582846974 PinModeStatus_04 0 "Disabled" 1 "VREF" 2 "HighSide" 3 "LowSide" 4 "InputOnly" 5 "Bridge" 14 "Error" 15 "Not Available" ;
VAL_ 2582846974 PinPullModeStatus_04 0 "None" 1 "PullDown" 2 "PullUp" 3 "Not Available" ;
VAL_ 2582846974 LoadDetectionStatus_04 0 "Off" 1 "On" 2 "Error" 3 "Not Available" ;
VAL_ 2582846974 PinModeStatus_05 0 "Disabled" 1 "VREF" 2 "HighSide" 3 "LowSide" 4 "InputOnly" 5 "Bridge" 14 "Error" 15 "Not Available" ;
VAL_ 2582846974 PinPullModeStatus_05 0 "None" 1 "PullDown" 2 "PullUp" 3 "Not Available" ;
VAL_ 2582846974 LoadDetectionStatus_05 0 "Off" 1 "On" 2 "Error" 3 "Not Available" ;
VAL_ 2582846974 PinModeStatus_06 0 "Disabled" 1 "VREF" 2 "HighSide" 3 "LowSide" 4 "InputOnly" 5 "Bridge" 14 "Error" 15 "Not Available" ;
VAL_ 2582846974 PinPullModeStatus_06 0 "None" 1 "PullDown" 2 "PullUp" 3 "Not Available" ;
VAL_ 2582846974 LoadDetectionStatus_06 0 "Off" 1 "On" 2 "Error" 3 "Not Available" ;
VAL_ 2582846974 PinModeStatus_07 0 "Disabled" 1 "VREF" 2 "HighSide" 3 "LowSide" 4 "InputOnly" 5 "Bridge" 14 "Error" 15 "Not Available" ;
VAL_ 2582846974 PinPullModeStatus_07 0 "None" 1 "PullDown" 2 "PullUp" 3 "Not Available" ;
VAL_ 2582846974 LoadDetectionStatus_07 0 "Off" 1 "On" 2 "Error" 3 "Not Available" ;
VAL_ 2582846974 PinModeStatus_08 0 "Disabled" 1 "VREF" 2 "HighSide" 3 "LowSide" 4 "InputOnly" 5 "Bridge" 14 "Error" 15 "Not Available" ;
VAL_ 2582846974 PinPullModeStatus_08 0 "None" 1 "PullDown" 2 "PullUp" 3 "Not Available" ;
VAL_ 2582846974 LoadDetectionStatus_08 0 "Off" 1 "On" 2 "Error" 3 "Not Available" ;
VAL_ 2582846974 PinModeStatus_09 0 "Disabled" 1 "VREF" 2 "HighSide" 3 "LowSide" 4 "InputOnly" 5 "Bridge" 14 "Error" 15 "Not Available" ;
VAL_ 2582846974 PinPullModeStatus_09 0 "None" 1 "PullDown" 2 "PullUp" 3 "Not Available" ;
VAL_ 2582846974 LoadDetectionStatus_09 0 "Off" 1 "On" 2 "Error" 3 "Not Available" ;
VAL_ 2582846974 PinModeStatus_10 0 "Disabled" 1 "VREF" 2 "HighSide" 3 "LowSide" 4 "InputOnly" 5 "Bridge" 14 "Error" 15 "Not Available" ;
VAL_ 2582846974 PinPullModeStatus_10 0 "None" 1 "PullDown" 2 "PullUp" 3 "Not Available" ;
VAL_ 2582846974 LoadDetectionStatus_10 0 "Off" 1 "On" 2 "Error" 3 "Not Available" ;
VAL_ 2582846974 PinModeStatus_11 0 "Disabled" 1 "VREF" 2 "HighSide" 3 "LowSide" 4 "InputOnly" 5 "Bridge" 14 "Error" 15 "Not Available" ;
VAL_ 2582846974 PinPullModeStatus_11 0 "None" 1 "PullDown" 2 "PullUp" 3 "Not Available" ;
VAL_ 2582846974 LoadDetectionStatus_11 0 "Off" 1 "On" 2 "Error" 3 "Not Available" ;
VAL_ 2582846974 PinModeStatus_12 0 "Disabled" 1 "VREF" 2 "HighSide" 3 "LowSide" 4 "InputOnly" 5 "Bridge" 14 "Error" 15 "Not Available" ;
VAL_ 2582846974 PinPullModeStatus_12 0 "None" 1 "PullDown" 2 "PullUp" 3 "Not Available" ;
VAL_ 2582846974 LoadDetectionStatus_12 0 "Off" 1 "On" 2 "Error" 3 "Not Available" ;
VAL_ 2582846974 PinModeStatus_13 0 "Disabled" 1 "VREF" 2 "HighSide" 3 "LowSide" 4 "InputOnly" 5 "Bridge" 14 "Error" 15 "Not Available" ;
VAL_ 2582846974 PinPullModeStatus_13 0 "None" 1 "PullDown" 2 "PullUp" 3 "Not Available" ;
VAL_ 2582846974 LoadDetectionStatus_13 0 "Off" 1 "On" 2 "Error" 3 "Not Available" ;
VAL_ 2582846974 PinModeStatus_14 0 "Disabled" 1 "VREF" 2 "HighSide" 3 "LowSide" 4 "InputOnly" 5 "Bridge" 14 "Error" 15 "Not Available" ;
VAL_ 2582846974 PinPullModeStatus_14 0 "None" 1 "PullDown" 2 "PullUp" 3 "Not Available" ;
VAL_ 2582846974 LoadDetectionStatus_14 0 "Off" 1 "On" 2 "Error" 3 "Not Available" ;
VAL_ 2582846974 PinModeStatus_15 0 "Disabled" 1 "VREF" 2 "HighSide" 3 "LowSide" 4 "InputOnly" 5 "Bridge" 14 "Error" 15 "Not Available" ;
VAL_ 2582846974 PinPullModeStatus_15 0 "None" 1 "PullDown" 2 "PullUp" 3 "Not Available" ;
VAL_ 2582846974 LoadDetectionStatus_15 0 "Off" 1 "On" 2 "Error" 3 "Not Available" ;
VAL_ 2582846974 PinModeStatus_16 0 "Disabled" 1 "VREF" 2 "HighSide" 3 "LowSide" 4 "InputOnly" 5 "Bridge" 14 "Error" 15 "Not Available" ;
VAL_ 2582846974 PinPullModeStatus_16 0 "None" 1 "PullDown" 2 "PullUp" 3 "Not Available" ;
VAL_ 2582846974 LoadDetectionStatus_16 0 "Off" 1 "On" 2 "Error" 3 "Not Available" ;
VAL_ 2582846974 PinModeStatus_17 0 "Disabled" 1 "VREF" 2 "HighSide" 3 "LowSide" 4 "InputOnly" 5 "Bridge" 14 "Error" 15 "Not Available" ;
VAL_ 2582846974 PinPullModeStatus_17 0 "None" 1 "PullDown" 2 "PullUp" 3 "Not Available" ;
VAL_ 2582846974 LoadDetectionStatus_17 0 "Off" 1 "On" 2 "Error" 3 "Not Available" ;
VAL_ 2582846974 PinModeStatus_18 0 "Disabled" 1 "VREF" 2 "HighSide" 3 "LowSide" 4 "InputOnly" 5 "Bridge" 14 "Error" 15 "Not Available" ;
VAL_ 2582846974 PinPullModeStatus_18 0 "None" 1 "PullDown" 2 "PullUp" 3 "Not Available" ;
VAL_ 2582846974 LoadDetectionStatus_18 0 "Off" 1 "On" 2 "Error" 3 "Not Available" ;
VAL_ 2582846974 PinModeStatus_19 0 "Disabled" 1 "VREF" 2 "HighSide" 3 "LowSide" 4 "InputOnly" 5 "Bridge" 14 "Error" 15 "Not Available" ;
VAL_ 2582846974 PinPullModeStatus_19 0 "None" 1 "PullDown" 2 "PullUp" 3 "Not Available" ;
VAL_ 2582846974 LoadDetectionStatus_19 0 "Off" 1 "On" 2 "Error" 3 "Not Available" ;
VAL_ 2582846974 PinModeStatus_20 0 "Disabled" 1 "VREF" 2 "HighSide" 3 "LowSide" 4 "InputOnly" 5 "Bridge" 14 "Error" 15 "Not Available" ;
VAL_ 2582846974 PinPullModeStatus_20 0 "None" 1 "PullDown" 2 "PullUp" 3 "Not Available" ;
VAL_ 2582846974 LoadDetectionStatus_20 0 "Off" 1 "On" 2 "Error" 3 "Not Available" ;
VAL_ 2582846974 PinModeStatus_21 0 "Disabled" 1 "VREF" 2 "HighSide" 3 "LowSide" 4 "InputOnly" 5 "Bridge" 14 "Error" 15 "Not Available" ;
VAL_ 2582846974 PinPullModeStatus_21 0 "None" 1 "PullDown" 2 "PullUp" 3 "Not Available" ;
VAL_ 2582846974 LoadDetectionStatus_21 0 "Off" 1 "On" 2 "Error" 3 "Not Available" ;
VAL_ 2582846974 PinModeStatus_22 0 "Disabled" 1 "VREF" 2 "HighSide" 3 "LowSide" 4 "InputOnly" 5 "Bridge" 14 "Error" 15 "Not Available" ;
VAL_ 2582846974 PinPullModeStatus_22 0 "None" 1 "PullDown" 2 "PullUp" 3 "Not Available" ;
VAL_ 2582846974 LoadDetectionStatus_22 0 "Off" 1 "On" 2 "Error" 3 "Not Available" ;
VAL_ 2582846974 PinModeStatus_23 0 "Disabled" 1 "VREF" 2 "HighSide" 3 "LowSide" 4 "InputOnly" 5 "Bridge" 14 "Error" 15 "Not Available" ;
VAL_ 2582846974 PinPullModeStatus_23 0 "None" 1 "PullDown" 2 "PullUp" 3 "Not Available" ;
VAL_ 2582846974 LoadDetectionStatus_23 0 "Off" 1 "On" 2 "Error" 3 "Not Available" ;
VAL_ 2582846974 PinModeStatus_24 0 "Disabled" 1 "VREF" 2 "HighSide" 3 "LowSide" 4 "InputOnly" 5 "Bridge" 14 "Error" 15 "Not Available" ;
VAL_ 2582846974 PinPullModeStatus_24 0 "None" 1 "PullDown" 2 "PullUp" 3 "Not Available" ;
VAL_ 2582846974 LoadDetectionStatus_24 0 "Off" 1 "On" 2 "Error" 3 "Not Available" ;
VAL_ 2582846974 PinModeStatus_25 0 "Disabled" 1 "VREF" 2 "HighSide" 3 "LowSide" 4 "InputOnly" 5 "Bridge" 14 "Error" 15 "Not Available" ;
VAL_ 2582846974 PinPullModeStatus_25 0 "None" 1 "PullDown" 2 "PullUp" 3 "Not Available" ;
VAL_ 2582846974 LoadDetectionStatus_25 0 "Off" 1 "On" 2 "Error" 3 "Not Available" ;
VAL_ 2582846974 PinModeStatus_26 0 "Disabled" 1 "VREF" 2 "HighSide" 3 "LowSide" 4 "InputOnly" 5 "Bridge" 14 "Error" 15 "Not Available" ;
VAL_ 2582846974 PinPullModeStatus_26 0 "None" 1 "PullDown" 2 "PullUp" 3 "Not Available" ;
VAL_ 2582846974 LoadDetectionStatus_26 0 "Off" 1 "On" 2 "Error" 3 "Not Available" ;
VAL_ 2582846974 PinModeStatus_27 0 "Disabled" 1 "VREF" 2 "HighSide" 3 "LowSide" 4 "InputOnly" 5 "Bridge" 14 "Error" 15 "Not Available" ;
VAL_ 2582846974 PinPullModeStatus_27 0 "None" 1 "PullDown" 2 "PullUp" 3 "Not Available" ;
VAL_ 2582846974 LoadDetectionStatus_27 0 "Off" 1 "On" 2 "Error" 3 "Not Available" ;
VAL_ 2582846974 PinModeStatus_28 0 "Disabled" 1 "VREF" 2 "HighSide" 3 "LowSide" 4 "InputOnly" 5 "Bridge" 14 "Error" 15 "Not Available" ;
VAL_ 2582846974 PinPullModeStatus_28 0 "None" 1 "PullDown" 2 "PullUp" 3 "Not Available" ;
VAL_ 2582846974 LoadDetectionStatus_28 0 "Off" 1 "On" 2 "Error" 3 "Not Available" ;
VAL_ 2582846974 PinModeStatus_29 0 "Disabled" 1 "VREF" 2 "HighSide" 3 "LowSide" 4 "InputOnly" 5 "Bridge" 14 "Error" 15 "Not Available" ;
VAL_ 2582846974 PinPullModeStatus_29 0 "None" 1 "PullDown" 2 "PullUp" 3 "Not Available" ;
VAL_ 2582846974 LoadDetectionStatus_29 0 "Off" 1 "On" 2 "Error" 3 "Not Available" ;
VAL_ 2582846974 PinModeStatus_30 0 "Disabled" 1 "VREF" 2 "HighSide" 3 "LowSide" 4 "InputOnly" 5 "Bridge" 14 "Error" 15 "Not Available" ;
VAL_ 2582846974 PinPullModeStatus_30 0 "None" 1 "PullDown" 2 "PullUp" 3 "Not Available" ;
VAL_ 2582846974 LoadDetectionStatus_30 0 "Off" 1 "On" 2 "Error" 3 "Not Available" ;
VAL_ 2582846974 PinModeStatus_31 0 "Disabled" 1 "VREF" 2 "HighSide" 3 "LowSide" 4 "InputOnly" 5 "Bridge" 14 "Error" 15 "Not Available" ;
VAL_ 2582846974 PinPullModeStatus_31 0 "None" 1 "PullDown" 2 "PullUp" 3 "Not Available" ;
VAL_ 2582846974 LoadDetectionStatus_31 0 "Off" 1 "On" 2 "Error" 3 "Not Available" ;
VAL_ 2582846974 PinModeStatus_32 0 "Disabled" 1 "VREF" 2 "HighSide" 3 "LowSide" 4 "InputOnly" 5 "Bridge" 14 "Error" 15 "Not Available" ;
VAL_ 2582846974 PinPullModeStatus_32 0 "None" 1 "PullDown" 2 "PullUp" 3 "Not Available" ;
VAL_ 2582846974 LoadDetectionStatus_32 0 "Off" 1 "On" 2 "Error" 3 "Not Available" ;
VAL_ 2582847998 QEncoderDirection_Q01 0 "Stopped" 1 "Forward" 2 "Reverse" 3 "NotAvailable" ;
